VERSION ""

NS_ :

BS_:

BU_: TCU_FB5 RFA_BLEM GWM _delete GENERIC TSTR
VAL_TABLE_ PaaKMyKeyChng_D_Stat 3 "NotUsed" 2 "ClearAll" 1 "MyKey" 0 "Null" ;
VAL_TABLE_ VehOnSrc_D_Stat 15 "NotUsed_11" 14 "NotUsed_10" 13 "NotUsed_9" 12 "NotUsed_8" 11 "NotUsed_7" 10 "NotUsed_6" 9 "EsclRssd" 8 "AutonomousVehicle" 7 "SecureIdle" 6 "FleetVehicleInhibit" 5 "StolenVehicleInhibit" 4 "OverTheAir" 3 "RemoteParkAssist" 2 "RemoteStart" 1 "Manual" 0 "Off" ;
VAL_TABLE_ PaakAddErase_D_Rq 3 "EraseAll" 2 "Erase" 1 "Add" 0 "Null" ;
VAL_TABLE_ KeyPadCodeProg_D_Rq 7 "NotUsed_3" 6 "NotUsed_2" 5 "NotUsed_1" 4 "DeleteAll" 3 "Delete" 2 "Add" 1 "ProgrammingMode" 0 "Null" ;
VAL_TABLE_ KeyPadCodeProg_D_Stat 7 "NotUsed_2" 6 "Duplicate" 5 "ProgrammingFailure" 4 "DeleteAll" 3 "Delete" 2 "Add" 1 "LearningMode" 0 "NormalMode" ;
VAL_TABLE_ FobTrgtZone_D_Rq 15 "NotUsed_9" 14 "NotUsed_8" 13 "NotUsed_7" 12 "NotUsed_6" 11 "NotUsed_5" 10 "NotUsed_4" 9 "NotUsed_3" 8 "NotUsed_2" 7 "NotUsed_1" 6 "Approach" 5 "RearInterior" 4 "RearExterior" 3 "Passenger" 2 "Driver" 1 "Interior" 0 "Null" ;
VAL_TABLE_ FobTrgtType_D_Rq 7 "NotUsed_4" 6 "NotUsed_3" 5 "NotUsed_2" 4 "NotUsed_1" 3 "Polling" 2 "Registry" 1 "Crypto" 0 "Null" ;
VAL_TABLE_ ModemReset_D_Rq 15 "NotUsed_11" 14 "NotUsed_10" 13 "NotUsed_9" 12 "NotUsed_8" 11 "NotUsed_7" 10 "NotUsed_6" 9 "NotUsed_5" 8 "NotUsed_4" 7 "NotUsed_3" 6 "BrandConnectReset2" 5 "BrandConnectReset1" 4 "CcsReset" 3 "OnlineTrafficReset" 2 "PaakReset" 1 "WifiHotspotReset" 0 "Null" ;
VAL_TABLE_ RstrnOnPsngr_D_RqMnu 15 "Faulty" 14 "NotUsed_11" 13 "NotUsed_10" 12 "ConfiguredOff" 11 "NotUsed_9" 10 "On" 9 "NotUsed_8" 8 "NotUsed_7" 7 "NotUsed_6" 6 "NotUsed_5" 5 "Off" 4 "NotUsed_4" 3 "NotUsed_3" 2 "NotUsed_2" 1 "NotUsed_1" 0 "NoAction" ;
VAL_TABLE_ Null_NotAvail_Avail 3 "NotUsed" 2 "Available" 1 "NotAvailable" 0 "Null" ;
VAL_TABLE_ DcacFaltMsgTxt_D2_Rq 63 "NotUsed_47" 17 "NotUsed_1" 16 "HevDerate" 15 "HvacOn" 14 "OvercurrentLP" 13 "EngineRun" 12 "Service" 11 "NotAvailable" 10 "PlugWarn" 9 "PlugWarnDrive" 8 "BreakerC" 7 "BreakerB" 6 "BreakerA" 5 "FuelLow" 4 "AcOnOutput" 3 "Temperature" 2 "Gfci" 1 "Overcurrent" 0 "Ok" ;
VAL_TABLE_ NotAvail_OffOn_Faulty 3 "Faulty" 2 "On" 1 "Off" 0 "NotAvailable" ;
VAL_TABLE_ RmtCtlPathPlan_D_Stat 7 "NotUsed_3" 6 "NotUsed_2" 5 "NotUsed_1" 4 "FinishedMovesExceeded" 3 "FinishedDistanceExceeded" 2 "Finished" 1 "Ongoing" 0 "None" ;
VAL_TABLE_ RmtCtlConfgSrc_D_Stat 7 "NotUsed_2" 6 "NotUsed_1" 5 "BPO" 4 "ApaHmi" 3 "FAP_Handover" 2 "User" 1 "None" 0 "NotDetermined" ;
VAL_TABLE_ RmtCtlAdas_D_Stat 7 "Paused" 6 "Abort" 5 "ManeuverFinished" 4 "EndPositionReached" 3 "Backward" 2 "Forward" 1 "ManeuverBegin" 0 "Inactive" ;
VAL_TABLE_ RmtCtlOrientAvail_D_ET 7 "NotUsed_3" 6 "NotUsed_2" 5 "NotUsed_1" 4 "Both" 3 "Backward" 2 "Forward" 1 "None" 0 "NotDetermined" ;
VAL_TABLE_ PrkMde_D_ET 3 "NotUsed" 2 "FreeDrive" 1 "ParkIn" 0 "None" ;
VAL_TABLE_ RmtCtlPrkInSlot_D_ET 7 "NotUsed_3" 6 "NotUsed_2" 5 "NotUsed_1" 4 "Right" 3 "Left" 2 "Rear" 1 "Front" 0 "None" ;
VAL_TABLE_ Orientation_D_ET 3 "NotUsed" 2 "Backward" 1 "Forward" 0 "Null" ;
VAL_TABLE_ MoveDir_D_ET 3 "NotUsed" 2 "Backward" 1 "Forward" 0 "None" ;
VAL_TABLE_ RmtCtlSns_D_Stat 3 "Zone3" 2 "Zone2" 1 "Zone1" 0 "Off" ;
VAL_TABLE_ ApaMsgTxt_D2_Stat 15 "ReducedFunction" 14 "TrailerFeatureNotAvailable" 13 "AcceleratorPedalInactive" 12 "SensorsBlocked" 11 "TrailerAttached" 10 "TcsDeactivated" 9 "WheelSlip" 8 "HighInclination" 7 "DoorOpen" 6 "SteeringInteraction" 5 "WrongDirection" 4 "SpeedLimitExceeded" 3 "BrakeEvent" 2 "ObstacleInPath" 1 "WaitForSteering" 0 "None" ;
VAL_TABLE_ ApaDrvRq1MsgTxt_D_Rq 7 "NotUsed" 6 "ExitVehicle" 5 "PressApaButton" 4 "ShiftToP" 3 "ShiftToN" 2 "ShiftToD" 1 "ShiftToR" 0 "NoRequest" ;
VAL_TABLE_ DisplayMode 3 "NotUsed" 2 "FullScreen" 1 "Menu" 0 "Off" ;
VAL_TABLE_ ApaSys_D2_Stat 15 "NotUsed_5" 14 "NotUsed_4" 13 "NotUsed_3" 12 "NotUsed_2" 11 "NotUsed_1" 10 "NoSideSelectable" 9 "RightSideSelectable" 8 "LeftSideSelectable" 7 "BothSidesSelectable" 6 "Faulty" 5 "Finished" 4 "Cancelled" 3 "NotAvailable" 2 "Overspeed" 1 "Pause" 0 "NormalOperation" ;
VAL_TABLE_ ApaDrvRq2MsgTxt_D_Rq 15 "NotUsed_7" 14 "NotUsed_6" 13 "NotUsed_5" 12 "NotUsed_4" 11 "NotUsed_3" 10 "NotUsed_2" 9 "NotUsed_1" 8 "CloseDoor" 7 "TakeControl" 6 "ReleaseEpb" 5 "ReleaseSteering" 4 "ReleaseBrake" 3 "DriveBackward" 2 "DriveForward" 1 "Stop" 0 "NoRequest" ;
VAL_TABLE_ ApaSlotTrgt_D_Stat 15 "NotUsed_7" 14 "NotUsed_6" 13 "NotUsed_5" 12 "NotUsed_4" 11 "NotUsed_3" 10 "NotUsed_2" 9 "NotUsed_1" 8 "Front" 7 "Rear" 6 "Right3" 5 "Right2" 4 "Right1" 3 "Left3" 2 "Left2" 1 "Left1" 0 "None" ;
VAL_TABLE_ ChrgStat_D2_Dsply 15 "ChargeStopCommanded" 14 "ChargeStartCommanded" 13 "ChargeTargetReached" 12 "DriveConditioning" 11 "CabinPreconditioning" 10 "ChargingSystemMaintain" 9 "ChargingInductive" 8 "ChargingDCFastCharge" 7 "ChargingAC" 6 "ChargeScheduled" 5 "EvsePaused" 4 "EvseNotDetected" 3 "EvseNotCompatible" 2 "FaultOutsideCar" 1 "FaultInsideCar" 0 "NotReady" ;
VAL_TABLE_ NoRequest_Mode1_2_3 3 "Mode_3" 2 "Mode_2" 1 "Mode_1" 0 "NoRequest" ;
VAL_TABLE_ Off_On_NotUsed 3 "NotUsed_2" 2 "NotUsed_1" 1 "On" 0 "Off" ;
VAL_TABLE_ Mtr2State_D_ActlMntr 7 "Faulty" 6 "NoDataExists" 5 "NotUsed_1" 4 "ReadinessState" 3 "DeactivationState" 2 "PowerGeneration" 1 "PowerConsumption" 0 "Null" ;
VAL_TABLE_ HybVehMde_D_ActlMntr 7 "Faulty" 6 "NoDataExists" 5 "NotUsed_2" 4 "NotUsed_1" 3 "Fuel" 2 "HybridElectric" 1 "AllElectric" 0 "Null" ;
VAL_TABLE_ ChrgStat_D_ActlMntr 7 "Faulty" 6 "NoDataExists" 5 "NotUsed" 4 "ChargingCompleted" 3 "NotCharging" 2 "ChargingInDrivingState" 1 "ChargingInParkingState" 0 "Null" ;
VAL_TABLE_ Inactive_Enable_Disable_NotUsed 0 "Inactive" 2 "Disable" 1 "Enable" ;
VAL_TABLE_ TrailCtl_D_Stat 7 "Faulty" 6 "DescentOnly" 5 "EnabledDeny" 4 "StandbyOverThreshold" 3 "StandbyOverride" 2 "Active" 1 "EnabledDescent" 0 "Off" ;
VAL_TABLE_ ChrgOvrdExitScrn_D_Rq 3 "NotUsed_1" 2 "Request_override" 1 "Do_not_request_override" 0 "Inactive" ;
VAL_TABLE_ PaakTrgtType_D_Rq 7 "NotUsed_4" 6 "NotUsed_3" 5 "NotUsed_2" 4 "NotUsed_1" 3 "Polling" 2 "Registry" 1 "Crypto" 0 "Null" ;
VAL_TABLE_ PaakTrgtZone_D_Rq 15 "NotUsed_9" 14 "NotUsed_8" 13 "NotUsed_7" 12 "NotUsed_6" 11 "NotUsed_5" 10 "NotUsed_4" 9 "NotUsed_3" 8 "NotUsed_2" 7 "NotUsed_1" 6 "Approach" 5 "RearInterior" 4 "RearExterior" 3 "Passenger" 2 "Driver" 1 "Interior" 0 "Null" ;
VAL_TABLE_ PaakTrgtData_D_Rq 5 "NotUsed_2" 4 "Not_Used1" 3 "Target1_IdBlock2" 2 "Target1_IdBlock1" 1 "Challenge" 0 "Idle" 7 "NotUsed_4" 6 "NotUsed_3" ;
VAL_TABLE_ PaakCtlActv_D_Rq 31 "NotUsed_13" 30 "NotUsed_12" 29 "NotUsed_11" 28 "NotUsed_10" 27 "NotUsed_9" 26 "NotUsed_8" 25 "NotUsed_7" 24 "NotUsed_6" 23 "NotUsed_5" 22 "NotUsed_4" 21 "NotUsed_3" 20 "TrunkFrontRelease" 19 "RemoteStop" 18 "RemoteStart" 17 "PowerDecklid" 16 "RightPowerSlidingDoor" 15 "LeftPowerSlidingDoor" 14 "PowerLiftgate" 13 "GlobalClose" 12 "GlobalOpen" 11 "PanicOff" 10 "PanicOn" 9 "LiftgateGlassRelease" 8 "LiftgateRelease" 7 "DecklidRelease" 6 "DoubleLock" 5 "LockAll" 4 "UnlockAllDoorsPlusCargo" 3 "UnlockCargoDoor" 2 "UnlockAllDoors" 1 "UnlockDriverDoor" 0 "Null" ;
VAL_TABLE_ Null_Invalid_Valid 3 "NotUsed" 2 "Valid" 1 "Invalid" 0 "Null" ;
VAL_TABLE_ PaakCtlData_D_Stat 7 "NotUsed_3" 6 "NotUsed_2" 5 "NotUsed_1" 4 "Response" 3 "EchoTargetIdBlock1" 2 "RequestTargetIdBlock2" 1 "RequestTargetIdBlock1" 0 "Idle" ;
VAL_TABLE_ NoInhibit_Inhibit 1 "Inhibit" 0 "NoInhibit" ;
VAL_TABLE_ Disp_LangSel2_Rq 32 "Indian_English" 31 "Thai" 30 "Slovak" 29 "Arabic" 28 "Taiwanese" 27 "Mandarin_Chinese" 26 "Korean" 25 "AU_English" 24 "Japanese" 23 "Braz_Portuguese" 22 "EU_Portuguese" 21 "Finish" 20 "Norwegian" 19 "Danish" 18 "Swedish" 17 "Hungarian" 16 "Greek" 15 "Czech" 14 "Polish" 13 "Flemish" 12 "Dutch" 11 "Russian" 10 "Turkish" 9 "Mex_Spanish" 8 "EU_Spanish" 7 "Cana_French" 6 "EU_French" 5 "Italian" 4 "German" 3 "NA_English" 2 "UK_English" 1 "Unknown" 0 "Invalid" ;
VAL_TABLE_ LongTermParking_Rq 2 "On" 1 "Off" 0 "Inactive" ;
VAL_TABLE_ Null_Extend_Retract 3 "NotUsed" 2 "Retract" 1 "Extend" 0 "Null" ;
VAL_TABLE_ VehInhbtMde_D_Stat 7 "NotUsed_3" 6 "NotUsed_2" 5 "NotUsed_1" 4 "FullVehicleOta" 3 "Iviota" 2 "SyncOta" 1 "NoOtaSupport" 0 "Unconfigured" ;
VAL_TABLE_ PaakLoclzd_D_Stat 15 "NotUsed_12" 14 "NotUsed_11" 13 "NotUsed_10" 12 "NotUsed_9" 11 "NotUsed_8" 10 "NotUsed_7" 9 "NotUsed_6" 8 "NotUsed_5" 7 "NotUsed_4" 6 "NotUsed_3" 5 "NotUsed_2" 4 "NotUsed_1" 3 "FullLoc" 2 "PausedLoc" 1 "MaintainLink" 0 "BackgroundScan" ;
VAL_TABLE_ KeyPadCodeDgt1_D_Stat 15 "NotUsed_4" 14 "NotUsed_3" 13 "NotUsed_2" 12 "NotUsed_1" 11 "Button7_8and9_0" 10 "Button0" 9 "Button9_0or9" 8 "Button8" 7 "Button7_8or7" 6 "Button6" 5 "Button5_6or5" 4 "Button4" 3 "Button3_4or3" 2 "Button2" 1 "Button1_2or1" 0 "EndofString" ;
VAL_TABLE_ SelDrvMdeChassis2_D_Rq 31 "Faulty" 30 "NotUsed17" 29 "NotUsed16" 28 "NotUsed15" 27 "NotUsed14" 26 "NotUsed13" 25 "NotUsed12" 24 "NotUsed11" 23 "NotUsed10" 22 "NotUsed9" 21 "NotUsed8" 20 "NotUsed7" 19 "NotUsed6" 18 "NotUsed5" 17 "NotUsed4" 16 "OnePedalDrive" 15 "DragMode" 14 "RoughRoadMode" 13 "TrackMode" 12 "HighSpeedDesertMode" 11 "TowHaulMode" 10 "RockCrawlMode" 9 "SandMode" 8 "MudAndRutsMode" 7 "LowMuMode" 6 "ComfortAdaptiveMode" 5 "ComfortMode" 4 "SportAdaptiveMode" 3 "SportMode" 2 "EconomyMode" 1 "NormalAdaptiveMode" 0 "NormalMode" ;
VAL_TABLE_ TelematicsSrvc_D_St 7 "NotUsed" 6 "NotifyNotActivatedYet" 5 "NotActivatedYet" 4 "NotifyExpired" 3 "Expired" 2 "ExpiringSoon" 1 "Active" 0 "Null" ;
VAL_TABLE_ TCU_ESN_D_Rq 3 "NotUsed" 2 "TCU_ESN_Request" 1 "NoRequest" 0 "Inactive" ;
VAL_TABLE_ FactoryReset_Rq 1 "ResetFactoryDefaults" 0 "Inactive" ;
VAL_TABLE_ Telematics_D_Falt 7 "NotUsed_5" 6 "NotUsed_4" 5 "NotUsed_3" 4 "NotUsed_2" 3 "NotUsed_1" 2 "RunTimeError" 1 "ChipsetInitializationFailu" 0 "Null" ;
VAL_TABLE_ Null_NotConnected_Conn 3 "NotUsed" 2 "Connected" 1 "NotConnected" 0 "Null" ;
VAL_TABLE_ Null_Disable_Enable 3 "NotUsed" 2 "Enable" 1 "Disable" 0 "Null" ;
VAL_TABLE_ UltraFreshCabn_D_Stat 7 "NotUsed_2" 6 "NotUsed_1" 5 "NotSupported" 4 "Interrupted" 3 "Complete" 2 "Active" 1 "Inactive" 0 "Null" ;
VAL_TABLE_ WifiHtsptTrial_D_RqDrv 3 "NotUsed_1" 2 "StopReminders" 1 "RemindMeLater" 0 "Null" ;
VAL_TABLE_ ModemTechnology_D2_Stat 7 "Lte" 6 "HspaPlus" 5 "Umts" 4 "Edge" 3 "Gprs" 2 "Gsm" 1 "NoNetwork" 0 "Null" ;
VAL_TABLE_ NoData_Faulty_3FFE_3FFF 16383 "Faulty" 16382 "NoDataExists" ;
VAL_TABLE_ EmgcyCall_D_Stat 7 "NotUsed_3" 6 "NotUsed_2" 5 "NotUsed_1" 4 "ManualEmergencyCall" 3 "AutoEmergencyCall" 2 "NoEvent" 1 "EmergencyCallNotSupported" 0 "Null" ;
VAL_TABLE_ GearLvr_D_ActlDrv 15 "Fault" 14 "Unknown_Position" 13 "NotUsed_2" 12 "NotUsed_1" 11 "Range6" 10 "Range5" 9 "Range4" 8 "Range3_M3_L3" 7 "Range2_M2_L2" 6 "Range1_M1_L1" 5 "Low" 4 "Sport_DriveSport_Mposition" 3 "Drive" 2 "Neutral" 1 "Reverse" 0 "Park" ;
VAL_TABLE_ TrnPrkSys_D_Actl 15 "Faulty" 14 "NotUsed_5" 13 "NotUsed_4" 12 "NotUsed_3" 11 "NotUsed_2" 10 "NotUsed_1" 9 "FrequencyError" 8 "OutOfRangeHigh" 7 "OutOfRangeLow" 6 "Override" 5 "OutOfPark" 4 "TransitionCloseToOutOfPark" 3 "AtNoSpring" 2 "TransitionCloseToPark" 1 "Park" 0 "NotKnown" ;
VAL_TABLE_ OKLowUnknownInvalid 3 "Invalid" 2 "Unknown" 1 "Low" 0 "OK" ;
VAL_TABLE_ PrkAidDrvDir_D_Stat 7 "NotUsed_2" 6 "NotUsed_1" 5 "BackwardNegative" 4 "ForwardNegative" 3 "BackwardPositive" 2 "ForwardPositive" 1 "NoMotion" 0 "DirectionNotKnown" ;
VAL_TABLE_ EmgcyCallHmi_D_Stat 15 "NotUsed_1" 14 "Standby" 13 "Disabled" 12 "Malfunction" 11 "CallCompleted" 10 "CallDisconnected" 9 "CallNotPossible" 8 "CallCancelled" 7 "CallRetry" 6 "CallConnected" 5 "CallInProgress" 4 "CallMsdTransfer" 3 "CallDial" 2 "CallCancelTimer" 1 "NoEvent" 0 "Null" ;
VAL_TABLE_ EmgcyCallMute_D_Stat 7 "NotUsed4" 6 "NotUsed3" 5 "NotUsed2" 4 "NotUsed1" 3 "ManualEmergencyCallMute" 2 "AutomaticEmergencyCallMute" 1 "EmergencyCallUnmute" 0 "Null" ;
VAL_TABLE_ WifiHtsptEnbl_D_Rq 3 "Not used" 2 "On" 1 "Off" 0 "Null" ;
VAL_TABLE_ WifiHtsptVisbl_D_Rq 3 "Not used" 2 "On" 1 "Off" 0 "Null" ;
VAL_TABLE_ WifiRemoveDevc_D_Rq 3 "NotUsed_1" 2 "FromBlockedList" 1 "FromConnectedList" 0 "Null" ;
VAL_TABLE_ WifiHtsptEnbl_D_Stat 3 "OnDisabled" 2 "On" 1 "Off" 0 "Null" ;
VAL_TABLE_ WifiDevcListNew_B_Stat 1 "Available" 0 "NotAvailable" ;
VAL_TABLE_ WifiHtsptScrty_D_Rq 3 "NotUsed_1" 2 "Wapi" 1 "Wpa2_Wpa" 0 "Null" ;
VAL_TABLE_ WifiDevcList_D_Rq 3 "NoEntry" 2 "BlockedList" 1 "ConnectedList" 0 "Null" ;
VAL_TABLE_ WifiCarrierInfo_B_Rq 1 "Request" 0 "No  request" ;
VAL_TABLE_ WifiHtsptScrty_D_Stat 3 "NotUsed_1" 2 "Wapi" 1 "Wpa2_Wpa" 0 "Null" ;
VAL_TABLE_ WifiDataUsage_D_Rq 3 "RetriveDataFromBackend" 2 "RefreshData" 1 "CurrentData" 0 "Null" ;
VAL_TABLE_ WifiHtsptVisbl_D_Stat 3 "Not  used" 2 "On" 1 "Off" 0 "Null" ;
VAL_TABLE_ ModemSigStren_D_Stat 7 "NotUsed_1" 6 "NotDetermined" 5 "FiveBars" 4 "FourBars" 3 "ThreeBars" 2 "TwoBars" 1 "OneBar" 0 "ZeroBars" ;
VAL_TABLE_ WifiHtsptMacAddr_B_Rq 1 "Request" 0 "No request" ;
VAL_TABLE_ WifiDataUsage_D_Stat 3 "PercentDataUsed" 2 "DataPlanExpired" 1 "FreeTrialPeriodWaiting" 0 "Null" ;
VAL_TABLE_ Closed_Open_Active_Denied 3 "Denied" 2 "Active" 1 "Open" 0 "Closed" ;
VAL_TABLE_ Fault_Occupied_Empty_Un 3 "Unknown" 2 "Empty" 1 "Occupied" 0 "Fault" ;
VAL_TABLE_ KeyOffMde_D_Actl 15 "NotUsed_11" 14 "NotUsed_10" 13 "NotUsed_9" 12 "NotUsed_8" 11 "NotUsed_7" 10 "NotUsed_6" 9 "NotUsed_5" 8 "NotUsed_4" 7 "NotUsed_3" 6 "NotUsed_2" 5 "NotUsed_1" 4 "CriticalBattery" 3 "Hibernate" 2 "Transport" 1 "Factory" 0 "Normal" ;
VAL_TABLE_ SelDrvMdeAwd_D_Rq 31 "Faulty" 30 "NotUsed_17" 29 "NotUsed_16" 28 "NotUsed_15" 27 "NotUsed_14" 26 "NotUsed_13" 25 "NotUsed_12" 24 "NotUsed_11" 23 "NotUsed_10" 22 "NotUsed_9" 21 "NotUsed_8" 20 "CustomMode" 19 "OnePedalDrive" 18 "DragMode" 17 "EvLaterChargeMode" 16 "EvNowMode" 15 "TrackMode" 14 "RoughRoadMode" 13 "NotAvailable" 12 "HighSpeedDesertMode_Baja" 11 "SportAdaptiveMode" 10 "RockCrawlMode" 9 "MudRutsMode" 8 "SandMode" 7 "EconomyMode" 6 "GrassGravelSnow" 5 "TowHaulMode" 4 "SportMode" 3 "Normal_4L" 2 "Normal_4A" 1 "Normal_2H" 0 "NormalMode" ;
VAL_TABLE_ SelDrvMdePt_D_Rq 31 "Faulty" 30 "NotUsed15" 29 "NotUsed14" 28 "NotUsed13" 27 "NotUsed12" 26 "NotUsed11" 25 "NotUsed10" 24 "NotUsed9" 23 "NotUsed8" 22 "NotUsed7" 21 "CustomMode" 20 "TrackMode" 19 "OnePedalDrive" 18 "EvLaterChargerMode" 17 "EvNowMode" 16 "DragMode" 15 "HighSpeedDesertMode_Baja" 14 "SportAdaptiveMode" 13 "NotAvailable_13" 12 "NotAvailable_12" 11 "NotAvailable_11" 10 "NotAvailable_10" 9 "RockCrawlMode" 8 "MudRutsMode" 7 "SandMode" 6 "EconomyMode" 5 "GrassGravelSnow" 4 "NotAvailable_04" 3 "TowHaulMode" 2 "NotAvailable_02" 1 "SportMode" 0 "NormalMode" ;
VAL_TABLE_ OffOnOutOfRange 3 "NotUsed" 2 "OutOfRange" 1 "On" 0 "Off" ;
VAL_TABLE_ NoMessage_Msg1_15 15 "Message15" 14 "Message14" 13 "Message13" 12 "Message12" 11 "Message11" 10 "Message10" 9 "Message9" 8 "Message8" 7 "Message7" 6 "Message6" 5 "Message5" 4 "Message4" 3 "Message3" 2 "Message2" 1 "Message1" 0 "NoMessage" ;
VAL_TABLE_ SelDrvMdeChassis_D_Rq 31 "Faulty" 30 "NotUsed17" 29 "NotUsed16" 28 "NotUsed15" 27 "NotUsed14" 26 "NotUsed13" 25 "NotUsed12" 24 "NotUsed11" 23 "NotUsed10" 22 "NotUsed9" 21 "NotUsed8" 20 "NotUsed7" 19 "NotUsed6" 18 "NotUsed5" 17 "NotUsed4" 16 "OnePedalDrive" 15 "DragMode" 14 "RoughRoadMode" 13 "TrackMode" 12 "HighSpeedDesertMode" 11 "TowHaulMode" 10 "RockCrawlMode" 9 "SandMode" 8 "MudAndRutsMode" 7 "LowMuMode" 6 "ComfortAdaptiveMode" 5 "ComfortMode" 4 "SportAdaptiveMode" 3 "SportMode" 2 "EconomyMode" 1 "NormalAdaptiveMode" 0 "NormalMode" ;
VAL_TABLE_ NotAvailable_Available 1 "Available" 0 "NotAvailable" ;
VAL_TABLE_ ApaBrk_D_Stat 3 "Denied" 2 "Active" 1 "Open" 0 "Closed" ;
VAL_TABLE_ Off_On_Unknown_Invalid 3 "Invalid" 2 "Unknown" 1 "On" 0 "Off" ;
VAL_TABLE_ BrkBstrVac_D_Stat 3 "NotUsed" 2 "BoosterVacEstimator" 1 "BoosterVacSensor" 0 "NoBoosterVacuumMonitor" ;
VAL_TABLE_ PrkBrkMsgTxt_D_Rq 15 "Message15" 14 "Message14" 13 "Message13" 12 "Message12" 11 "Message11" 10 "Message10" 9 "Message9" 8 "Message8" 7 "Message7" 6 "Message6" 5 "Message5" 4 "Message4" 3 "Message3" 2 "Message2" 1 "Message1" 0 "No_Message" ;
VAL_TABLE_ AutoHoldMsgTxt_D_Rq 15 "Message15" 14 "Message14" 13 "Message13" 12 "Message12" 11 "Message11" 10 "Message10" 9 "Message9" 8 "Message8" 7 "Message7" 6 "Message6" 5 "Message5" 4 "Message4" 3 "Message3" 2 "Message2" 1 "Message1" 0 "NoMessage" ;
VAL_TABLE_ AutoHoldMde_D_Ind 3 "Indication_3" 2 "Indication_2" 1 "Indication_1" 0 "Off" ;
VAL_TABLE_ BrkPadMsgTxt_D_Rq 3 "Faulty" 2 "PadsOk" 1 "ReplacePads" 0 "Null" ;
VAL_TABLE_ LsmcBrkDecel_D_Stat 7 "NotUsed_3" 6 "NotUsed_2" 5 "NotUsed_1" 4 "Denied" 3 "FaultDegraded" 2 "FaultExt" 1 "On" 0 "Off" ;
VAL_TABLE_ BrkLineLck_D_Stat 7 "NotUsed_3" 6 "NotUsed_2" 5 "NotUsed_1" 4 "NotAvailable" 3 "Off" 2 "Engaged" 1 "Initiated" 0 "Available" ;
VAL_TABLE_ BrkDrvMde_D_Rq 7 "Faulty" 6 "RockCrawl" 5 "Baja" 4 "DragOrMudAndSand" 3 "Track" 2 "Snow_Wet" 1 "Sport" 0 "Normal" ;
VAL_TABLE_ NoYesNoDataFaulty 3 "Faulty" 2 "NoDataExists" 1 "Yes" 0 "No" ;
VAL_TABLE_ Null_Off_On 3 "NotUsed" 2 "On" 1 "Off" 0 "Null" ;
VAL_TABLE_ TrlrAidMsgTxt_D_Rq 31 "Message31" 30 "Message30" 29 "Message29" 28 "Message28" 27 "Message27" 26 "Message26" 25 "Message25" 24 "Message24" 23 "Message23" 22 "Message22" 21 "Message21" 20 "Message20" 19 "Message19" 18 "Message18" 17 "Message17" 16 "Message16" 15 "Message15" 14 "Message14" 13 "Message13" 12 "Message12" 11 "Message11" 10 "Message10" 9 "Message9" 8 "Message8" 7 "Message7" 6 "Message6" 5 "Message5" 4 "Message4" 3 "Message3" 2 "Message2" 1 "Message1" 0 "NoMessage" ;
VAL_TABLE_ Invalid_7F 127 "Invalid" ;
VAL_TABLE_ VehStab_D_Stat 15 "Faulty" 14 "No_Data_Exists" 13 "NotUsed6" 12 "NotUsed5" 11 "NotUsed4" 10 "NotUsed3" 9 "NotUsed2" 8 "Combined_OS_and_US" 7 "High_SSRA_no_OS" 6 "Straight" 5 "Post_Oversteer" 4 "Post_Transition" 3 "Countersteer" 2 "Understeer" 1 "Oversteer" 0 "Linear" ;
VAL_TABLE_ DieslPrtc2_D_RqDsply 15 "NotUsed4" 14 "NotUsed3" 13 "NotUsed2" 12 "NotUsed1" 11 "OCR_ExhFilterClean_Stopped" 10 "OCR_ExhFilterCleaned" 9 "RgnOff_AtLimit" 8 "RgnOff_Overloaded" 7 "RgnOff_Loaded" 6 "Exhaust_Filter_Full" 5 "DPF_Overlimit" 4 "DPF_AtLimit" 3 "ExhFilter_Drive_Completed" 2 "Cleaning_Exhaust_Filter" 1 "DPF_Overloaded" 0 "DPF_Normal_Operation" ;
VAL_TABLE_ NoData_Faulty_3E_3F 63 "Faulty" 62 "NoDataExists" ;
VAL_TABLE_ NoData_Faulty_1FFF_1FFE 8191 "Faulty" 8190 "NoDataExists" ;
VAL_TABLE_ TrnSrvcRqd_B_Rq 1 "On" 0 "Off" ;
VAL_TABLE_ NoData_Faulty_FE_FF 255 "Faulty" 254 "NoDataExists" ;
VAL_TABLE_ HvacPrecondRecirc_D_Rq 3 "Last_User_Setting" 2 "Auto" 1 "Recirc" 0 "Outside" ;
VAL_TABLE_ HvacPrecondAC_D_Rq 3 "Last_User_Setting" 2 "Auto" 1 "On" 0 "Off" ;
VAL_TABLE_ HybMdeStat_D_Dsply 7 "NotUsed2" 6 "EV_Charge" 5 "EV_Override" 4 "Forced_EV_Mode" 3 "Forced_Charge_Sustain_Mode" 2 "Auto_Charge_Sustain_Mode" 1 "Auto_Charge_Deplete_Mode" 0 "Null_State" ;
VAL_TABLE_ ConsTipUnitPt_D_Dsply 3 "NotUsed" 2 "FuelEconomy" 1 "Distance" 0 "Percentage" ;
VAL_TABLE_ NoData_Faulty_FFFE_FFFF 65535 "Faulty" 65534 "NoDataExists" ;
VAL_TABLE_ NoData_Faulty_FFE_FFF 4095 "Faulty" 4094 "NoDataExists" ;
VAL_TABLE_ NoData_Faulty_7FFE_7FFF 32767 "Faulty" 32766 "NoDataExists" ;
VAL_TABLE_ NoData_Faulty_3FE_3FF 1023 "Faulty" 1022 "NoDataExists" ;
VAL_TABLE_ RmtCtlBody_D_Stat 15 "NotUsed_6" 14 "NotUsed_5" 13 "NotUsed_4" 12 "NotUsed_3" 11 "NotUsed_2" 10 "NotUsed_1" 9 "Shutdown" 8 "ManeuverFinished" 7 "ReadyForResume" 6 "Pause" 5 "Maneuvering" 4 "ReadyForManeuvering" 3 "Activation" 2 "Initialize" 1 "Preparation" 0 "Disabled" ;
VAL_TABLE_ RmtCtlTrgt_D_Rq 3 "NotUsed" 2 "Null" 1 "RemoteParkAssist" 0 "ManeuverId" ;
VAL_TABLE_ RmtCtl_D_RqBody 7 "NotUsed_2" 6 "NotUsed_1" 5 "Error" 4 "Abort" 3 "PauseKeypad" 2 "PauseHazard" 1 "PauseDoorHandle" 0 "Null" ;
VAL_TABLE_ Null_NoPolling_Polling 3 "NotUsed" 2 "Polling" 1 "NoPolling" 0 "Null" ;
VAL_TABLE_ RmtCtl_D_Stat 15 "Faulty" 14 "NotUsed_5" 13 "NotUsed_4" 12 "NotUsed_3" 11 "NotUsed_2" 10 "NotUsed_1" 9 "Shutdown" 8 "ManeuverFinished" 7 "ReadyForResume" 6 "Pause" 5 "Maneuvering" 4 "ReadyForManeuvering" 3 "Activation" 2 "Initialize" 1 "Preparation" 0 "Disabled" ;
VAL_TABLE_ RmtCtlRngSet_D_Rq 3 "NotUsed" 2 "RangeSetB" 1 "RangeSetA" 0 "None" ;
VAL_TABLE_ OffPendingActiveNotUsed 3 "NotUsed" 2 "Active" 1 "Pending" 0 "Off" ;
VAL_TABLE_ BrkHold_D_Stat 7 "NotUsed_3" 6 "NotUsed_2" 5 "NotUsed_1" 4 "HeldSecondary" 3 "HeldSecure" 2 "Held" 1 "Inactive" 0 "Off" ;
VAL_TABLE_ Null_Left_Right 3 "NotUsed" 2 "Right" 1 "Left" 0 "Null" ;
VAL_TABLE_ NoRequest_Up 1 "Up" 0 "NoRequest" ;
VAL_TABLE_ UpDownNotUsedFaulty 3 "Faulty" 2 "NotUsed" 1 "Down" 0 "Up" ;
VAL_TABLE_ PtWakeReas_D_Stat 15 "NotUsed_9" 14 "NotUsed_8" 13 "NotUsed_7" 12 "NotUsed_6" 11 "NotUsed_5" 10 "NotUsed_4" 9 "NotUsed_3" 8 "NotUsed_2" 7 "NotUsed_1" 6 "ElapsedTime" 5 "ThirdPartyWakeup" 4 "DoorAjar" 3 "EarlyWake" 2 "NonMotiveStart" 1 "MotiveStart" 0 "Null" ;
VAL_TABLE_ ModemAuthrz_D_Stat2 3 "Null" 2 "RemoveKeys" 1 "Authorized" 0 "NotAuthorized" ;
VAL_TABLE_ PaakSerial_D2_Rq2 7 "NotUsed_3" 6 "NotUsed_1" 5 "NotUsed_1" 4 "PresentKeyDelivered" 3 "PresentReadyForKeyDelivery" 2 "PresentBlemProvAlertAck" 1 "PresentUnprovisioned" 0 "NotPresent" ;
VAL_TABLE_ Null_Band1_2 3 "NotUsed_1" 2 "Band_2" 1 "Band_1" 0 "Null" ;
VAL_TABLE_ Null_Error1_15 15 "Error15" 14 "Error14" 13 "Error13" 12 "Error12" 11 "Error11" 10 "Error10" 9 "Error9" 8 "Error8" 7 "Error7" 6 "Error6" 5 "Error5" 4 "Error4" 3 "Error3" 2 "Error2" 1 "Error1" 0 "Null" ;
VAL_TABLE_ WifiHtsptFq_D_Avail 7 "NotUsed_3" 6 "NotUsed_2" 5 "NotUsed_1" 4 "AllAvailable" 3 "Band_2_Only" 2 "Band_1_Only" 1 "AllRestricted" 0 "Null" ;
VAL_TABLE_ OpenClosedRetainDisable 3 "Disable" 2 "Retain" 1 "Closed" 0 "Open" ;
VAL_TABLE_ NoData_Fault_1FF_1FE 511 "Fault" 510 "NoDataExists" ;
VAL_TABLE_ EngIdlShutDown_D_Stat 3 "Not_used" 2 "Engine_Shutdown" 1 "Initiated_Countdown" 0 "Normal_Operation" ;
VAL_TABLE_ StopStrtDrvMde_D_Indic 3 "NotUsed" 2 "StartStop_IndirectDeselect" 1 "StopStart_Deselected" 0 "StopStart_Selected" ;
VAL_TABLE_ NoRequest_Request 1 "Request" 0 "NoRequest" ;
VAL_TABLE_ Fault_FFF_NoData 4094 "NoDataExists" 4095 "Fault" ;
VAL_TABLE_ WindowPosition 7 "Unused2" 6 "Unused1" 5 "Fully_Open" 4 "Bet60Percent_FullyOpen" 3 "Bet10Percent_60Percent" 2 "BetFully_10PercentOpen" 1 "Fully_Closed" 0 "Undefined" ;
VAL_TABLE_ OffOnNoDataUnused 3 "Unused" 2 "NoDataExists" 1 "On" 0 "Off" ;
VAL_TABLE_ Null_False_True 3 "NotUsed" 2 "True" 1 "False" 0 "Null" ;
VAL_TABLE_ NoMessage_DisplayMessage 1 "DisplayMessage" 0 "NoMessage" ;
VAL_TABLE_ EngSrvcRqd_B_Rq 1 "Engine_Service_Required" 0 "No_engine_service_required" ;
VAL_TABLE_ GearRvrse_D_Actl 7 "Fault" 6 "NotUsed_3" 5 "NotUsed_2" 4 "NotUsed_1" 3 "Active_confirmed" 2 "Active_not_confirmed" 1 "Inactive_confirmed" 0 "Inactive_not_confirmed" ;
VAL_TABLE_ SideDetect_BLIS_Off_On 2 "BLIS_On_Second_Warning_ON" 1 "BLIS_On_Second_Warning_OFF" 0 "Off" ;
VAL_TABLE_ False_True 1 "True" 0 "False" ;
VAL_TABLE_ HtrnWarnLamp_B_Dsply 1 "On" 0 "Off" ;
VAL_TABLE_ HtrnSrvcRqd_B_Dsply 1 "On" 0 "Off" ;
VAL_TABLE_ Disp_LangSel_St 31 "Thai" 30 "Slovak" 29 "Arabic" 28 "Taiwanese" 27 "Mandarin_Chinese" 26 "Korean" 25 "AU_English" 24 "Japanese" 23 "Braz_Portuguese" 22 "EU_Portuguese" 21 "Finish" 20 "Norwegian" 19 "Danish" 18 "Swedish" 17 "Hungarian" 16 "Greek" 15 "Czech" 14 "Polish" 13 "Flemish" 12 "Dutch" 11 "Russian" 10 "Turkish" 9 "Mex_Spanish" 8 "EU_Spanish" 7 "Cana_French" 6 "EU_French" 5 "Italian" 4 "German" 3 "NA_English" 2 "UK_English" 1 "Unknown" 0 "Invalid" ;
VAL_TABLE_ HMI_HMIMode_St 7 "NotUsed2" 6 "NotUsed1" 5 "Load_Shed_Active" 0 "Invalid" 1 "OffMode" 2 "On" 3 "Phone" 4 "Climate" ;
VAL_TABLE_ BattChrgInhbt_D_Rq 3 "MaintainTargetSoc" 2 "NotUsed" 1 "InhibitChargingThermal" 0 "Enable_Charging" ;
VAL_TABLE_ NoData_Fault_FFFE_FFFF 65535 "Fault" 65534 "NoDataExists" ;
VAL_TABLE_ Fault_1FFF 8191 "Fault" ;
VAL_TABLE_ StopStrtIODTxt_D_Rq 31 "Message31" 30 "Message30" 29 "Message29" 28 "Message28" 27 "Message27" 26 "Message26" 25 "Message25" 24 "Message24" 23 "Message23" 22 "Message22" 21 "Message21" 20 "Message20" 19 "Message19" 18 "Message18" 17 "Message17" 16 "Message16" 15 "Message15" 14 "Message14" 13 "Message13" 12 "Message12" 11 "Message11" 10 "Message10" 9 "Message9" 8 "Message8" 7 "Message7" 6 "Message6" 5 "Message5" 4 "Message4" 3 "Message3" 2 "Message2" 1 "Message1" 0 "NoMessage" ;
VAL_TABLE_ DrvSte_D_Stat 15 "NotUsed10" 14 "NotUsed9" 13 "NotUsed8" 12 "NotUsed7" 11 "NotUsed6" 10 "NotUsed5" 9 "NotUsed4" 8 "NotUsed3" 7 "NotUsed2" 6 "NotUsed1" 5 "Request_Active" 4 "Ignition_Off" 3 "DSR_in_Normal_Idle_Mode" 2 "EPAS_Comm_Disturbed" 1 "DSR_Request_Not_Applicable" 0 "DSR_Deactivated" ;
VAL_TABLE_ LanguageSelect_St 32 "Indian_English" 31 "Thai" 30 "Slovak" 29 "Arabic" 28 "Taiwanese" 27 "Mandarin_Chinese" 26 "Korean" 25 "AU_English" 24 "Japanese" 23 "Braz_Portuguese" 22 "EU_Portuguese" 21 "Finish" 20 "Norwegian" 19 "Danish" 18 "Swedish" 17 "Hungarian" 16 "Greek" 15 "Czech" 14 "Polish" 13 "Flemish" 12 "Dutch" 11 "Russian" 10 "Turkish" 9 "Mex_Spanish" 8 "EU_Spanish" 7 "Cana_French" 6 "EU_French" 5 "Italian" 4 "German" 3 "NA_English" 2 "UK_English" 1 "Unknown" 0 "Invalid" ;
VAL_TABLE_ Backlit_LED_Status 15 "Unused3" 14 "Unused2" 13 "Unused1" 12 "Night_12" 11 "Night_11" 10 "Night_10" 9 "Night_9" 8 "Night_8" 7 "Night_7" 6 "Night_6" 5 "Night_5" 4 "Night_4" 3 "Night_3" 2 "Night_2" 1 "Night_1" 0 "Off" ;
VAL_TABLE_ Veh_Lock_Status 3 "UNLOCK_DRV" 2 "UNLOCK_ALL" 1 "LOCK_ALL" 0 "LOCK_DBL" ;
VAL_TABLE_ CrashEvnt_D_Stat 3 "Invalid" 2 "Fuel_Cutoff_Event" 1 "Deploy_Event" 0 "No_Event" ;
VAL_TABLE_ HvacPrecondBlwr_D_Rq 15 "NotUsed6" 14 "NotUsed5" 13 "NotUsed4" 12 "NotUsed3" 11 "NotUsed2" 10 "NotUsed1" 9 "Last_User_Setting" 8 "Auto" 7 "Speed7" 6 "Speed6" 5 "Speed5" 4 "Speed4" 3 "Speed3" 2 "Speed2" 1 "Speed1" 0 "Off" ;
VAL_TABLE_ HvacPrecondMode_D_Rq 15 "NotUsed4" 14 "NotUsed3" 13 "NotUsed2" 12 "NotUsed1" 11 "Last_User_Settings" 10 "Auto" 9 "Max_Defrost" 8 "Windshield_Panel_Floor" 7 "Windshield_Panel" 6 "Windshield" 5 "Windshield_Floor" 4 "Floor" 3 "Panel_Floor" 2 "Panel" 1 "MAX_AC" 0 "Off" ;
VAL_TABLE_ EmgcyBrkLamp_D_Rq 3 "NotUsed" 2 "Active_at_standstill" 1 "Active_at_speed" 0 "Inactive" ;
VAL_TABLE_ LaHandsOff_D_Dsply 3 "Suppressed" 2 "Level2" 1 "Level1" 0 "HandsOn" ;
VAL_TABLE_ LifeCycMde_D_Actl 3 "Transport" 2 "NotUsed" 1 "Factory" 0 "Normal" ;
VAL_TABLE_ VehStrtStop_D_Rq 3 "NotUsed" 2 "Vehicle_Start_Request" 1 "Vehicle_Stop_Request" 0 "NoRequest" ;
VAL_TABLE_ PrkBrkStatus 7 "GeneralFault_MaintenceMode" 6 "ECD_by_Brake_ECU_Active" 5 "EPB_Limphome_Active" 4 "Rear_Caliper_Open" 3 "RWU_By_EPB_Active" 2 "Rear_Caliper_Transition" 1 "Rear_Caliper_Closed" 0 "Not_Supported" ;
VAL_TABLE_ PwSrcULoFalt_D_Stat 3 "Fault_No_Output" 2 "Fault_Reduced_Output" 1 "Fault_NonSpecific" 0 "No_Fault" ;
VAL_TABLE_ PwSysULoFalt_D_Stat 15 "Not_Used_6" 14 "LowBatterySOC" 13 "PSS_Shed2_Contin" 12 "Not_Used_4" 11 "Not_Used_3" 10 "Not_Used_2" 9 "BattMonitoringSensorFault" 8 "LowBattVoltDuringPwSrcOn" 7 "LowBatt2_PowerSaveMode" 6 "LowBatt1_Warning" 5 "Overvoltage" 4 "Fault_NoOutput" 3 "Fault_ReducedOutput" 2 "Fault_Nonspecific" 1 "Cluster_Proveout" 0 "No_Fault" ;
VAL_TABLE_ AccStopMde_D_Rq 3 "Stop_Mode_Active" 2 "EPBApplyOrBrakeReleaseWarn" 1 "Limit_Rolling_Speed" 0 "Stop_Mode_Not_Active" ;
VAL_TABLE_ PwPckTq_D_Stat 3 "PwPckOn_TqAvailable" 2 "StartInPrgrss_TqNotAvail" 1 "PwPckOn_TqNotAvailable" 0 "PwPckOff_TqNotAvailable" ;
VAL_TABLE_ Fault_FF 255 "Fault" ;
VAL_TABLE_ PsngrFrntDetct_D_Actl 3 "Unknown" 2 "Empty" 0 "Faulty" 1 "Occupied" ;
VAL_TABLE_ VedsEvnt_6 5 "Unused_3" 4 "Unused_2" 3 "Unused_1" 2 "NotBelted" 1 "Belted" 0 "NoEvent" 7 "Fault" 6 "NotSupported" ;
VAL_TABLE_ VedsEvnt_5 7 "Fault" 6 "NotSupported" 5 "Unused_3" 4 "Unused_2" 3 "Unused_1" 2 "ChildNotDetected" 1 "ChildDetected" 0 "NoEvent" ;
VAL_TABLE_ VedsEvnt_4 7 "Fault" 6 "NotSupported" 5 "Unused_3" 4 "Unused_2" 3 "Unused_1" 2 "NotDeployed" 1 "Deployed" 0 "NoEvent" ;
VAL_TABLE_ VedsEvnt_3 0 "NoEvent" 255 "Fault" 254 "NotSupported" ;
VAL_TABLE_ VedsEvnt_2 7 "Fault" 6 "NotSupported" 5 "Unused_3" 4 "Unused_2" 3 "Unused_1" 2 "Yes" 1 "No" 0 "NoEvent" ;
VAL_TABLE_ VedsEvnt_1 7 "Fault" 6 "NotSupported" 5 "Unused" 4 "Rolllover" 3 "Rear" 2 "Side" 1 "Frontal" 0 "NoEvent" ;
VAL_TABLE_ Veh_Lock_Requestor 31 "Walk_Away_Locking" 30 "Remote_Park_Assist" 29 "DoorsOffToOn_Smart_Unlock" 28 "Rgtm_Shutlock_Switch" 27 "Boundary_Alert" 26 "Transit_Vehicle_Relock" 25 "Transit_Cargo_Relock" 24 "Transit_Ajar_Lock" 23 "Diagnostics" 22 "Console_Lock" 21 "Child_Lock" 20 "Double_Lock" 19 "Passive_Pasenger" 18 "Passive_Driver" 17 "Slam_Lock_Protect" 16 "SYNC" 15 "Passport" 14 "Passive_Smart_Unlock" 13 "Autorelock" 12 "RemoteStart" 0 "Null" 1 "Autolock" 11 "Smart_Unlock" 10 "Sliding_Door" 9 "Passive" 8 "Remote" 7 "Programming" 6 "Powerslide" 5 "Keypad" 4 "Key_Cylinder" 3 "Interior" 2 "Auto_Unlock" ;
VAL_TABLE_ Invalid_FFFF 65535 "Invalid" ;
VAL_TABLE_ GearEngag_D_Actl 7 "Undefined" 6 "Fwd_Clutch_Fully_Engaged" 5 "Neutral_Idle" 4 "Disengaged_to_Neutral_Idle" 3 "Disengaged_to_Neutral_Park" 2 "Engagement_in_Progress" 1 "InitializeFwdClutchEngagmt" 0 "Park_Neutral" ;
VAL_TABLE_ eCallNotification 3 "Not_Used" 2 "Active" 1 "Normal" 0 "Not_Supported" ;
VAL_TABLE_ Closed_Open_Active_Fault 3 "Fault" 2 "Active" 1 "Open" 0 "Closed" ;
VAL_TABLE_ SAPPAngleControlStat2 1 "Rel_ExtSteeringAngleReqx" 0 "NoRel_ExtSteeringAngleReqx" ;
VAL_TABLE_ RstrnImpactEvntStatus 7 "Invalid" 6 "Not_Used_4" 5 "Threshold_2_Exceeded" 4 "Not_Used_3" 3 "Threshold_1_Exceeded" 2 "Not_Used_2" 1 "Not_Used_1" 0 "Normal" ;
VAL_TABLE_ EDRTriggerEvntSync 1 "Threshold_Exceeded" 0 "Normal" ;
VAL_TABLE_ Closed_Ajar 1 "Ajar" 0 "Closed" ;
VAL_TABLE_ Quality_Factor 3 "OK" 2 "Not_Within_Specifications" 1 "No_Data_Exists" 0 "Faulty" ;
VAL_TABLE_ Null_Day_Night 3 "NotUsed" 2 "Night" 1 "Day" 0 "Null" ;
VAL_TABLE_ GearPos_D_Actl 15 "Unknown" 14 "Reverse" 13 "Undefined_5" 12 "Undefined_4" 11 "Undefined_3" 10 "Tenth" 9 "Ninth" 8 "Eighth" 7 "Seventh" 6 "Sixth" 5 "Fifth" 4 "Fourth" 3 "Third" 2 "Second" 1 "First" 0 "Neutral" ;
VAL_TABLE_ OffOn_SlowFast_Flash 3 "Fast_Flash" 2 "Slow_Flash" 1 "On" 0 "Off" ;
VAL_TABLE_ WhlDir 3 "Faulty" 2 "NoDataExists" 1 "Backward" 0 "Forward" ;
VAL_TABLE_ TerrMde_D_Actl 7 "Fail_Safe_Default" 6 "Dynamic_Mode" 5 "Rock_Crawl_Mode" 4 "Mud_Ruts_Mode" 3 "Sand_Mode" 2 "Undefined" 1 "Low_Mu_Mode" 0 "Special_Operating_Mode_Off" ;
VAL_TABLE_ TerrMdeChng_D_Rdy 7 "Fault" 6 "Undefined_2" 5 "Undefined_1" 4 "ModeUnavailDrInputRqd" 3 "SpOpModes_NotSupported" 2 "ModeUnavailDynamicCond" 1 "Module_In_Initialization" 0 "Mode_Change_Available" ;
VAL_TABLE_ Unknown_Fault_FFFE_FFFF 65535 "Fault" 65534 "Unknown" ;
VAL_TABLE_ Invalid_FFFFFF 16777215 "Invalid" ;
VAL_TABLE_ GearLvrPos_D_Actl 15 "Fault" 14 "Unknown_Position" 13 "Undefined_Treat_as__Fault" 12 "Undefined_Treat_as_Fault" 11 "sixth" 10 "fifth" 9 "fourth" 8 "third" 7 "second" 6 "first" 5 "Low" 4 "Sport_DriveSport" 3 "Drive" 2 "Neutral" 1 "Reverse" 0 "Park" ;
VAL_TABLE_ CcStat_D_Actl 7 "Undefined_2" 6 "Undefined_1" 5 "Active" 4 "Active_Que_Assist" 3 "Standby" 2 "Standby_Denied" 1 "Denied" 0 "Off" ;
VAL_TABLE_ BpedDrvAppl_D_Actl 3 "_Not_Allowed" 2 "Driver_Braking" 1 "Driver_Not_Braking" 0 "Not_Allowed" ;
VAL_TABLE_ AccEngStat_D_Actl 7 "Undefined_2" 6 "Undefined_1" 5 "ACCSoonCancel_due_Low_Spd" 4 "Shift_Down_Recommendation" 3 "Shift_Up_Recommendation" 2 "ACCNotAllowedToBeActivated" 1 "ACCStandby_due_Auto_Cancel" 0 "Normal_Operation" ;
VAL_TABLE_ NotPressed_Pressed 1 "Pressed" 0 "Not_Pressed" ;
VAL_TABLE_ Unknown_Fault_FFE_FFF 4095 "Fault" 4094 "Unknown" ;
VAL_TABLE_ InhibitNoinhibit 1 "Inhibit" 0 "No_Inibit" ;
VAL_TABLE_ DisableEnable 1 "Enable" 0 "Disable" ;
VAL_TABLE_ Litval_values 255 "Invalid" 254 "Unknown" 5 "Day" 4 "Twilight_4" 3 "Twilight_3" 2 "Twilight_2" 1 "Twilight_1" 0 "Night" ;
VAL_TABLE_ Dimming_Lvl 255 "Invalid" 254 "Unknown" 18 "Day_6" 17 "Day_5" 16 "Day_4" 15 "Day_3" 14 "Day_2" 13 "Day_1" 12 "Night_12" 11 "Night_11" 10 "Night_10" 9 "Night_9" 8 "Night_8" 7 "Night_7" 6 "Night_6" 5 "Night_5" 4 "Night_4" 3 "Night_3" 2 "Night_2" 1 "Night_1" 0 "Off" ;
VAL_TABLE_ NotOperating 1 "Operating" 0 "Not_Operating" ;
VAL_TABLE_ EngPtoMde_D_Actl 7 "Undefined" 6 "Split_Shaft_Stationary" 5 "Not_Used_2" 4 "PTO_Mobile" 3 "Not_Used_1" 2 "PTO_Stationary" 1 "BCP" 0 "Off" ;
VAL_TABLE_ Remote_Start_Status 3 "Invalid" 2 "Unknown" 1 "Remote" 0 "Null" ;
VAL_TABLE_ Unknown_Invalid_FE_FF 255 "Invalid" 254 "Unknown" ;
VAL_TABLE_ Key_In_Ignition_Status 1 "In" 0 "Out" ;
VAL_TABLE_ Ignition_Status 0 "Unknown" 1 "Off" 15 "Invalid" 8 "Start" 4 "Run" 2 "Accessory" ;
VAL_TABLE_ Unknown_Fault_FE_FF 255 "Fault" 254 "Unknown" ;
VAL_TABLE_ HsaStat_D_Dsply 7 "NotUsed3" 6 "NotUsed2" 5 "NotUsed1" 4 "NotAvailable" 3 "SlowReleaseWithChime" 2 "SlowReleaseWithoutChime" 1 "Active" 0 "Inactive" ;
VAL_TABLE_ PassRstrnInd_Req 3 "ABOnNotIllum_OffNotIllum" 2 "AirbagOnNot_Illum_OffIllum" 1 "AirbagOn_Illum_OffNotIllum" 0 "AirbagOn_Illum_Off_Illum" ;
VAL_TABLE_ RearDiffLckMsg_D_Rq 7 "Locker_Disabled" 6 "Locker_Enabled" 5 "Locker_Accel_Pedal" 4 "Speed4" 3 "Speed3" 2 "Spee2" 1 "Speed1" 0 "Normal__No_Message " ;
VAL_TABLE_ Off_On 1 "On" 0 "Off" ;
VAL_TABLE_ CcMde_D_Actl 7 "TapDownWaiting" 6 "TapUpWaiting" 5 "Resuming_Low" 4 "Resuming_High" 3 "Decelerating" 2 "Accelerating" 1 "Keeping_Speed" 0 "Not_Active" ;
VAL_TABLE_ InactiveActive 1 "Active" 0 "Inactive" ;
VAL_TABLE_ NoYes 1 "Yes" 0 "No" ;
VAL_TABLE_ Unknown_Fault_3FE_3FF 1023 "Fault" 1022 "Unknown" ;
VAL_TABLE_ Off_On_Flash 3 "Not_Used" 2 "Flash" 1 "On" 0 "Off" ;
VAL_TABLE_ BeltBuckle 3 "Unknown" 2 "Unbelted" 1 "Belted" 0 "Faulty" ;
VAL_TABLE_ RILReqCoding 3 "Not_Used" 2 "Plant_Mode" 1 "On" 0 "Off" ;
VAL_TABLE_ Update_Bit 1 "Fresh_data" 0 "Unchanged_data" ;
VAL_TABLE_ Turn_Seq 3 "Seq" 2 "On" 1 "Off" 0 "Null" ;
VAL_TABLE_ Pers1_4 7 "Unused_3" 6 "Unused_2" 5 "Unused_1" 4 "Vehicle" 3 "PERS_4" 2 "PERS_3" 1 "PERS_2" 0 "PERS_1" ;
VAL_TABLE_ UreaLvlTxt_D_RqDsply 15 "NotUsed_4" 14 "NotUsed_3" 13 "NotUsed_2" 12 "NotUsed_1" 11 "System_Error" 10 "Engine_Idled_See_Manual" 9 "Engine_Idled_Upon_Refuel" 8 "Speed_Limited_To_XX_mph" 7 "XXmph_Max_Upon_Restart" 6 "Speed_Limited_To_YY_mph" 5 "YYmph_Max_Upon_Restart" 4 "SpdLimtd_YYmph_In_XXmiles" 3 "ExFlRange_XXMiles_ScndWarn" 2 "Exh_Fluid_Range_XX_Miles" 1 "Exh_Fluid_Under_Half_Full" 0 "Exh_Fluid_Over_Half_Full" ;
VAL_TABLE_ CCOverridden 1 "Cruise_Overridden" 0 "Cruise_Req_Not_Overridden" ;
VAL_TABLE_ Ign_Key_Device_Type 15 "Invalid" 14 "Unknown" 3 "Key_Not_Prgrm_Read_Failure" 2 "Key_In_Ign_My_Key" 1 "Key_In_Ign_Standard_Key" 0 "Key_Read_In_Progress" ;

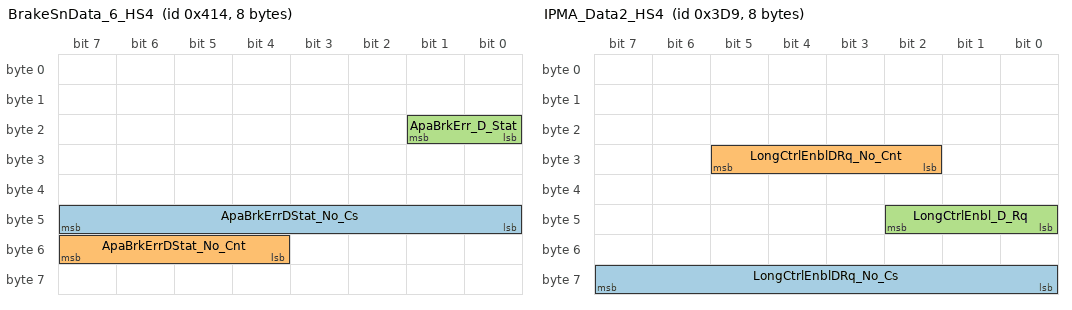
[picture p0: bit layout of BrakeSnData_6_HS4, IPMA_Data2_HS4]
BO_ 1044 BrakeSnData_6_HS4: 8 GWM
 SG_ ApaBrkErrDStat_No_Cs : 47|8@0+ (1,0) [0|255] "Unitless"  RFA_BLEM
 SG_ ApaBrkErrDStat_No_Cnt : 55|4@0+ (1,0) [0|15] "Unitless"  RFA_BLEM
 SG_ ApaBrkErr_D_Stat : 17|2@0+ (1,0) [0|3] "SED"  RFA_BLEM

BO_ 517 PowertrainData_6_HS4: 8 GWM
 SG_ FapLc_B_Err : 10|1@0+ (1,0) [0|1] "SED"  RFA_BLEM

BO_ 985 IPMA_Data2_HS4: 8 GWM
 SG_ LongCtrlEnblDRq_No_Cs : 63|8@0+ (1,0) [0|255] "Unitless"  RFA_BLEM
 SG_ LongCtrlEnblDRq_No_Cnt : 29|4@0+ (1,0) [0|15] "Unitless"  RFA_BLEM
 SG_ LongCtrlEnbl_D_Rq : 42|3@0+ (1,0) [0|7] "SED"  RFA_BLEM

BO_ 942 ParkAid_Data_3_HS4: 8 GWM
 SG_ ApaOffOptnSel_B_Avail : 51|1@0+ (1,0) [0|1] "SED"  GENERIC
 SG_ PrkBrkElRleas_B_RqApa : 50|1@0+ (1,0) [0|1] "SED"  GENERIC
 SG_ ApaDrvRq2MsgTxt_D_Rq : 55|4@0+ (1,0) [0|15] "SED"  GENERIC
 SG_ ApaDrvRq1MsgTxt_D_Rq : 42|3@0+ (1,0) [0|7] "SED"  RFA_BLEM
 SG_ ApaSys_D2_Stat : 35|4@0+ (1,0) [0|15] "SED"  GENERIC
 SG_ ApaSlotTrgt_D_Stat : 39|4@0+ (1,0) [0|15] "SED"  GENERIC
 SG_ ApaSlotOption_B_Avail : 43|1@0+ (1,0) [0|1] "SED"  GENERIC
 SG_ ApaSlotAlrtSet_B_Stat : 44|1@0+ (1,0) [0|1] "SED"  GENERIC
 SG_ ApaSlotAlrt_B_Rq : 45|1@0+ (1,0) [0|1] "SED"  GENERIC
 SG_ ApaRmtFeatSel_B_Avail : 46|1@0+ (1,0) [0|1] "SED"  GENERIC
 SG_ ApaParkOutSel_B_Avail : 47|1@0+ (1,0) [0|1] "SED"  GENERIC
 SG_ ApaParkInSel_B_Avail : 24|1@0+ (1,0) [0|1] "SED"  GENERIC
 SG_ ApaMsgTxt_D2_Stat : 28|4@0+ (1,0) [0|15] "SED"  GENERIC
 SG_ ApaDynmcSlot_B_Stat : 29|1@0+ (1,0) [0|1] "SED"  GENERIC
 SG_ ApaDisplayMode_D_Stat : 31|2@0+ (1,0) [0|3] "SED"  GENERIC
 SG_ ApaControlMode_D_Stat : 16|1@0+ (1,0) [0|1] "SED"  GENERIC
 SG_ PrkAidAcsyRear_D_Stat : 18|2@0+ (1,0) [0|3] "SED"  GENERIC
 SG_ PrkAidAcsyFront_D_Stat : 20|2@0+ (1,0) [0|3] "SED"  GENERIC
 SG_ PrkAidRdiusRight_L_Dsply : 15|8@0+ (1,0) [0|255] "unitless"  GENERIC
 SG_ PrkAidRdiusLeft_L_Dsply : 7|8@0+ (1,0) [0|255] "unitless"  GENERIC
 SG_ PrkAidDrvDir_D_Stat : 23|3@0+ (1,0) [0|7] "SED"  GENERIC

BO_ 624 PaakCtlData6: 8 RFA_BLEM
 SG_ PaakAddEraseIndx_No_Rq : 5|6@0+ (1,0) [0|63] "unitless"  GWM
 SG_ PaakAddErase_D_Rq : 7|2@0+ (1,0) [0|3] "SED"  GWM

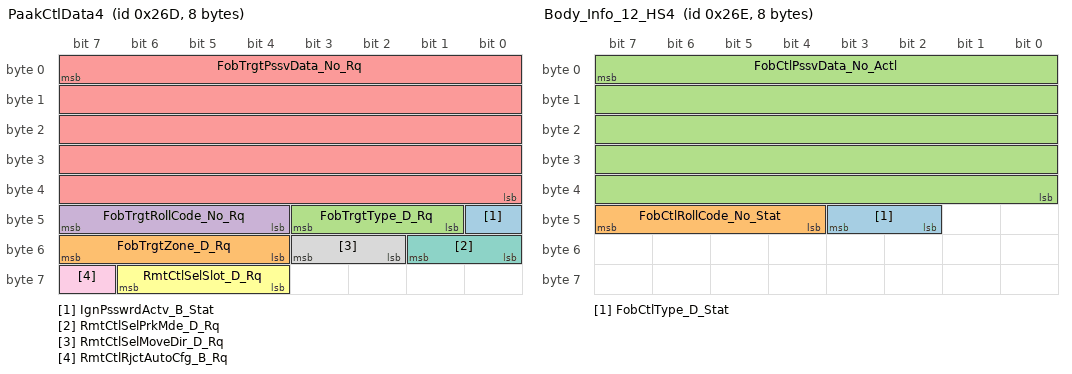
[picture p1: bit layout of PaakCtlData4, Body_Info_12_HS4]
BO_ 621 PaakCtlData4: 8 RFA_BLEM
 SG_ IgnPsswrdActv_B_Stat : 40|1@0+ (1,0) [0|1] "SED"  GWM
 SG_ FobTrgtZone_D_Rq : 55|4@0+ (1,0) [0|15] "SED"  GWM
 SG_ FobTrgtType_D_Rq : 43|3@0+ (1,0) [0|7] "SED"  GWM
 SG_ FobTrgtRollCode_No_Rq : 47|4@0+ (1,0) [0|15] "unitless"  GWM
 SG_ FobTrgtPssvData_No_Rq : 7|40@0+ (1,0) [0|1099511627775] "Encrypted"  GWM
 SG_ RmtCtlSelSlot_D_Rq : 62|3@0+ (1,0) [0|7] "SED"  GWM
 SG_ RmtCtlSelPrkMde_D_Rq : 49|2@0+ (1,0) [0|3] "SED"  GWM
 SG_ RmtCtlSelMoveDir_D_Rq : 51|2@0+ (1,0) [0|3] "SED"  GWM
 SG_ RmtCtlRjctAutoCfg_B_Rq : 63|1@0+ (1,0) [0|1] "SED"  GWM

BO_ 622 Body_Info_12_HS4: 8 GWM
 SG_ FobCtlType_D_Stat : 43|2@0+ (1,0) [0|3] "SED"  RFA_BLEM
 SG_ FobCtlRollCode_No_Stat : 47|4@0+ (1,0) [0|15] "unitless"  RFA_BLEM
 SG_ FobCtlPssvData_No_Actl : 7|40@0+ (1,0) [0|1099511627775] "Encrypted"  RFA_BLEM

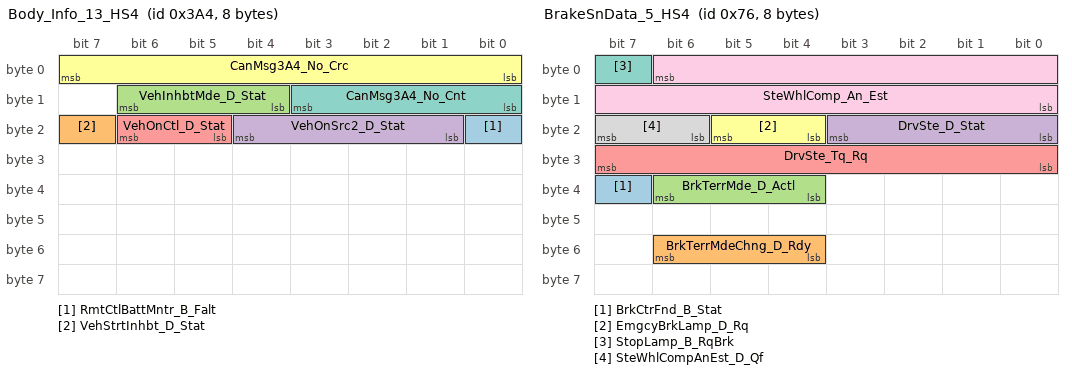
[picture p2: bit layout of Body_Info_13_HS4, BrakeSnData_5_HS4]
BO_ 932 Body_Info_13_HS4: 8 GWM
 SG_ RmtCtlBattMntr_B_Falt : 16|1@0+ (1,0) [0|1] "SED"  RFA_BLEM
 SG_ VehStrtInhbt_D_Stat : 23|1@0+ (1,0) [0|1] "SED"  GENERIC
 SG_ VehInhbtMde_D_Stat : 14|3@0+ (1,0) [0|7] "SED"  GENERIC
 SG_ VehOnSrc2_D_Stat : 20|4@0+ (1,0) [0|15] "SED"  GENERIC
 SG_ VehOnCtl_D_Stat : 22|2@0+ (1,0) [0|3] "SED"  GENERIC
 SG_ CanMsg3A4_No_Crc : 7|8@0+ (1,0) [0|255] "Unitless"  GENERIC
 SG_ CanMsg3A4_No_Cnt : 11|4@0+ (1,0) [0|15] "Unitless"  GENERIC

BO_ 118 BrakeSnData_5_HS4: 8 GWM
 SG_ BrkCtrFnd_B_Stat : 39|1@0+ (1,0) [0|1] "SED"  GENERIC
 SG_ BrkTerrMdeChng_D_Rdy : 54|3@0+ (1,0) [0|7] "SED"  GENERIC
 SG_ BrkTerrMde_D_Actl : 38|3@0+ (1,0) [0|7] "SED"  GENERIC
 SG_ DrvSte_D_Stat : 19|4@0+ (1,0) [0|15] "SED"  GENERIC
 SG_ DrvSte_Tq_Rq : 31|8@0+ (0.0625,-8) [-8|7.8125] "Nm"  GENERIC
 SG_ EmgcyBrkLamp_D_Rq : 21|2@0+ (1,0) [0|3] "SED"  GENERIC
 SG_ StopLamp_B_RqBrk : 7|1@0+ (1,0) [0|1] "SED"  GENERIC
 SG_ SteWhlCompAnEst_D_Qf : 23|2@0+ (1,0) [0|3] "SED"  GENERIC
 SG_ SteWhlComp_An_Est : 6|15@0+ (0.1,-1600) [-1600|1676.7] "deg"  GENERIC

BO_ 2612080856 PARSEDPushFcGWM_ECGtoRFA: 8 GWM
 SG_ PARSEDPushFcGWM_ECGtoRFA : 7|29@0+ (1,0) [0|536870911] "unitless"  RFA_BLEM

BO_ 2610126924 OTAPhysRFAtoGWM_ECG: 8 RFA_BLEM
 SG_ OTAPhysRFAtoGWM_ECG : 7|29@0+ (1,0) [0|536870911] "unitless"  GWM

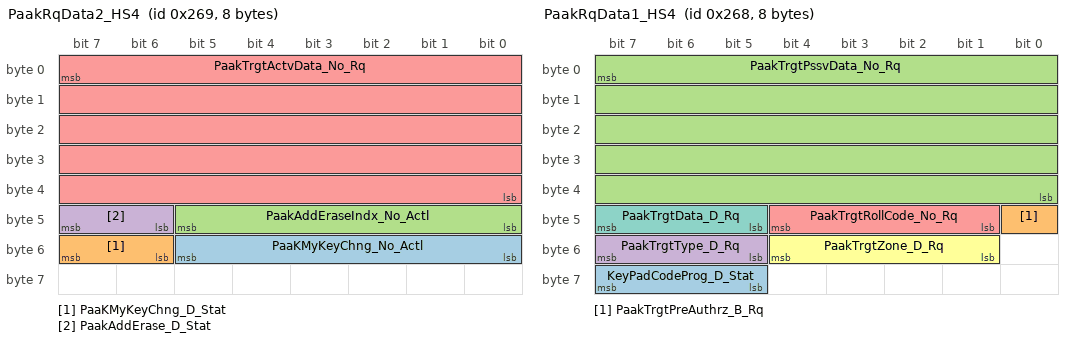
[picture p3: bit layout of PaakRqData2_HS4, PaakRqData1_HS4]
BO_ 617 PaakRqData2_HS4: 8 GWM
 SG_ PaaKMyKeyChng_No_Actl : 53|6@0+ (1,0) [0|63] "unitless"  RFA_BLEM
 SG_ PaaKMyKeyChng_D_Stat : 55|2@0+ (1,0) [0|3] "SED"  RFA_BLEM
 SG_ PaakAddEraseIndx_No_Actl : 45|6@0+ (1,0) [0|63] "unitless"  RFA_BLEM
 SG_ PaakAddErase_D_Stat : 47|2@0+ (1,0) [0|3] "SED"  RFA_BLEM
 SG_ PaakTrgtActvData_No_Rq : 7|40@0+ (1,0) [0|1099511627775] "unitless"  RFA_BLEM

BO_ 616 PaakRqData1_HS4: 8 GWM
 SG_ KeyPadCodeProg_D_Stat : 63|3@0+ (1,0) [0|7] "SED"  RFA_BLEM
 SG_ PaakTrgtPreAuthrz_B_Rq : 40|1@0+ (1,0) [0|1] "SED"  RFA_BLEM
 SG_ PaakTrgtPssvData_No_Rq : 7|40@0+ (1,0) [0|1099511627775] "unitless"  RFA_BLEM
 SG_ PaakTrgtType_D_Rq : 55|3@0+ (1,0) [0|7] "SED"  RFA_BLEM
 SG_ PaakTrgtRollCode_No_Rq : 44|4@0+ (1,0) [0|15] "unitless"  RFA_BLEM
 SG_ PaakTrgtZone_D_Rq : 52|4@0+ (1,0) [0|15] "SED"  RFA_BLEM
 SG_ PaakTrgtData_D_Rq : 47|3@0+ (1,0) [0|7] "SED"  RFA_BLEM

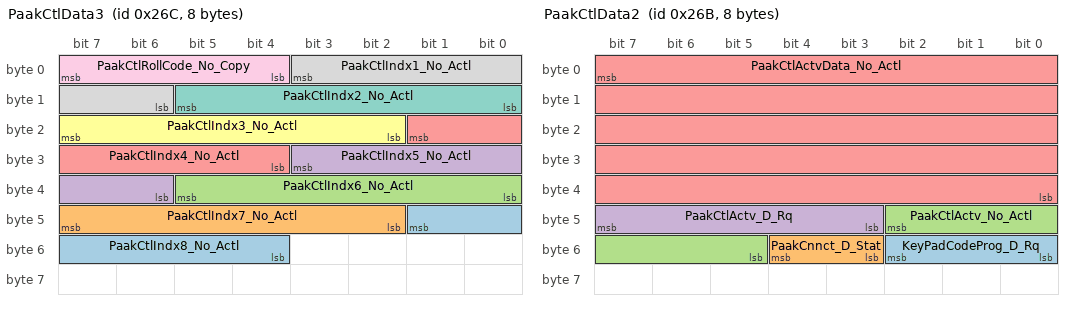
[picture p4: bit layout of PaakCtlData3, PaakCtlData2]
BO_ 620 PaakCtlData3: 8 RFA_BLEM
 SG_ PaakCtlIndx8_No_Actl : 41|6@0+ (1,0) [0|63] "unitless"  GWM
 SG_ PaakCtlIndx7_No_Actl : 47|6@0+ (1,0) [0|63] "unitless"  GWM
 SG_ PaakCtlIndx6_No_Actl : 37|6@0+ (1,0) [0|63] "unitless"  GWM
 SG_ PaakCtlIndx5_No_Actl : 27|6@0+ (1,0) [0|63] "unitless"  GWM
 SG_ PaakCtlIndx4_No_Actl : 17|6@0+ (1,0) [0|63] "unitless"  GWM
 SG_ PaakCtlIndx3_No_Actl : 23|6@0+ (1,0) [0|63] "unitless"  GWM
 SG_ PaakCtlIndx2_No_Actl : 13|6@0+ (1,0) [0|63] "unitless"  GWM
 SG_ PaakCtlIndx1_No_Actl : 3|6@0+ (1,0) [0|63] "unitless"  GWM
 SG_ PaakCtlRollCode_No_Copy : 7|4@0+ (1,0) [0|15] "unitless"  GWM

BO_ 619 PaakCtlData2: 8 RFA_BLEM
 SG_ KeyPadCodeProg_D_Rq : 50|3@0+ (1,0) [0|7] "SED"  GWM
 SG_ PaakCnnct_D_Stat : 52|2@0+ (1,0) [0|3] "SED"  GWM
 SG_ PaakCtlActv_No_Actl : 42|6@0+ (1,0) [0|63] "unitless"  GWM
 SG_ PaakCtlActv_D_Rq : 47|5@0+ (1,0) [0|31] "SED"  GWM
 SG_ PaakCtlActvData_No_Actl : 7|40@0+ (1,0) [0|1099511627775] "unitless"  GWM

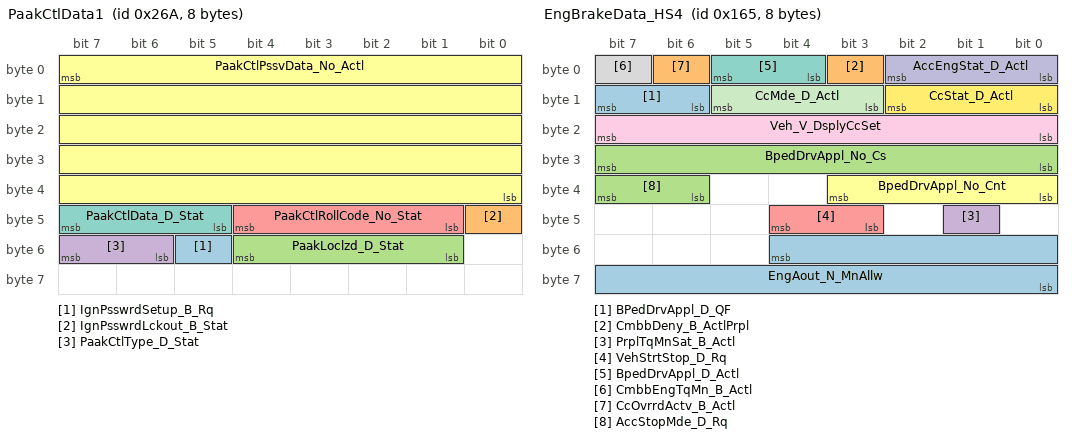
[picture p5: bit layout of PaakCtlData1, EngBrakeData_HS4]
BO_ 618 PaakCtlData1: 8 RFA_BLEM
 SG_ IgnPsswrdSetup_B_Rq : 53|1@0+ (1,0) [0|1] "SED"  GWM
 SG_ IgnPsswrdLckout_B_Stat : 40|1@0+ (1,0) [0|1] "SED"  GWM
 SG_ PaakLoclzd_D_Stat : 52|4@0+ (1,0) [0|15] "SED"  GWM
 SG_ PaakCtlType_D_Stat : 55|2@0+ (1,0) [0|3] "SED"  GWM
 SG_ PaakCtlRollCode_No_Stat : 44|4@0+ (1,0) [0|15] "unitless"  GWM
 SG_ PaakCtlPssvData_No_Actl : 7|40@0+ (1,0) [0|1099511627775] "unitless"  GWM
 SG_ PaakCtlData_D_Stat : 47|3@0+ (1,0) [0|7] "SED"  GWM

BO_ 600 APIM_RFA_BLEM_Tx_HS4: 8 GWM
 SG_ APIM_RFA_BLEM_Tx : 7|64@0+ (1,0) [0|1.84467440737096E+019] "unitless"  RFA_BLEM

BO_ 592 RFA_BLEM_APIM_Tx: 8 RFA_BLEM
 SG_ RFA_BLEM_APIM_Tx : 7|64@0+ (1,0) [0|1.84467440737096E+019] "unitless"  GWM

BO_ 357 EngBrakeData_HS4: 8 GWM
 SG_ BPedDrvAppl_D_QF : 15|2@0+ (1,0) [0|3] "SED"  GENERIC
 SG_ CmbbDeny_B_ActlPrpl : 3|1@0+ (1,0) [0|1] "SED"  GENERIC
 SG_ BpedDrvAppl_No_Cs : 31|8@0+ (1,0) [0|255] "Unitless"  GENERIC
 SG_ PrplTqMnSat_B_Actl : 41|1@0+ (1,0) [0|1] "SED"  GENERIC
 SG_ VehStrtStop_D_Rq : 44|2@0+ (1,0) [0|3] "SED"  GENERIC
 SG_ BpedDrvAppl_No_Cnt : 35|4@0+ (1,0) [0|15] "Unitless"  GENERIC
 SG_ BpedDrvAppl_D_Actl : 5|2@0+ (1,0) [0|3] "SED"  RFA_BLEM
 SG_ CmbbEngTqMn_B_Actl : 7|1@0+ (1,0) [0|1] "SED"  GENERIC
 SG_ Veh_V_DsplyCcSet : 23|8@0+ (1,0) [0|253] "Unitless"  GENERIC
 SG_ AccEngStat_D_Actl : 2|3@0+ (1,0) [0|7] "SED"  GENERIC
 SG_ CcMde_D_Actl : 13|3@0+ (1,0) [0|7] "SED"  GENERIC
 SG_ CcStat_D_Actl : 10|3@0+ (1,0) [0|7] "SED"  GENERIC
 SG_ EngAout_N_MnAllw : 52|13@0+ (2,0) [0|16382] "rpm"  GENERIC
 SG_ CcOvrrdActv_B_Actl : 6|1@0+ (1,0) [0|1] "SED"  GENERIC
 SG_ AccStopMde_D_Rq : 39|2@0+ (1,0) [0|3] "SED"  GENERIC

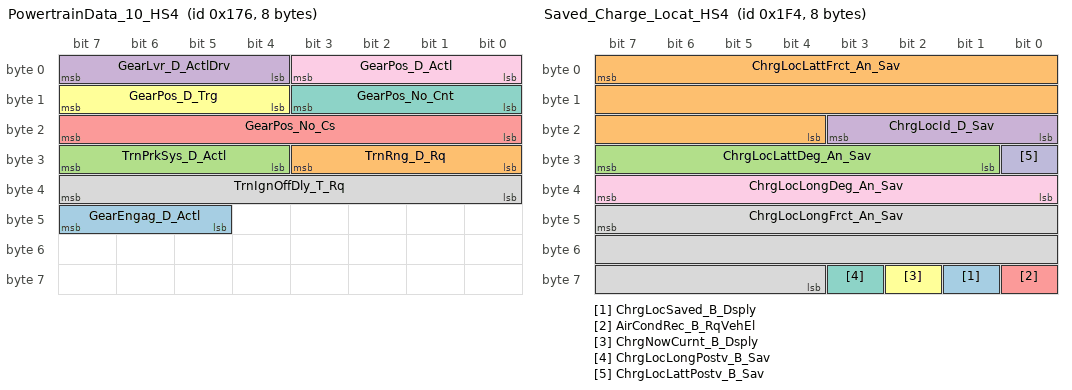
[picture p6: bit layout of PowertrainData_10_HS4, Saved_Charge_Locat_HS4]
BO_ 374 PowertrainData_10_HS4: 8 GWM
 SG_ GearEngag_D_Actl : 47|3@0+ (1,0) [0|7] "SED"  GENERIC
 SG_ TrnRng_D_Rq : 27|4@0+ (1,0) [0|15] "SED"  GENERIC
 SG_ TrnPrkSys_D_Actl : 31|4@0+ (1,0) [0|15] "SED"  RFA_BLEM
 SG_ GearLvr_D_ActlDrv : 7|4@0+ (1,0) [0|15] "SED"  RFA_BLEM
 SG_ GearPos_No_Cs : 23|8@0+ (1,0) [0|255] "unitless"  RFA_BLEM
 SG_ GearPos_D_Trg : 15|4@0+ (1,0) [0|15] "SED"  GENERIC
 SG_ GearPos_No_Cnt : 11|4@0+ (1,0) [0|15] "unitless"  RFA_BLEM
 SG_ TrnIgnOffDly_T_Rq : 39|8@0+ (4,0) [0|1020] "ms"  GENERIC
 SG_ GearPos_D_Actl : 3|4@0+ (1,0) [0|15] "SED"  RFA_BLEM

BO_ 500 Saved_Charge_Locat_HS4: 8 GWM
 SG_ ChrgLocSaved_B_Dsply : 57|1@0+ (1,0) [0|1] "SED"  GENERIC
 SG_ ChrgLocLattFrct_An_Sav : 7|20@0+ (1E-006,0) [0|1.048575] "degrees"  GENERIC
 SG_ ChrgLocLattDeg_An_Sav : 31|7@0+ (1,0) [0|127] "unitless"  GENERIC
 SG_ ChrgLocId_D_Sav : 19|4@0+ (1,0) [0|15] "unitless"  GENERIC
 SG_ AirCondRec_B_RqVehEl : 56|1@0+ (1,0) [0|1] "SED"  GENERIC
 SG_ ChrgNowCurnt_B_Dsply : 58|1@0+ (1,0) [0|1] "SED" Vector__XXX
 SG_ ChrgLocLongPostv_B_Sav : 59|1@0+ (1,0) [0|1] "SED"  GENERIC
 SG_ ChrgLocLongFrct_An_Sav : 47|20@0+ (1E-006,0) [0|1.048575] "degrees"  GENERIC
 SG_ ChrgLocLongDeg_An_Sav : 39|8@0+ (1,0) [0|255] "degrees"  GENERIC
 SG_ ChrgLocLattPostv_B_Sav : 24|1@0+ (1,0) [0|1] "SED"  GENERIC

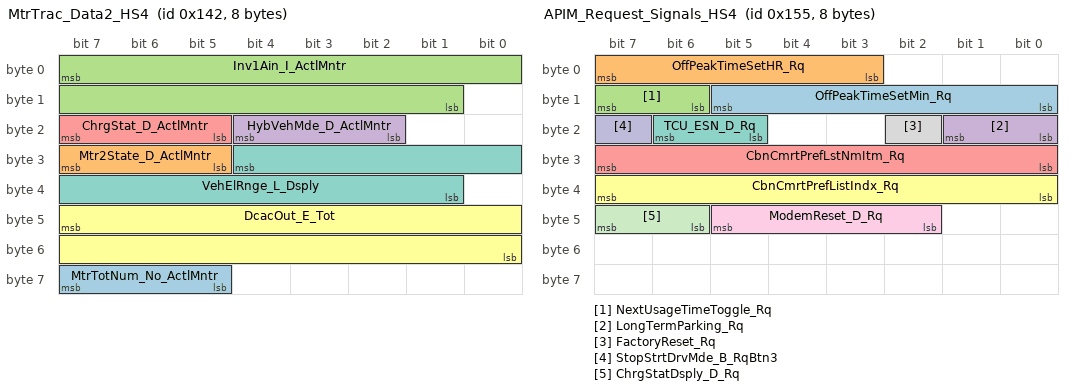
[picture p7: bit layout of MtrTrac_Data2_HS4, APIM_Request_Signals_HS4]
BO_ 322 MtrTrac_Data2_HS4: 8 GWM
 SG_ MtrTotNum_No_ActlMntr : 63|3@0+ (1,0) [0|7] "unitless"  GENERIC
 SG_ Mtr2State_D_ActlMntr : 31|3@0+ (1,0) [0|7] "SED"  GENERIC
 SG_ Inv1Ain_I_ActlMntr : 7|15@0+ (0.1,-1000) [-1000|2276.5] "ampere"  GENERIC
 SG_ HybVehMde_D_ActlMntr : 20|3@0+ (1,0) [0|7] "SED"  GENERIC
 SG_ ChrgStat_D_ActlMntr : 23|3@0+ (1,0) [0|7] "SED"  GENERIC
 SG_ DcacOut_E_Tot : 47|16@0+ (20,0) [0|1310700] "watt*hour"  GENERIC
 SG_ VehElRnge_L_Dsply : 28|12@0+ (0.1,0) [0|409.3] "kilometer"  GENERIC

BO_ 1087 Powertrain_Data_5_HS4: 8 GWM
 SG_ DcacFaltMsgTxt_D2_Rq : 39|6@0+ (1,0) [0|63] "SED"  GENERIC
 SG_ SelDrvMdeCstmPt_D_Stat : 31|5@0+ (1,0) [0|31] "SED"  GENERIC
 SG_ RepaLcGrdInhbt_B_Stat : 17|1@0+ (1,0) [0|1] "SED"  RFA_BLEM
 SG_ ClimtCool_D_RqPt : 19|2@0+ (1,0) [0|3] "SED"  GENERIC
 SG_ BtsiShifInhbt_B_RqPt : 8|1@0+ (1,0) [0|1] "SED"  GENERIC
 SG_ StrtInGearMsgTxt_D_Rq : 23|4@0+ (1,0) [0|15] "SED"  GENERIC
 SG_ IgnOffInhbt_B_Stat : 9|1@0+ (1,0) [0|1] "SED"  GENERIC
 SG_ FapLcInhbt_B_Rq : 1|1@0+ (1,0) [0|1] "SED"  GENERIC
 SG_ FapLcStopHold_B_Rq : 2|1@0+ (1,0) [0|1] "SED"  GENERIC
 SG_ FapLcPrchgBrk_B_Rq : 3|1@0+ (1,0) [0|1] "SED"  GENERIC
 SG_ FapLcObstcl_B_Stat : 4|1@0+ (1,0) [0|1] "SED"  GENERIC
 SG_ FapLcMaxGrdInhbt_B_Stat : 5|1@0+ (1,0) [0|1] "SED"  GENERIC
 SG_ FapLcMaxGrdAbrt_B_Stat : 6|1@0+ (1,0) [0|1] "SED"  RFA_BLEM
 SG_ FapLcActv_B_Stat : 7|1@0+ (1,0) [0|1] "SED"  RFA_BLEM
 SG_ BattRgenLoDChrg_D_RqEng : 13|2@0+ (1,0) [0|3] "SED"  GENERIC
 SG_ BattRgenLoChrg_D_RqEng : 15|2@0+ (1,0) [0|3] "SED"  GENERIC
 SG_ AdasLcObtclAbrt_B_Stat : 0|1@0+ (1,0) [0|1] "SED"  RFA_BLEM
 SG_ AirDamPos_D_Stat : 11|2@0+ (1,0) [0|3] "SED"  GENERIC
 SG_ StopStrtCstm_D_Stat : 26|2@0+ (1,0) [0|3] "SED"  GENERIC

BO_ 341 APIM_Request_Signals_HS4: 8 GWM
 SG_ OffPeakTimeSetMin_Rq : 13|6@0+ (1,0) [0|63] "unitless"  GENERIC
 SG_ OffPeakTimeSetHR_Rq : 7|5@0+ (1,0) [0|31] "unitless"  GENERIC
 SG_ NextUsageTimeToggle_Rq : 15|2@0+ (1,0) [0|3] "SED"  GENERIC
 SG_ LongTermParking_Rq : 17|2@0+ (1,0) [0|3] "SED"  GENERIC
 SG_ CbnCmrtPrefLstNmItm_Rq : 31|8@0+ (1,0) [0|255] "unitless"  GENERIC
 SG_ CbnCmrtPrefListIndx_Rq : 39|8@0+ (1,0) [0|255] "unitless"  GENERIC
 SG_ TCU_ESN_D_Rq : 22|2@0+ (1,0) [0|3] "SED"  TCU_FB5
 SG_ FactoryReset_Rq : 18|1@0+ (1,0) [0|1] "SED"  RFA_BLEM
 SG_ ModemReset_D_Rq : 45|4@0+ (1,0) [0|15] "SED"  RFA_BLEM
 SG_ StopStrtDrvMde_B_RqBtn3 : 23|1@0+ (1,0) [0|1] "SED"  GENERIC
 SG_ ChrgStatDsply_D_Rq : 47|2@0+ (1,0) [0|3] "SED"  GENERIC

BO_ 651 TCU_Send_Signals: 8 TCU_FB5
 SG_ TelematicsSrvc_D_St : 47|3@0+ (1,0) [0|7] "SED"  GWM
 SG_ EmgcyCallMute_D_Stat : 39|3@0+ (1,0) [0|7] "SED"  GWM

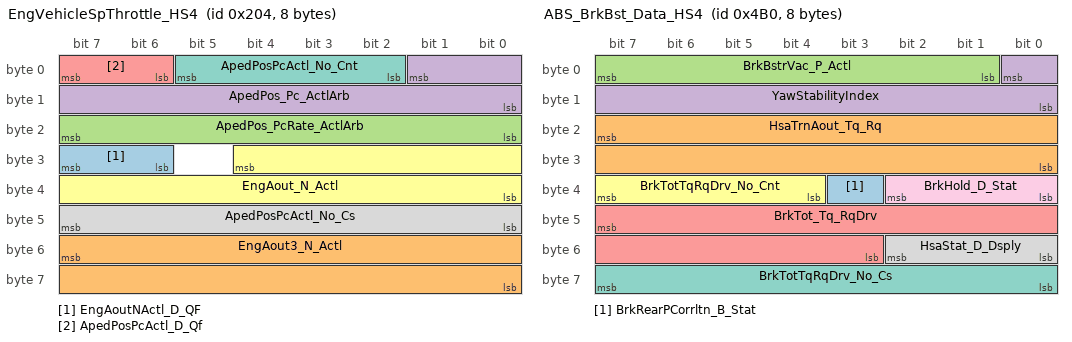
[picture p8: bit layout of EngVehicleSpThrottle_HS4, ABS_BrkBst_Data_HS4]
BO_ 516 EngVehicleSpThrottle_HS4: 8 GWM
 SG_ EngAoutNActl_D_QF : 31|2@0+ (1,0) [0|3] "SED"  GENERIC
 SG_ EngAout3_N_Actl : 55|16@0+ (0.25,0) [0|16383.5] "RPM"  GENERIC
 SG_ ApedPos_PcRate_ActlArb : 23|8@0+ (0.04,-5) [-5|5.12] "%/ms"  GENERIC
 SG_ ApedPos_Pc_ActlArb : 1|10@0+ (0.1,0) [0|102.3] "%"  RFA_BLEM
 SG_ ApedPosPcActl_D_Qf : 7|2@0+ (1,0) [0|3] "SED"  GENERIC
 SG_ EngAout_N_Actl : 28|13@0+ (2,0) [0|16382] "rpm"  GENERIC
 SG_ ApedPosPcActl_No_Cnt : 5|4@0+ (1,0) [0|15] "Unitless"  GENERIC
 SG_ ApedPosPcActl_No_Cs : 47|8@0+ (1,0) [0|255] "Unitless"  GENERIC

BO_ 531 DesiredTorqBrk_HS4: 8 GWM
 SG_ VehStop_D_Stat : 28|2@0+ (1,0) [0|3] "SED" Vector__XXX
 SG_ TracCtlPtActv_B_Actl : 31|1@0+ (1,0) [0|1] "SED"  RFA_BLEM
 SG_ LscmbbMntr_B_Err : 17|1@0+ (1,0) [0|1] "SED" Vector__XXX
 SG_ LscmbbBrkDis_B_Actl : 19|1@0+ (1,0) [0|1] "SED" Vector__XXX
 SG_ StabCtlBrkActv_B_Actl : 23|1@0+ (1,0) [0|1] "SED"  RFA_BLEM
 SG_ CmbbBrkPrchg_B_Actl : 59|1@0+ (1,0) [0|1] "SED" Vector__XXX
 SG_ CmbbBrkDecel_B_Actl : 58|1@0+ (1,0) [0|1] "SED" Vector__XXX
 SG_ CmbbBaSensInc_B_Actl : 57|1@0+ (1,0) [0|1] "SED" Vector__XXX
 SG_ AccBrkWarm_B_Actl : 63|1@0+ (1,0) [0|1] "SED" Vector__XXX
 SG_ AccBrkTotTqMn_B_Actl : 62|1@0+ (1,0) [0|1] "SED" Vector__XXX
 SG_ AccBrkPrchgActv_B_Actl : 61|1@0+ (1,0) [0|1] "SED" Vector__XXX
 SG_ AccBrkDis_B_Actl : 44|1@0+ (1,0) [0|1] "SED" Vector__XXX
 SG_ AccBrkDeny_B_Actl : 42|1@0+ (1,0) [0|1] "SED" Vector__XXX
 SG_ AccBrkActv_B_Actl : 43|1@0+ (1,0) [0|1] "SED" Vector__XXX
 SG_ PrplDrgCtlActv_B_Actl : 46|1@0+ (1,0) [0|1] "SED" Vector__XXX
 SG_ PrplWhlTot_Tq_RqMx : 7|16@0+ (4,-131072) [-131072|131068] "Nm"  GENERIC
 SG_ AbsActv_B_Actl : 45|1@0+ (1,0) [0|1] "SED"  RFA_BLEM
 SG_ CmbbBrkDis_B_Actl : 56|1@0+ (1,0) [0|1] "SED" Vector__XXX
 SG_ CmbbDeny_B_ActlBrk : 60|1@0+ (1,0) [0|1] "SED" Vector__XXX
 SG_ CcDis_B_Cmd : 47|1@0+ (1,0) [0|1] "SED" Vector__XXX
 SG_ VehLongOvrGnd_A_Est : 41|10@0+ (0.035,-17.9) [-17.9|17.835] "m/s^2"  GENERIC
 SG_ AccStopActv_B_ActlBrk : 22|1@0+ (1,0) [0|1] "SED" Vector__XXX
 SG_ AccDis_B_ActlEpb : 32|1@0+ (1,0) [0|1] "SED" Vector__XXX
 SG_ PrkBrkYwLamp_D_Rq : 38|2@0+ (1,0) [0|3] "SED" Vector__XXX
 SG_ PrkBrkRedLamp_D_Rq : 30|2@0+ (1,0) [0|3] "SED" Vector__XXX
 SG_ PrkBrkMsgTxt_D_Rq : 36|4@0+ (1,0) [0|15] "SED" Vector__XXX
 SG_ PrkBrkStatus : 26|3@0+ (1,0) [0|7] "SED" Vector__XXX
 SG_ VehicleStationary : 39|1@0+ (1,0) [0|1] "SED" Vector__XXX
 SG_ LscmbbDeny_B_ActlBrk : 18|1@0+ (1,0) [0|1] "SED" Vector__XXX
 SG_ LscmbbBrkDecel_B_Actl : 20|1@0+ (1,0) [0|1] "SED" Vector__XXX
 SG_ LscmbbBaSensInc_B_Actl : 21|1@0+ (1,0) [0|1] "SED" Vector__XXX
 SG_ LscmbBrkPrchg_B_Actl : 16|1@0+ (1,0) [0|1] "SED" Vector__XXX

BO_ 1054 BrakeSysFeatures_3_HS4: 8 GWM
 SG_ RbaBrk_D_Stat : 63|2@0+ (1,0) [0|3] "SED" Vector__XXX
 SG_ SelDrvMdeChassis2_D_Rq : 45|5@0+ (1,0) [0|31] "SED" Vector__XXX
 SG_ BrkBstrLoLampOn_B_Rq : 24|1@0+ (1,0) [0|1] "SED" Vector__XXX
 SG_ TrailCtl_D_Stat : 55|3@0+ (1,0) [0|7] "SED" Vector__XXX
 SG_ TrailCtlMsgTxt_D_Rq : 52|4@0+ (1,0) [0|15] "SED" Vector__XXX
 SG_ BrkPadMsgTxt_D_Rq : 31|2@0+ (1,0) [0|3] "SED" Vector__XXX
 SG_ BrkBstrVac_D_Stat : 18|2@0+ (1,0) [0|3] "SED" Vector__XXX
 SG_ DrvSlipCtlOffLamp_D_Rq : 23|2@0+ (1,0) [0|3] "SED" Vector__XXX
 SG_ DrvSlipCtlMdeMsg_D_Rq : 13|5@0+ (1,0) [0|31] "SED" Vector__XXX
 SG_ HdcOn_B_Ind : 16|1@0+ (1,0) [0|1] "SED" Vector__XXX
 SG_ AutoHoldMsgTxt_D_Rq : 4|4@0+ (1,0) [0|15] "SED" Vector__XXX
 SG_ CtaBrk_D_Stat : 47|2@0+ (1,0) [0|3] "SED" Vector__XXX
 SG_ SelDrvMdeAwd_D_Rq : 29|5@0+ (1,0) [0|31] "SED" Vector__XXX
 SG_ AutoHoldSwMde_B_Ind : 0|1@0+ (1,0) [0|1] "SED" Vector__XXX
 SG_ AutoHoldMde_D_Ind : 15|2@0+ (1,0) [0|3] "SED" Vector__XXX
 SG_ BrkMdeInhbt_B_RqDsply : 8|1@0+ (1,0) [0|1] "SED" Vector__XXX
 SG_ BrkLineLck_D_Stat : 21|3@0+ (1,0) [0|7] "SED" Vector__XXX
 SG_ SelDrvMdeChassis_D_Rq : 39|5@0+ (1,0) [0|31] "SED" Vector__XXX
 SG_ ApaBrk_D_Stat : 34|2@0+ (1,0) [0|3] "SED"  RFA_BLEM
 SG_ SelDrvMdeChassis3_D_Rq : 61|5@0+ (1,0) [0|31] "SED" Vector__XXX
 SG_ TrailOnePdlTqLm_B_Actl : 56|1@0+ (1,0) [0|1] "SED" Vector__XXX
 SG_ OnePdlDrvDeny_B_Stat : 40|1@0+ (1,0) [0|1] "SED" Vector__XXX
 SG_ BrkDrvMde_D_Stat : 7|3@0+ (1,0) [0|7] "SED" Vector__XXX
 SG_ AirDamUp_B_RqBrk : 32|1@0+ (1,0) [0|1] "SED" Vector__XXX
 SG_ FrontDiffElckrOpen_B_Rq : 48|1@0+ (1,0) [0|1] "SED" Vector__XXX

BO_ 1200 ABS_BrkBst_Data_HS4: 8 GWM
 SG_ BrkRearPCorrltn_B_Stat : 35|1@0+ (1,0) [0|1] "SED"  GENERIC
 SG_ HsaTrnAout_Tq_Rq : 23|16@0+ (4,-131072) [-131072|131060] "Nm"  GENERIC
 SG_ BrkBstrVac_P_Actl : 7|7@0+ (8,0) [0|1008] "Millibar"  GENERIC
 SG_ YawStabilityIndex : 0|9@0+ (1,-256) [-256|255] "%"  GENERIC
 SG_ BrkTot_Tq_RqDrv : 47|13@0+ (4,0) [0|32760] "Nm"  RFA_BLEM
 SG_ BrkTotTqRqDrv_No_Cnt : 39|4@0+ (1,0) [0|15] "unitless"  RFA_BLEM
 SG_ BrkTotTqRqDrv_No_Cs : 63|8@0+ (1,0) [0|255] "unitless"  RFA_BLEM
 SG_ HsaStat_D_Dsply : 50|3@0+ (1,0) [0|7] "SED"  RFA_BLEM
 SG_ BrkHold_D_Stat : 34|3@0+ (1,0) [0|7] "SED"  RFA_BLEM

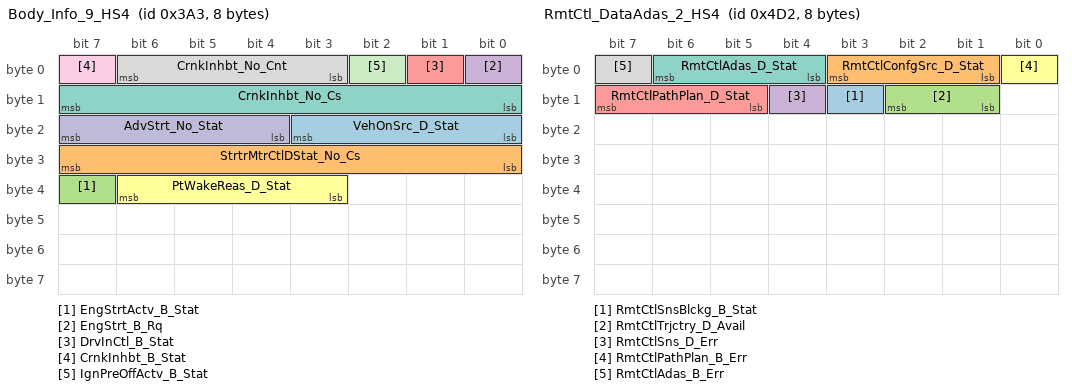
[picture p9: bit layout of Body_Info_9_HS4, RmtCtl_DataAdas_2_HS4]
BO_ 931 Body_Info_9_HS4: 8 GWM
 SG_ VehOnSrc_D_Stat : 19|4@0+ (1,0) [0|15] "SED"  RFA_BLEM
 SG_ StrtrMtrCtlDStat_No_Cs : 31|8@0+ (1,0) [0|255] "unitless" Vector__XXX
 SG_ EngStrtActv_B_Stat : 39|1@0+ (1,0) [0|1] "SED" Vector__XXX
 SG_ EngStrt_B_Rq : 0|1@0+ (1,0) [0|1] "SED" Vector__XXX
 SG_ DrvInCtl_B_Stat : 1|1@0+ (1,0) [0|1] "SED" Vector__XXX
 SG_ PtWakeReas_D_Stat : 38|4@0+ (1,0) [0|15] "SED" Vector__XXX
 SG_ CrnkInhbt_No_Cs : 15|8@0+ (1,0) [0|255] "Unitless" Vector__XXX
 SG_ CrnkInhbt_No_Cnt : 6|4@0+ (1,0) [0|15] "Unitless" Vector__XXX
 SG_ CrnkInhbt_B_Stat : 7|1@0+ (1,0) [0|1] "SED" Vector__XXX
 SG_ AdvStrt_No_Stat : 23|4@0+ (1,0) [0|15] "unitless" Vector__XXX
 SG_ IgnPreOffActv_B_Stat : 2|1@0+ (1,0) [0|1] "SED" Vector__XXX

BO_ 1234 RmtCtl_DataAdas_2_HS4: 8 GWM
 SG_ RmtCtlSnsBlckg_B_Stat : 11|1@0+ (1,0) [0|1] "SED"  RFA_BLEM
 SG_ RmtCtlConfgSrc_D_Stat : 3|3@0+ (1,0) [0|7] "SED"  RFA_BLEM
 SG_ RmtCtlTrjctry_D_Avail : 10|2@0+ (1,0) [0|3] "SED"  RFA_BLEM
 SG_ RmtCtlSns_D_Err : 12|1@0+ (1,0) [0|1] "SED"  RFA_BLEM
 SG_ RmtCtlPathPlan_D_Stat : 15|3@0+ (1,0) [0|7] "SED"  RFA_BLEM
 SG_ RmtCtlPathPlan_B_Err : 0|1@0+ (1,0) [0|1] "SED"  RFA_BLEM
 SG_ RmtCtlAdas_D_Stat : 6|3@0+ (1,0) [0|7] "SED"  RFA_BLEM
 SG_ RmtCtlAdas_B_Err : 7|1@0+ (1,0) [0|1] "SED"  RFA_BLEM

BO_ 1233 RmtCtl_DataAdas_1_HS4: 8 GWM
 SG_ FreeDrvRear_D_Avail : 27|2@0+ (1,0) [0|3] "SED"  RFA_BLEM
 SG_ FreeDrvFwd_D_Avail : 7|2@0+ (1,0) [0|3] "SED"  RFA_BLEM
 SG_ RmtCtlTrgDist_D_Stat : 63|8@0+ (0.1,0) [0|25.5] "meter"  RFA_BLEM
 SG_ RmtCtlSnsRrCrnr_D_Stat : 55|2@0+ (1,0) [0|3] "SED"  RFA_BLEM
 SG_ RmtCtlSnsRlCrnr_D_Stat : 49|2@0+ (1,0) [0|3] "SED"  RFA_BLEM
 SG_ RmtCtlSnsRear_D_Stat : 51|2@0+ (1,0) [0|3] "SED"  RFA_BLEM
 SG_ RmtCtlSnsFront_D_Stat : 53|2@0+ (1,0) [0|3] "SED"  RFA_BLEM
 SG_ RmtCtlSnsFrCrnr_D_Stat : 41|2@0+ (1,0) [0|3] "SED"  RFA_BLEM
 SG_ RmtCtlSnsFlCrnr_D_Stat : 43|2@0+ (1,0) [0|3] "SED"  RFA_BLEM
 SG_ RmtCtlSideSnsR4_D_Stat : 45|2@0+ (1,0) [0|3] "SED"  RFA_BLEM
 SG_ RmtCtlSideSnsR3_D_Stat : 47|2@0+ (1,0) [0|3] "SED"  RFA_BLEM
 SG_ RmtCtlSideSnsR2_D_Stat : 33|2@0+ (1,0) [0|3] "SED"  RFA_BLEM
 SG_ RmtCtlSideSnsR1_D_Stat : 35|2@0+ (1,0) [0|3] "SED"  RFA_BLEM
 SG_ RmtCtlSideSnsL4_D_Stat : 37|2@0+ (1,0) [0|3] "SED"  RFA_BLEM
 SG_ RmtCtlSideSnsL3_D_Stat : 39|2@0+ (1,0) [0|3] "SED"  RFA_BLEM
 SG_ RmtCtlSideSnsL2_D_Stat : 25|2@0+ (1,0) [0|3] "SED"  RFA_BLEM
 SG_ RmtCtlSideSnsL1_D_Stat : 17|2@0+ (1,0) [0|3] "SED"  RFA_BLEM
 SG_ RmtCtlRightOrnt_D_Avail : 20|3@0+ (1,0) [0|7] "SED"  RFA_BLEM
 SG_ RmtCtlRight_D_Avail : 31|2@0+ (1,0) [0|3] "SED"  RFA_BLEM
 SG_ RmtCtlRear_D_Avail : 29|2@0+ (1,0) [0|3] "SED"  RFA_BLEM
 SG_ RmtCtlPrkMde_D_Stat : 9|2@0+ (1,0) [0|3] "SED"  RFA_BLEM
 SG_ RmtCtlPrkInSlot_D_Stat : 23|3@0+ (1,0) [0|7] "SED"  RFA_BLEM
 SG_ RmtCtlObstcl_B_Stat : 10|1@0+ (1,0) [0|1] "SED"  RFA_BLEM
 SG_ RmtCtlNxtMoveDir_D_Stat : 12|2@0+ (1,0) [0|3] "SED"  RFA_BLEM
 SG_ RmtCtlMoveDir_D_Stat : 1|2@0+ (1,0) [0|3] "SED"  RFA_BLEM
 SG_ RmtCtlLeftOrnt_D_Avail : 15|3@0+ (1,0) [0|7] "SED"  RFA_BLEM
 SG_ RmtCtlLeft_D_Avail : 3|2@0+ (1,0) [0|3] "SED"  RFA_BLEM
 SG_ RmtCtlFront_D_Avail : 5|2@0+ (1,0) [0|3] "SED"  RFA_BLEM

CM_ "FNV2 HS4 CAN";
CM_ BU_ TCU_FB5 "Feature Bundle 5 Slim TCU";
CM_ BU_ RFA_BLEM "Bluetooth Low Energy Module";
CM_ BU_ GWM "Gateway Module CGEA1.3(Star Architecture)";
CM_ BU_ GENERIC "holding pattern ECU for developmental messages";
CM_ BU_ TSTR "Diagnostic Tester";
CM_ SG_ 985 LongCtrlEnblDRq_No_Cs "Signal not transmitted on gas and diesel variants.";
CM_ SG_ 985 LongCtrlEnblDRq_No_Cnt "Signal not transmitted on gas and diesel variants.";
CM_ SG_ 942 PrkAidRdiusRight_L_Dsply "MSGDCR 679, set all signals to OnChange";
CM_ SG_ 942 PrkAidRdiusLeft_L_Dsply "MSGDCR 679, set all signals to OnChange";
CM_ SG_ 942 PrkAidDrvDir_D_Stat "MSGDCR 679, set all signals to OnChange";
CM_ SG_ 932 CanMsg3A4_No_Crc "Signal not transmitted on gas and HEV variants.";
CM_ SG_ 932 CanMsg3A4_No_Cnt "Signal not transmitted on gas and HEV variants.";
CM_ SG_ 118 SteWhlCompAnEst_D_Qf "Legacy signal not supported, reserving bit locations for commodity BCM, PAM, RCM, APIM dbc files.  GWM to Tx Init value, no valid data. ";
CM_ SG_ 118 SteWhlComp_An_Est "Legacy signal not supported, reserving bit locations for commodity BCM, PAM, RCM, APIM dbc files.  GWM to Tx Init value, no valid data. ";
CM_ SG_ 617 PaakTrgtActvData_No_Rq "Not transmitted on all vehicle variants";
CM_ SG_ 616 PaakTrgtPssvData_No_Rq "Not transmitted on all vehicle variants";
CM_ SG_ 619 PaakCtlActvData_No_Actl "Not transmitted on all vehicle variants";
CM_ SG_ 618 PaakCtlPssvData_No_Actl "Not transmitted on all vehicle variants";
CM_ BO_ 600 "Tx by HS3 APIM";
CM_ SG_ 600 APIM_RFA_BLEM_Tx "Tx by HS3 APIM";
CM_ BO_ 374 "Programs w/o HS1 0x172 will need HS1 0x176 for GearPos_D_Actl.  Future MY Programs that choose c/o still require HS1 0x172. ";
CM_ SG_ 374 TrnRng_D_Rq "Powersplit HEVs with HF45, HPCM will Tx  this message.  For all other programs it will be Tx by PCM or TCM. ";
CM_ SG_ 374 TrnPrkSys_D_Actl "Powersplit HEVs with HF45, HPCM will Tx  this message.  For all other programs it will be Tx by PCM or TCM. ";
CM_ SG_ 374 GearLvr_D_ActlDrv "Powersplit HEVs with HF45, HPCM will Tx  this message.  For all other programs it will be Tx by PCM or TCM. ";
CM_ SG_ 374 GearPos_No_Cs "Powersplit HEVs with HF45, HPCM will Tx  this message.  For all other programs it will be Tx by PCM or TCM. ";
CM_ SG_ 374 GearPos_D_Trg "Powersplit HEVs with HF45, HPCM will Tx  this message.  For all other programs it will be Tx by PCM or TCM. ";
CM_ SG_ 374 GearPos_No_Cnt "Powersplit HEVs with HF45, HPCM will Tx  this message.  For all other programs it will be Tx by PCM or TCM. ";
CM_ SG_ 374 GearPos_D_Actl "Powersplit HEVs with HF45, HPCM will Tx  this message.  For all other programs it will be Tx by PCM or TCM. ";
CM_ BO_ 651 "TCU CPPM Tx";
CM_ SG_ 516 EngAout3_N_Actl "Signal not transmitted on gas and diesel variants.";
CM_ SG_ 516 ApedPosPcActl_No_Cnt "Signal not transmitted on gas and diesel variants.";
CM_ SG_ 516 ApedPosPcActl_No_Cs "Signal not transmitted on gas and diesel variants.";
CM_ BO_ 531 "IC is NOT to use data in this message for displays, Used data from 415 instead.";
CM_ SG_ 1200 BrkTot_Tq_RqDrv "DCR 1836 to update Tx from GWM to EP100ms rejected due MPS6 TCM requires BrkTot_Tq_RqDrv at 20ms (bshu1).";
CM_ SG_ 931 CrnkInhbt_No_Cs "Signal not transmitted on gas and HEV variants.";
CM_ SG_ 931 CrnkInhbt_No_Cnt "Signal not transmitted on gas and HEV variants.";
BA_DEF_  "BusType" STRING ;
BA_DEF_ BO_  "FrameRouting" STRING ;
BA_DEF_ BO_  "FrameGatewayNetwork" STRING ;
BA_DEF_ BO_  "NetworkInitialization" ENUM  "No","Yes";
BA_DEF_ BO_  "FrameGatewayId" HEX 0 1407;
BA_DEF_ BO_  "EventRateOfChange" INT 10 10000;
BA_DEF_ BO_  "GenMsgNrOfRepetition" INT 0 100;
BA_DEF_ BO_  "GenMsgDelayTime" INT 0 1000;
BA_DEF_ BO_  "GenMsgCycleTime" INT 0 100000;
BA_DEF_ BO_  "GenMsgSendType" ENUM  "FixedPeriodic","Event","EnabledPeriodic","NotUsed","NotUsed","EventPeriodic","NotUsed","NotUsed","NoMsgSendType";
BA_DEF_ SG_  "U_CD764_MY2022_Tx" ENUM  "No","Yes";
BA_DEF_ SG_  "U_U55X_MY2022_Tx" ENUM  "No","Yes";
BA_DEF_ SG_  "U_CD542_MY2021_Tx" ENUM  "No","Yes";
BA_DEF_ SG_  "ECGUsedTxSignal" ENUM  "No","Yes";
BA_DEF_ SG_  "U_T6_MCA_MY2020_Tx" ENUM  "No","Yes";
BA_DEF_ SG_  "U_P702_MY2021_Tx" ENUM  "No","Yes";
BA_DEF_ SG_  "U_CX727_MY2021_Tx" ENUM  "No","Yes";
BA_DEF_ SG_  "U_CD764_MY2022_Rx" ENUM  "No","Yes";
BA_DEF_ SG_  "U_U55X_MY2022_Rx" ENUM  "No","Yes";
BA_DEF_ SG_  "U_CD542_MY2021_Rx" ENUM  "No","Yes";
BA_DEF_ SG_  "ECGUsedRxSignal" ENUM  "No","Yes";
BA_DEF_ SG_  "U_T6_MCA_MY2020_Rx" ENUM  "No","Yes";
BA_DEF_ SG_  "U_P702_MY2021_Rx" ENUM  "No","Yes";
BA_DEF_ SG_  "U_CX727_MY2021_Rx" ENUM  "No","Yes";
BA_DEF_ SG_  "GenSigStartValue" HEX 0 268435455;
BA_DEF_ SG_  "MetaData" ENUM  "No","Yes";
BA_DEF_ SG_  "ContentDependant" ENUM  "No","Yes";
BA_DEF_ SG_  "GenSigStartValueInteger" INT 0 1000000000;
BA_DEF_ SG_  "UsedOnPgmDBC" ENUM  "No","Yes";
BA_DEF_ SG_  "WakeupSignal" ENUM  "No","Yes";
BA_DEF_ SG_  "GenSigInactiveValue" INT 0 100000;
BA_DEF_ SG_  "GenSigSendType" ENUM  "Cyclic","OnWrite","vector_leerstring","OnChange","vector_leerstring","IfActive","vector_leerstring","NoSigSendType";
BA_DEF_ BO_  "OvtpPushApplication" ENUM  "FALSE","TRUE";
BA_DEF_ BO_  "SCP_FreshnessValueLength" INT 0 512;
BA_DEF_ BO_  "SCP_FreshnessValueTxLength" INT 0 512;
BA_DEF_ BO_  "SCP_AuthInfoTxLength" INT 0 512;
BA_DEF_ BO_  "GenMsgRoutingTimeoutTime" INT 0 5000;
BA_DEF_ BO_  "MessageGateway" ENUM  "No","Yes";
BA_DEF_ BO_  "NmAsrMessage" ENUM  "No","Yes";
BA_DEF_ BO_  "DiagState" ENUM  "No","Yes";
BA_DEF_ BO_  "TpTxIndex" INT 0 536870911;
BA_DEF_ BO_  "DiagRequest" ENUM  "No","Yes";
BA_DEF_ BO_  "DiagResponse" ENUM  "No","Yes";
BA_DEF_ BO_  "GenMsgILSupport" ENUM  "No","Yes";
BA_DEF_ BU_  "OvtpOperationMode" ENUM  "SERVER","CLIENT";
BA_DEF_ BU_  "OvtpEcuAddress" INT 0 1022;
BA_DEF_ BU_  "ILUsed" ENUM  "No","Yes";
BA_DEF_ BU_  "Terminator" ENUM  "No","Yes";
BA_DEF_ BU_  "NodeWakeUpTime" INT 0 10000;
BA_DEF_ BU_  "NodeStartUpTime" INT 0 10000;
BA_DEF_ BU_  "NmAsrNodeIdentifier" HEX 0 255;
BA_DEF_ BU_  "NmAsrNode" ENUM  "No","Yes";
BA_DEF_ BU_  "PowerType" ENUM  "Switched","Latched","Sleep","vector_leerstring","vector_leerstring";
BA_DEF_ BU_  "DiagNode" ENUM  "GGDS","GDS","NONE";
BA_DEF_ BU_  "EOL_SB_Flash" ENUM  "GGDS","GDS","NONE","vector_leerstring";
BA_DEF_ BU_  "NmNode" ENUM  "No","Yes";
BA_DEF_ BU_  "NmStationAddress" INT 0 255;
BA_DEF_ BU_  "NosPackage" ENUM  "None","I3_1","I3_2","1.0.1","RP","EuCD","Volcano","I3_3","FNOS_Autosar";
BA_DEF_ BU_  "PackageID" STRING ;
BA_DEF_ BU_  "GatewayECU" ENUM  "No","Yes";
BA_DEF_  "NetworkSpeed" ENUM  "500kBits/s","125kBit/s";
BA_DEF_  "VersionNumber" INT 0 10000;
BA_DEF_  "StarNetworkGwType" ENUM  "0=NotDefined","1=HS1","2=HS2","3=HS3","4=HS4","5=HS5","6=MS1","7=HS6","8=HS7","9=MS2","10=FD1","11=FD2","12=FD3","13=FD4","14=FD5","15=FD6","16=FD7","17=FD8";
BA_DEF_  "CMDB_Version" STRING ;
BA_DEF_  "NmType" STRING ;
BA_DEF_  "NmAsrMessageCount" INT 128 256;
BA_DEF_  "NmAsrBaseAddress" HEX 1280 1408;
BA_DEF_  "DBName" STRING ;
BA_DEF_  "VersionDay" INT 1 31;
BA_DEF_  "Manufacturer" STRING ;
BA_DEF_  "VersionMonth" INT 1 12;
BA_DEF_  "VersionYear" INT 2000 3000;
BA_DEF_  "NmBaseAddress" HEX 1280 1280;
BA_DEF_  "NmMessageCount" INT 0 128;
BA_DEF_DEF_  "BusType" "";
BA_DEF_DEF_  "FrameRouting" "";
BA_DEF_DEF_  "FrameGatewayNetwork" "NONE";
BA_DEF_DEF_  "NetworkInitialization" "Yes";
BA_DEF_DEF_  "FrameGatewayId" 0;
BA_DEF_DEF_  "EventRateOfChange" 10000;
BA_DEF_DEF_  "GenMsgNrOfRepetition" 1;
BA_DEF_DEF_  "GenMsgDelayTime" 20;
BA_DEF_DEF_  "GenMsgCycleTime" 0;
BA_DEF_DEF_  "GenMsgSendType" "NoMsgSendType";
BA_DEF_DEF_  "U_CD764_MY2022_Tx" "No";
BA_DEF_DEF_  "U_U55X_MY2022_Tx" "No";
BA_DEF_DEF_  "U_CD542_MY2021_Tx" "No";
BA_DEF_DEF_  "ECGUsedTxSignal" "No";
BA_DEF_DEF_  "U_T6_MCA_MY2020_Tx" "No";
BA_DEF_DEF_  "U_P702_MY2021_Tx" "No";
BA_DEF_DEF_  "U_CX727_MY2021_Tx" "No";
BA_DEF_DEF_  "U_CD764_MY2022_Rx" "No";
BA_DEF_DEF_  "U_U55X_MY2022_Rx" "No";
BA_DEF_DEF_  "U_CD542_MY2021_Rx" "No";
BA_DEF_DEF_  "ECGUsedRxSignal" "No";
BA_DEF_DEF_  "U_T6_MCA_MY2020_Rx" "No";
BA_DEF_DEF_  "U_P702_MY2021_Rx" "No";
BA_DEF_DEF_  "U_CX727_MY2021_Rx" "No";
BA_DEF_DEF_  "GenSigStartValue" 0;
BA_DEF_DEF_  "MetaData" "No";
BA_DEF_DEF_  "ContentDependant" "No";
BA_DEF_DEF_  "GenSigStartValueInteger" 0;
BA_DEF_DEF_  "UsedOnPgmDBC" "Yes";
BA_DEF_DEF_  "WakeupSignal" "No";
BA_DEF_DEF_  "GenSigInactiveValue" 0;
BA_DEF_DEF_  "GenSigSendType" "NoSigSendType";
BA_DEF_DEF_  "OvtpPushApplication" "FALSE";
BA_DEF_DEF_  "SCP_FreshnessValueLength" 64;
BA_DEF_DEF_  "SCP_FreshnessValueTxLength" 11;
BA_DEF_DEF_  "SCP_AuthInfoTxLength" 53;
BA_DEF_DEF_  "GenMsgRoutingTimeoutTime" 0;
BA_DEF_DEF_  "MessageGateway" "No";
BA_DEF_DEF_  "NmAsrMessage" "No";
BA_DEF_DEF_  "DiagState" "No";
BA_DEF_DEF_  "TpTxIndex" 0;
BA_DEF_DEF_  "DiagRequest" "No";
BA_DEF_DEF_  "DiagResponse" "No";
BA_DEF_DEF_  "GenMsgILSupport" "Yes";
BA_DEF_DEF_  "OvtpOperationMode" "SERVER";
BA_DEF_DEF_  "OvtpEcuAddress" 0;
BA_DEF_DEF_  "ILUsed" "Yes";
BA_DEF_DEF_  "Terminator" "No";
BA_DEF_DEF_  "NodeWakeUpTime" 100;
BA_DEF_DEF_  "NodeStartUpTime" 250;
BA_DEF_DEF_  "NmAsrNodeIdentifier" 128;
BA_DEF_DEF_  "NmAsrNode" "No";
BA_DEF_DEF_  "PowerType" "Switched";
BA_DEF_DEF_  "DiagNode" "GGDS";
BA_DEF_DEF_  "EOL_SB_Flash" "GGDS";
BA_DEF_DEF_  "NmNode" "No";
BA_DEF_DEF_  "NmStationAddress" 0;
BA_DEF_DEF_  "NosPackage" "I3_3";
BA_DEF_DEF_  "PackageID" "08.05.00.00.71.xx.xx.rr.00.00";
BA_DEF_DEF_  "GatewayECU" "No";
BA_DEF_DEF_  "NetworkSpeed" "500kBits/s";
BA_DEF_DEF_  "VersionNumber" 1;
BA_DEF_DEF_  "StarNetworkGwType" "0=NotDefined";
BA_DEF_DEF_  "CMDB_Version" "v11.01";
BA_DEF_DEF_  "NmType" "Ford-OSEK";
BA_DEF_DEF_  "NmAsrMessageCount" 128;
BA_DEF_DEF_  "NmAsrBaseAddress" 1408;
BA_DEF_DEF_  "DBName" "";
BA_DEF_DEF_  "VersionDay" 1;
BA_DEF_DEF_  "Manufacturer" "Ford";
BA_DEF_DEF_  "VersionMonth" 1;
BA_DEF_DEF_  "VersionYear" 2011;
BA_DEF_DEF_  "NmBaseAddress" 1280;
BA_DEF_DEF_  "NmMessageCount" 128;
BA_ "BusType" "CAN";
BA_ "VersionYear" 2020;
BA_ "VersionMonth" 10;
BA_ "VersionDay" 30;
BA_ "CMDB_Version" "FNV2_v20.12";
BA_ "StarNetworkGwType" 4;
BA_ "VersionNumber" 12;
BA_ "DBName" "HS4_CAN";
BA_ "NmStationAddress" BU_ TCU_FB5 16;
BA_ "PowerType" BU_ TCU_FB5 2;
BA_ "NmAsrNode" BU_ TCU_FB5 1;
BA_ "NmAsrNodeIdentifier" BU_ TCU_FB5 144;
BA_ "NodeWakeUpTime" BU_ TCU_FB5 60;
BA_ "Terminator" BU_ TCU_FB5 1;
BA_ "OvtpEcuAddress" BU_ TCU_FB5 145;
BA_ "PackageID" BU_ TCU_FB5 "08.05.11.3D.03.00.00.00.00.00";
BA_ "NmStationAddress" BU_ RFA_BLEM 8;
BA_ "PowerType" BU_ RFA_BLEM 2;
BA_ "NmAsrNode" BU_ RFA_BLEM 1;
BA_ "NmAsrNodeIdentifier" BU_ RFA_BLEM 136;
BA_ "NodeStartUpTime" BU_ RFA_BLEM 1000;
BA_ "NodeWakeUpTime" BU_ RFA_BLEM 200;
BA_ "OvtpEcuAddress" BU_ RFA_BLEM 76;
BA_ "NmStationAddress" BU_ GWM 30;
BA_ "PowerType" BU_ GWM 2;
BA_ "NmAsrNode" BU_ GWM 1;
BA_ "NmAsrNodeIdentifier" BU_ GWM 158;
BA_ "NodeStartUpTime" BU_ GWM 100;
BA_ "Terminator" BU_ GWM 1;
BA_ "OvtpEcuAddress" BU_ GWM 216;
BA_ "OvtpOperationMode" BU_ GWM 1;
BA_ "GatewayECU" BU_ GWM 1;
BA_ "NosPackage" BU_ GWM 4;
BA_ "FrameGatewayId" BO_ 1044 1044;
BA_ "FrameGatewayNetwork" BO_ 1044 "FD1_CAN";
BA_ "FrameRouting" BO_ 1044 "FD1_CAN,0x414;";
BA_ "FrameRouting" BO_ 517 "FD1_CAN,0x205;";
BA_ "FrameGatewayNetwork" BO_ 517 "FD1_CAN";
BA_ "FrameGatewayId" BO_ 517 517;
BA_ "FrameRouting" BO_ 985 "FD1_CAN,0x3D9;";
BA_ "FrameGatewayNetwork" BO_ 985 "FD1_CAN";
BA_ "FrameGatewayId" BO_ 985 985;
BA_ "FrameGatewayId" BO_ 942 942;
BA_ "FrameGatewayNetwork" BO_ 942 "FD1_CAN";
BA_ "FrameRouting" BO_ 942 "FD1_CAN,0x3AE;HS2_CAN,0x3EA;";
BA_ "GenMsgSendType" BO_ 624 5;
BA_ "GenMsgCycleTime" BO_ 624 1000;
BA_ "GenMsgSendType" BO_ 621 5;
BA_ "GenMsgCycleTime" BO_ 621 200;
BA_ "FrameGatewayId" BO_ 622 622;
BA_ "FrameGatewayNetwork" BO_ 622 "HS1_CAN";
BA_ "FrameRouting" BO_ 622 "HS1_CAN,0x26E;";
BA_ "FrameGatewayId" BO_ 932 932;
BA_ "FrameGatewayNetwork" BO_ 932 "HS1_CAN";
BA_ "FrameRouting" BO_ 932 "HS1_CAN,0x3A4;";
BA_ "FrameGatewayId" BO_ 118 118;
BA_ "FrameGatewayNetwork" BO_ 118 "FD1_CAN";
BA_ "FrameRouting" BO_ 118 "FD1_CAN,0x76;";
BA_ "TpTxIndex" BO_ 2612080856 464597208;
BA_ "OvtpPushApplication" BO_ 2612080856 1;
BA_ "GenMsgSendType" BO_ 2612080856 1;
BA_ "GenMsgDelayTime" BO_ 2612080856 0;
BA_ "TpTxIndex" BO_ 2610126924 462500056;
BA_ "GenMsgSendType" BO_ 2610126924 1;
BA_ "GenMsgDelayTime" BO_ 2610126924 0;
BA_ "FrameGatewayId" BO_ 617 1129;
BA_ "FrameGatewayNetwork" BO_ 617 "HS1_CAN";
BA_ "FrameRouting" BO_ 617 "HS1_CAN,0x469;";
BA_ "FrameGatewayId" BO_ 616 1128;
BA_ "FrameGatewayNetwork" BO_ 616 "HS1_CAN";
BA_ "FrameRouting" BO_ 616 "HS1_CAN,0x468;";
BA_ "GenMsgSendType" BO_ 620 5;
BA_ "GenMsgCycleTime" BO_ 620 200;
BA_ "GenMsgSendType" BO_ 619 5;
BA_ "GenMsgCycleTime" BO_ 619 200;
BA_ "GenMsgSendType" BO_ 618 5;
BA_ "GenMsgCycleTime" BO_ 618 200;
BA_ "TpTxIndex" BO_ 600 50;
BA_ "FrameGatewayId" BO_ 600 600;
BA_ "FrameGatewayNetwork" BO_ 600 "HS3_CAN";
BA_ "FrameRouting" BO_ 600 "HS3_CAN,0x258;";
BA_ "TpTxIndex" BO_ 592 50;
BA_ "MessageGateway" BO_ 357 1;
BA_ "GenMsgRoutingTimeoutTime" BO_ 357 60;
BA_ "GenMsgSendType" BO_ 357 5;
BA_ "GenMsgCycleTime" BO_ 357 1000;
BA_ "FrameGatewayId" BO_ 374 374;
BA_ "FrameGatewayNetwork" BO_ 374 "FD1_CAN";
BA_ "FrameRouting" BO_ 374 "FD1_CAN,0x176;";
BA_ "FrameGatewayId" BO_ 500 1012;
BA_ "FrameGatewayNetwork" BO_ 500 "FD1_CAN";
BA_ "FrameRouting" BO_ 500 "FD1_CAN,0x3F4;";
BA_ "FrameGatewayId" BO_ 322 1090;
BA_ "FrameGatewayNetwork" BO_ 322 "FD1_CAN";
BA_ "FrameRouting" BO_ 322 "FD1_CAN,0x442;";
BA_ "FrameGatewayId" BO_ 1087 1087;
BA_ "FrameGatewayNetwork" BO_ 1087 "FD1_CAN";
BA_ "FrameRouting" BO_ 1087 "FD1_CAN,0x43F;";
BA_ "FrameGatewayId" BO_ 341 261;
BA_ "FrameGatewayNetwork" BO_ 341 "HS3_CAN";
BA_ "FrameRouting" BO_ 341 "HS3_CAN,0x105;";
BA_ "GenMsgSendType" BO_ 651 5;
BA_ "GenMsgCycleTime" BO_ 651 1000;
BA_ "MessageGateway" BO_ 516 1;
BA_ "GenMsgRoutingTimeoutTime" BO_ 516 60;
BA_ "GenMsgSendType" BO_ 516 0;
BA_ "GenMsgCycleTime" BO_ 516 200;
BA_ "MessageGateway" BO_ 531 1;
BA_ "GenMsgRoutingTimeoutTime" BO_ 531 600;
BA_ "GenMsgSendType" BO_ 531 0;
BA_ "GenMsgCycleTime" BO_ 531 200;
BA_ "FrameGatewayId" BO_ 1054 1054;
BA_ "FrameGatewayNetwork" BO_ 1054 "FD1_CAN";
BA_ "FrameRouting" BO_ 1054 "FD1_CAN,0x41E;";
BA_ "MessageGateway" BO_ 1200 1;
BA_ "GenMsgRoutingTimeoutTime" BO_ 1200 600;
BA_ "GenMsgSendType" BO_ 1200 0;
BA_ "GenMsgCycleTime" BO_ 1200 200;
BA_ "FrameGatewayId" BO_ 931 931;
BA_ "FrameGatewayNetwork" BO_ 931 "HS1_CAN";
BA_ "FrameRouting" BO_ 931 "HS1_CAN,0x3A3;";
BA_ "FrameGatewayId" BO_ 1234 1234;
BA_ "FrameGatewayNetwork" BO_ 1234 "FD1_CAN";
BA_ "FrameRouting" BO_ 1234 "FD1_CAN,0x4D2;";
BA_ "FrameGatewayId" BO_ 1233 1233;
BA_ "FrameGatewayNetwork" BO_ 1233 "FD1_CAN";
BA_ "FrameRouting" BO_ 1233 "FD1_CAN,0x4D1;";
BA_ "MetaData" SG_ 1044 ApaBrkErrDStat_No_Cs 1;
BA_ "MetaData" SG_ 1044 ApaBrkErrDStat_No_Cnt 1;
BA_ "GenSigStartValue" SG_ 1044 ApaBrkErr_D_Stat 2;
BA_ "MetaData" SG_ 985 LongCtrlEnblDRq_No_Cs 1;
BA_ "ContentDependant" SG_ 985 LongCtrlEnblDRq_No_Cs 1;
BA_ "MetaData" SG_ 985 LongCtrlEnblDRq_No_Cnt 1;
BA_ "ContentDependant" SG_ 985 LongCtrlEnblDRq_No_Cnt 1;
BA_ "GenSigStartValue" SG_ 942 ApaOffOptnSel_B_Avail 1;
BA_ "U_CX727_MY2021_Tx" SG_ 624 PaakAddEraseIndx_No_Rq 1;
BA_ "U_CD542_MY2021_Tx" SG_ 624 PaakAddEraseIndx_No_Rq 1;
BA_ "U_U55X_MY2022_Tx" SG_ 624 PaakAddEraseIndx_No_Rq 1;
BA_ "U_CD764_MY2022_Tx" SG_ 624 PaakAddEraseIndx_No_Rq 1;
BA_ "GenSigSendType" SG_ 624 PaakAddErase_D_Rq 3;
BA_ "U_CX727_MY2021_Tx" SG_ 624 PaakAddErase_D_Rq 1;
BA_ "U_CD542_MY2021_Tx" SG_ 624 PaakAddErase_D_Rq 1;
BA_ "U_U55X_MY2022_Tx" SG_ 624 PaakAddErase_D_Rq 1;
BA_ "U_CD764_MY2022_Tx" SG_ 624 PaakAddErase_D_Rq 1;
BA_ "GenSigSendType" SG_ 621 IgnPsswrdActv_B_Stat 3;
BA_ "U_CX727_MY2021_Tx" SG_ 621 IgnPsswrdActv_B_Stat 1;
BA_ "U_CD542_MY2021_Tx" SG_ 621 IgnPsswrdActv_B_Stat 1;
BA_ "U_U55X_MY2022_Tx" SG_ 621 IgnPsswrdActv_B_Stat 1;
BA_ "U_CD764_MY2022_Tx" SG_ 621 IgnPsswrdActv_B_Stat 1;
BA_ "GenSigSendType" SG_ 621 FobTrgtZone_D_Rq 3;
BA_ "U_CX727_MY2021_Tx" SG_ 621 FobTrgtZone_D_Rq 1;
BA_ "U_CD542_MY2021_Tx" SG_ 621 FobTrgtZone_D_Rq 1;
BA_ "U_U55X_MY2022_Tx" SG_ 621 FobTrgtZone_D_Rq 1;
BA_ "U_CD764_MY2022_Tx" SG_ 621 FobTrgtZone_D_Rq 1;
BA_ "GenSigSendType" SG_ 621 FobTrgtType_D_Rq 3;
BA_ "U_CX727_MY2021_Tx" SG_ 621 FobTrgtType_D_Rq 1;
BA_ "U_CD542_MY2021_Tx" SG_ 621 FobTrgtType_D_Rq 1;
BA_ "U_U55X_MY2022_Tx" SG_ 621 FobTrgtType_D_Rq 1;
BA_ "U_CD764_MY2022_Tx" SG_ 621 FobTrgtType_D_Rq 1;
BA_ "GenSigSendType" SG_ 621 FobTrgtRollCode_No_Rq 3;
BA_ "U_CX727_MY2021_Tx" SG_ 621 FobTrgtRollCode_No_Rq 1;
BA_ "U_CD542_MY2021_Tx" SG_ 621 FobTrgtRollCode_No_Rq 1;
BA_ "U_U55X_MY2022_Tx" SG_ 621 FobTrgtRollCode_No_Rq 1;
BA_ "U_CD764_MY2022_Tx" SG_ 621 FobTrgtRollCode_No_Rq 1;
BA_ "U_CX727_MY2021_Tx" SG_ 621 FobTrgtPssvData_No_Rq 1;
BA_ "U_CD542_MY2021_Tx" SG_ 621 FobTrgtPssvData_No_Rq 1;
BA_ "U_U55X_MY2022_Tx" SG_ 621 FobTrgtPssvData_No_Rq 1;
BA_ "U_CD764_MY2022_Tx" SG_ 621 FobTrgtPssvData_No_Rq 1;
BA_ "GenSigSendType" SG_ 621 RmtCtlSelSlot_D_Rq 3;
BA_ "U_U55X_MY2022_Tx" SG_ 621 RmtCtlSelSlot_D_Rq 1;
BA_ "GenSigSendType" SG_ 621 RmtCtlSelPrkMde_D_Rq 3;
BA_ "U_U55X_MY2022_Tx" SG_ 621 RmtCtlSelPrkMde_D_Rq 1;
BA_ "GenSigSendType" SG_ 621 RmtCtlSelMoveDir_D_Rq 3;
BA_ "U_U55X_MY2022_Tx" SG_ 621 RmtCtlSelMoveDir_D_Rq 1;
BA_ "GenSigSendType" SG_ 621 RmtCtlRjctAutoCfg_B_Rq 3;
BA_ "U_U55X_MY2022_Tx" SG_ 621 RmtCtlRjctAutoCfg_B_Rq 1;
BA_ "U_CX727_MY2021_Rx" SG_ 622 FobCtlType_D_Stat 1;
BA_ "U_CD542_MY2021_Rx" SG_ 622 FobCtlType_D_Stat 1;
BA_ "U_U55X_MY2022_Rx" SG_ 622 FobCtlType_D_Stat 1;
BA_ "U_CD764_MY2022_Rx" SG_ 622 FobCtlType_D_Stat 1;
BA_ "U_CX727_MY2021_Rx" SG_ 622 FobCtlRollCode_No_Stat 1;
BA_ "U_CD542_MY2021_Rx" SG_ 622 FobCtlRollCode_No_Stat 1;
BA_ "U_U55X_MY2022_Rx" SG_ 622 FobCtlRollCode_No_Stat 1;
BA_ "U_CD764_MY2022_Rx" SG_ 622 FobCtlRollCode_No_Stat 1;
BA_ "U_CX727_MY2021_Rx" SG_ 622 FobCtlPssvData_No_Actl 1;
BA_ "U_CD542_MY2021_Rx" SG_ 622 FobCtlPssvData_No_Actl 1;
BA_ "U_U55X_MY2022_Rx" SG_ 622 FobCtlPssvData_No_Actl 1;
BA_ "U_CD764_MY2022_Rx" SG_ 622 FobCtlPssvData_No_Actl 1;
BA_ "ContentDependant" SG_ 932 CanMsg3A4_No_Crc 1;
BA_ "MetaData" SG_ 932 CanMsg3A4_No_Crc 1;
BA_ "ContentDependant" SG_ 932 CanMsg3A4_No_Cnt 1;
BA_ "MetaData" SG_ 932 CanMsg3A4_No_Cnt 1;
BA_ "GenSigStartValueInteger" SG_ 118 DrvSte_Tq_Rq 128;
BA_ "ContentDependant" SG_ 118 SteWhlCompAnEst_D_Qf 1;
BA_ "MetaData" SG_ 118 SteWhlCompAnEst_D_Qf 1;
BA_ "ContentDependant" SG_ 118 SteWhlComp_An_Est 1;
BA_ "GenSigSendType" SG_ 2612080856 PARSEDPushFcGWM_ECGtoRFA 3;
BA_ "U_CD764_MY2022_Rx" SG_ 2612080856 PARSEDPushFcGWM_ECGtoRFA 1;
BA_ "ECGUsedTxSignal" SG_ 2612080856 PARSEDPushFcGWM_ECGtoRFA 1;
BA_ "U_CD764_MY2022_Tx" SG_ 2612080856 PARSEDPushFcGWM_ECGtoRFA 1;
BA_ "GenSigSendType" SG_ 2610126924 OTAPhysRFAtoGWM_ECG 3;
BA_ "ECGUsedRxSignal" SG_ 2610126924 OTAPhysRFAtoGWM_ECG 1;
BA_ "U_CD764_MY2022_Rx" SG_ 2610126924 OTAPhysRFAtoGWM_ECG 1;
BA_ "U_CD764_MY2022_Tx" SG_ 2610126924 OTAPhysRFAtoGWM_ECG 1;
BA_ "U_CD764_MY2022_Rx" SG_ 617 PaaKMyKeyChng_No_Actl 1;
BA_ "U_CD764_MY2022_Rx" SG_ 617 PaaKMyKeyChng_D_Stat 1;
BA_ "U_CX727_MY2021_Rx" SG_ 617 PaakAddEraseIndx_No_Actl 1;
BA_ "U_CD542_MY2021_Rx" SG_ 617 PaakAddEraseIndx_No_Actl 1;
BA_ "U_U55X_MY2022_Rx" SG_ 617 PaakAddEraseIndx_No_Actl 1;
BA_ "U_CD764_MY2022_Rx" SG_ 617 PaakAddEraseIndx_No_Actl 1;
BA_ "U_CX727_MY2021_Rx" SG_ 617 PaakAddErase_D_Stat 1;
BA_ "U_CD542_MY2021_Rx" SG_ 617 PaakAddErase_D_Stat 1;
BA_ "U_U55X_MY2022_Rx" SG_ 617 PaakAddErase_D_Stat 1;
BA_ "U_CD764_MY2022_Rx" SG_ 617 PaakAddErase_D_Stat 1;
BA_ "ContentDependant" SG_ 617 PaakTrgtActvData_No_Rq 1;
BA_ "U_CX727_MY2021_Rx" SG_ 617 PaakTrgtActvData_No_Rq 1;
BA_ "U_CD542_MY2021_Rx" SG_ 617 PaakTrgtActvData_No_Rq 1;
BA_ "U_U55X_MY2022_Rx" SG_ 617 PaakTrgtActvData_No_Rq 1;
BA_ "U_CD764_MY2022_Rx" SG_ 617 PaakTrgtActvData_No_Rq 1;
BA_ "U_CX727_MY2021_Rx" SG_ 616 KeyPadCodeProg_D_Stat 1;
BA_ "U_CD542_MY2021_Rx" SG_ 616 KeyPadCodeProg_D_Stat 1;
BA_ "U_U55X_MY2022_Rx" SG_ 616 KeyPadCodeProg_D_Stat 1;
BA_ "U_CD764_MY2022_Rx" SG_ 616 KeyPadCodeProg_D_Stat 1;
BA_ "WakeupSignal" SG_ 616 PaakTrgtPreAuthrz_B_Rq 1;
BA_ "U_U55X_MY2022_Rx" SG_ 616 PaakTrgtPreAuthrz_B_Rq 1;
BA_ "ContentDependant" SG_ 616 PaakTrgtPssvData_No_Rq 1;
BA_ "U_CX727_MY2021_Rx" SG_ 616 PaakTrgtPssvData_No_Rq 1;
BA_ "U_CD542_MY2021_Rx" SG_ 616 PaakTrgtPssvData_No_Rq 1;
BA_ "U_U55X_MY2022_Rx" SG_ 616 PaakTrgtPssvData_No_Rq 1;
BA_ "U_CD764_MY2022_Rx" SG_ 616 PaakTrgtPssvData_No_Rq 1;
BA_ "WakeupSignal" SG_ 616 PaakTrgtType_D_Rq 1;
BA_ "U_CX727_MY2021_Rx" SG_ 616 PaakTrgtType_D_Rq 1;
BA_ "U_CD542_MY2021_Rx" SG_ 616 PaakTrgtType_D_Rq 1;
BA_ "U_U55X_MY2022_Rx" SG_ 616 PaakTrgtType_D_Rq 1;
BA_ "U_CD764_MY2022_Rx" SG_ 616 PaakTrgtType_D_Rq 1;
BA_ "U_CX727_MY2021_Rx" SG_ 616 PaakTrgtRollCode_No_Rq 1;
BA_ "U_CD542_MY2021_Rx" SG_ 616 PaakTrgtRollCode_No_Rq 1;
BA_ "U_U55X_MY2022_Rx" SG_ 616 PaakTrgtRollCode_No_Rq 1;
BA_ "U_CD764_MY2022_Rx" SG_ 616 PaakTrgtRollCode_No_Rq 1;
BA_ "U_CX727_MY2021_Rx" SG_ 616 PaakTrgtZone_D_Rq 1;
BA_ "U_CD542_MY2021_Rx" SG_ 616 PaakTrgtZone_D_Rq 1;
BA_ "U_U55X_MY2022_Rx" SG_ 616 PaakTrgtZone_D_Rq 1;
BA_ "U_CD764_MY2022_Rx" SG_ 616 PaakTrgtZone_D_Rq 1;
BA_ "U_CX727_MY2021_Rx" SG_ 616 PaakTrgtData_D_Rq 1;
BA_ "U_CD542_MY2021_Rx" SG_ 616 PaakTrgtData_D_Rq 1;
BA_ "U_U55X_MY2022_Rx" SG_ 616 PaakTrgtData_D_Rq 1;
BA_ "U_CD764_MY2022_Rx" SG_ 616 PaakTrgtData_D_Rq 1;
BA_ "GenSigSendType" SG_ 620 PaakCtlIndx8_No_Actl 3;
BA_ "U_CX727_MY2021_Tx" SG_ 620 PaakCtlIndx8_No_Actl 1;
BA_ "U_CD542_MY2021_Tx" SG_ 620 PaakCtlIndx8_No_Actl 1;
BA_ "U_U55X_MY2022_Tx" SG_ 620 PaakCtlIndx8_No_Actl 1;
BA_ "U_CD764_MY2022_Tx" SG_ 620 PaakCtlIndx8_No_Actl 1;
BA_ "GenSigSendType" SG_ 620 PaakCtlIndx7_No_Actl 3;
BA_ "U_CX727_MY2021_Tx" SG_ 620 PaakCtlIndx7_No_Actl 1;
BA_ "U_CD542_MY2021_Tx" SG_ 620 PaakCtlIndx7_No_Actl 1;
BA_ "U_U55X_MY2022_Tx" SG_ 620 PaakCtlIndx7_No_Actl 1;
BA_ "U_CD764_MY2022_Tx" SG_ 620 PaakCtlIndx7_No_Actl 1;
BA_ "GenSigSendType" SG_ 620 PaakCtlIndx6_No_Actl 3;
BA_ "U_CX727_MY2021_Tx" SG_ 620 PaakCtlIndx6_No_Actl 1;
BA_ "U_CD542_MY2021_Tx" SG_ 620 PaakCtlIndx6_No_Actl 1;
BA_ "U_U55X_MY2022_Tx" SG_ 620 PaakCtlIndx6_No_Actl 1;
BA_ "U_CD764_MY2022_Tx" SG_ 620 PaakCtlIndx6_No_Actl 1;
BA_ "GenSigSendType" SG_ 620 PaakCtlIndx5_No_Actl 3;
BA_ "U_CX727_MY2021_Tx" SG_ 620 PaakCtlIndx5_No_Actl 1;
BA_ "U_CD542_MY2021_Tx" SG_ 620 PaakCtlIndx5_No_Actl 1;
BA_ "U_U55X_MY2022_Tx" SG_ 620 PaakCtlIndx5_No_Actl 1;
BA_ "U_CD764_MY2022_Tx" SG_ 620 PaakCtlIndx5_No_Actl 1;
BA_ "GenSigSendType" SG_ 620 PaakCtlIndx4_No_Actl 3;
BA_ "U_CX727_MY2021_Tx" SG_ 620 PaakCtlIndx4_No_Actl 1;
BA_ "U_CD542_MY2021_Tx" SG_ 620 PaakCtlIndx4_No_Actl 1;
BA_ "U_U55X_MY2022_Tx" SG_ 620 PaakCtlIndx4_No_Actl 1;
BA_ "U_CD764_MY2022_Tx" SG_ 620 PaakCtlIndx4_No_Actl 1;
BA_ "GenSigSendType" SG_ 620 PaakCtlIndx3_No_Actl 3;
BA_ "U_CX727_MY2021_Tx" SG_ 620 PaakCtlIndx3_No_Actl 1;
BA_ "U_CD542_MY2021_Tx" SG_ 620 PaakCtlIndx3_No_Actl 1;
BA_ "U_U55X_MY2022_Tx" SG_ 620 PaakCtlIndx3_No_Actl 1;
BA_ "U_CD764_MY2022_Tx" SG_ 620 PaakCtlIndx3_No_Actl 1;
BA_ "GenSigSendType" SG_ 620 PaakCtlIndx2_No_Actl 3;
BA_ "U_CX727_MY2021_Tx" SG_ 620 PaakCtlIndx2_No_Actl 1;
BA_ "U_CD542_MY2021_Tx" SG_ 620 PaakCtlIndx2_No_Actl 1;
BA_ "U_U55X_MY2022_Tx" SG_ 620 PaakCtlIndx2_No_Actl 1;
BA_ "U_CD764_MY2022_Tx" SG_ 620 PaakCtlIndx2_No_Actl 1;
BA_ "GenSigSendType" SG_ 620 PaakCtlIndx1_No_Actl 3;
BA_ "U_CX727_MY2021_Tx" SG_ 620 PaakCtlIndx1_No_Actl 1;
BA_ "U_CD542_MY2021_Tx" SG_ 620 PaakCtlIndx1_No_Actl 1;
BA_ "U_U55X_MY2022_Tx" SG_ 620 PaakCtlIndx1_No_Actl 1;
BA_ "U_CD764_MY2022_Tx" SG_ 620 PaakCtlIndx1_No_Actl 1;
BA_ "GenSigSendType" SG_ 620 PaakCtlRollCode_No_Copy 3;
BA_ "U_CX727_MY2021_Tx" SG_ 620 PaakCtlRollCode_No_Copy 1;
BA_ "U_CD542_MY2021_Tx" SG_ 620 PaakCtlRollCode_No_Copy 1;
BA_ "U_U55X_MY2022_Tx" SG_ 620 PaakCtlRollCode_No_Copy 1;
BA_ "U_CD764_MY2022_Tx" SG_ 620 PaakCtlRollCode_No_Copy 1;
BA_ "GenSigSendType" SG_ 619 KeyPadCodeProg_D_Rq 3;
BA_ "U_CX727_MY2021_Tx" SG_ 619 KeyPadCodeProg_D_Rq 1;
BA_ "U_CD542_MY2021_Tx" SG_ 619 KeyPadCodeProg_D_Rq 1;
BA_ "U_U55X_MY2022_Tx" SG_ 619 KeyPadCodeProg_D_Rq 1;
BA_ "U_CD764_MY2022_Tx" SG_ 619 KeyPadCodeProg_D_Rq 1;
BA_ "GenSigSendType" SG_ 619 PaakCnnct_D_Stat 3;
BA_ "U_CX727_MY2021_Tx" SG_ 619 PaakCnnct_D_Stat 1;
BA_ "U_CD542_MY2021_Tx" SG_ 619 PaakCnnct_D_Stat 1;
BA_ "U_U55X_MY2022_Tx" SG_ 619 PaakCnnct_D_Stat 1;
BA_ "U_CD764_MY2022_Tx" SG_ 619 PaakCnnct_D_Stat 1;
BA_ "U_CX727_MY2021_Tx" SG_ 619 PaakCtlActv_No_Actl 1;
BA_ "U_CD542_MY2021_Tx" SG_ 619 PaakCtlActv_No_Actl 1;
BA_ "U_U55X_MY2022_Tx" SG_ 619 PaakCtlActv_No_Actl 1;
BA_ "U_CD764_MY2022_Tx" SG_ 619 PaakCtlActv_No_Actl 1;
BA_ "WakeupSignal" SG_ 619 PaakCtlActv_D_Rq 1;
BA_ "GenSigSendType" SG_ 619 PaakCtlActv_D_Rq 3;
BA_ "U_CX727_MY2021_Tx" SG_ 619 PaakCtlActv_D_Rq 1;
BA_ "U_CD542_MY2021_Tx" SG_ 619 PaakCtlActv_D_Rq 1;
BA_ "U_U55X_MY2022_Tx" SG_ 619 PaakCtlActv_D_Rq 1;
BA_ "U_CD764_MY2022_Tx" SG_ 619 PaakCtlActv_D_Rq 1;
BA_ "ContentDependant" SG_ 619 PaakCtlActvData_No_Actl 1;
BA_ "U_CX727_MY2021_Tx" SG_ 619 PaakCtlActvData_No_Actl 1;
BA_ "U_CD542_MY2021_Tx" SG_ 619 PaakCtlActvData_No_Actl 1;
BA_ "U_U55X_MY2022_Tx" SG_ 619 PaakCtlActvData_No_Actl 1;
BA_ "U_CD764_MY2022_Tx" SG_ 619 PaakCtlActvData_No_Actl 1;
BA_ "GenSigSendType" SG_ 618 IgnPsswrdSetup_B_Rq 3;
BA_ "U_CX727_MY2021_Tx" SG_ 618 IgnPsswrdSetup_B_Rq 1;
BA_ "U_CD542_MY2021_Tx" SG_ 618 IgnPsswrdSetup_B_Rq 1;
BA_ "U_U55X_MY2022_Tx" SG_ 618 IgnPsswrdSetup_B_Rq 1;
BA_ "U_CD764_MY2022_Tx" SG_ 618 IgnPsswrdSetup_B_Rq 1;
BA_ "GenSigSendType" SG_ 618 IgnPsswrdLckout_B_Stat 3;
BA_ "U_CX727_MY2021_Tx" SG_ 618 IgnPsswrdLckout_B_Stat 1;
BA_ "U_CD542_MY2021_Tx" SG_ 618 IgnPsswrdLckout_B_Stat 1;
BA_ "U_U55X_MY2022_Tx" SG_ 618 IgnPsswrdLckout_B_Stat 1;
BA_ "U_CD764_MY2022_Tx" SG_ 618 IgnPsswrdLckout_B_Stat 1;
BA_ "WakeupSignal" SG_ 618 PaakLoclzd_D_Stat 1;
BA_ "GenSigSendType" SG_ 618 PaakLoclzd_D_Stat 3;
BA_ "U_CD542_MY2021_Tx" SG_ 618 PaakLoclzd_D_Stat 1;
BA_ "U_U55X_MY2022_Tx" SG_ 618 PaakLoclzd_D_Stat 1;
BA_ "WakeupSignal" SG_ 618 PaakCtlType_D_Stat 1;
BA_ "GenSigSendType" SG_ 618 PaakCtlType_D_Stat 3;
BA_ "U_CX727_MY2021_Tx" SG_ 618 PaakCtlType_D_Stat 1;
BA_ "U_CD542_MY2021_Tx" SG_ 618 PaakCtlType_D_Stat 1;
BA_ "U_U55X_MY2022_Tx" SG_ 618 PaakCtlType_D_Stat 1;
BA_ "U_CD764_MY2022_Tx" SG_ 618 PaakCtlType_D_Stat 1;
BA_ "WakeupSignal" SG_ 618 PaakCtlRollCode_No_Stat 1;
BA_ "U_CX727_MY2021_Tx" SG_ 618 PaakCtlRollCode_No_Stat 1;
BA_ "U_CD542_MY2021_Tx" SG_ 618 PaakCtlRollCode_No_Stat 1;
BA_ "U_U55X_MY2022_Tx" SG_ 618 PaakCtlRollCode_No_Stat 1;
BA_ "U_CD764_MY2022_Tx" SG_ 618 PaakCtlRollCode_No_Stat 1;
BA_ "WakeupSignal" SG_ 618 PaakCtlPssvData_No_Actl 1;
BA_ "ContentDependant" SG_ 618 PaakCtlPssvData_No_Actl 1;
BA_ "U_CX727_MY2021_Tx" SG_ 618 PaakCtlPssvData_No_Actl 1;
BA_ "U_CD542_MY2021_Tx" SG_ 618 PaakCtlPssvData_No_Actl 1;
BA_ "U_U55X_MY2022_Tx" SG_ 618 PaakCtlPssvData_No_Actl 1;
BA_ "U_CD764_MY2022_Tx" SG_ 618 PaakCtlPssvData_No_Actl 1;
BA_ "WakeupSignal" SG_ 618 PaakCtlData_D_Stat 1;
BA_ "GenSigSendType" SG_ 618 PaakCtlData_D_Stat 3;
BA_ "U_CX727_MY2021_Tx" SG_ 618 PaakCtlData_D_Stat 1;
BA_ "U_CD542_MY2021_Tx" SG_ 618 PaakCtlData_D_Stat 1;
BA_ "U_U55X_MY2022_Tx" SG_ 618 PaakCtlData_D_Stat 1;
BA_ "U_CD764_MY2022_Tx" SG_ 618 PaakCtlData_D_Stat 1;
BA_ "U_CX727_MY2021_Rx" SG_ 600 APIM_RFA_BLEM_Tx 1;
BA_ "U_CD542_MY2021_Rx" SG_ 600 APIM_RFA_BLEM_Tx 1;
BA_ "U_U55X_MY2022_Rx" SG_ 600 APIM_RFA_BLEM_Tx 1;
BA_ "U_CD764_MY2022_Rx" SG_ 600 APIM_RFA_BLEM_Tx 1;
BA_ "U_CX727_MY2021_Tx" SG_ 592 RFA_BLEM_APIM_Tx 1;
BA_ "U_CD542_MY2021_Tx" SG_ 592 RFA_BLEM_APIM_Tx 1;
BA_ "U_U55X_MY2022_Tx" SG_ 592 RFA_BLEM_APIM_Tx 1;
BA_ "U_CD764_MY2022_Tx" SG_ 592 RFA_BLEM_APIM_Tx 1;
BA_ "GenSigStartValueInteger" SG_ 357 BPedDrvAppl_D_QF 1;
BA_ "MetaData" SG_ 357 BPedDrvAppl_D_QF 1;
BA_ "GenSigStartValue" SG_ 357 BPedDrvAppl_D_QF 1;
BA_ "MetaData" SG_ 357 BpedDrvAppl_No_Cs 1;
BA_ "MetaData" SG_ 357 BpedDrvAppl_No_Cnt 1;
BA_ "GenSigStartValueInteger" SG_ 357 BpedDrvAppl_D_Actl 1;
BA_ "GenSigStartValue" SG_ 357 BpedDrvAppl_D_Actl 1;
BA_ "GenSigSendType" SG_ 357 BpedDrvAppl_D_Actl 3;
BA_ "U_U55X_MY2022_Rx" SG_ 357 BpedDrvAppl_D_Actl 1;
BA_ "GenSigStartValueInteger" SG_ 374 TrnRng_D_Rq 14;
BA_ "ContentDependant" SG_ 374 TrnRng_D_Rq 1;
BA_ "GenSigStartValue" SG_ 374 TrnRng_D_Rq 14;
BA_ "ContentDependant" SG_ 374 TrnPrkSys_D_Actl 1;
BA_ "U_U55X_MY2022_Rx" SG_ 374 TrnPrkSys_D_Actl 1;
BA_ "ContentDependant" SG_ 374 GearLvr_D_ActlDrv 1;
BA_ "U_U55X_MY2022_Rx" SG_ 374 GearLvr_D_ActlDrv 1;
BA_ "ContentDependant" SG_ 374 GearPos_No_Cs 1;
BA_ "MetaData" SG_ 374 GearPos_No_Cs 1;
BA_ "U_U55X_MY2022_Rx" SG_ 374 GearPos_No_Cs 1;
BA_ "GenSigStartValueInteger" SG_ 374 GearPos_D_Trg 15;
BA_ "ContentDependant" SG_ 374 GearPos_D_Trg 1;
BA_ "GenSigStartValue" SG_ 374 GearPos_D_Trg 15;
BA_ "U_U55X_MY2022_Rx" SG_ 374 GearPos_D_Trg 1;
BA_ "ContentDependant" SG_ 374 GearPos_No_Cnt 1;
BA_ "MetaData" SG_ 374 GearPos_No_Cnt 1;
BA_ "U_U55X_MY2022_Rx" SG_ 374 GearPos_No_Cnt 1;
BA_ "GenSigStartValueInteger" SG_ 374 GearPos_D_Actl 15;
BA_ "ContentDependant" SG_ 374 GearPos_D_Actl 1;
BA_ "GenSigStartValue" SG_ 374 GearPos_D_Actl 15;
BA_ "U_U55X_MY2022_Rx" SG_ 374 GearPos_D_Actl 1;
BA_ "GenSigStartValueInteger" SG_ 500 ChrgLocLattFrct_An_Sav 1048575;
BA_ "GenSigStartValue" SG_ 500 ChrgLocLattFrct_An_Sav 1048575;
BA_ "GenSigStartValueInteger" SG_ 500 ChrgLocLongFrct_An_Sav 1048575;
BA_ "GenSigStartValue" SG_ 500 ChrgLocLongFrct_An_Sav 1048575;
BA_ "GenSigStartValueInteger" SG_ 322 Inv1Ain_I_ActlMntr 32766;
BA_ "GenSigStartValue" SG_ 322 Inv1Ain_I_ActlMntr 32765;
BA_ "GenSigStartValueInteger" SG_ 322 VehElRnge_L_Dsply 4095;
BA_ "GenSigStartValue" SG_ 322 VehElRnge_L_Dsply 4093;
BA_ "GenSigStartValueInteger" SG_ 1087 DcacFaltMsgTxt_D2_Rq 1;
BA_ "U_U55X_MY2022_Rx" SG_ 1087 FapLcMaxGrdAbrt_B_Stat 1;
BA_ "U_U55X_MY2022_Rx" SG_ 1087 FapLcActv_B_Stat 1;
BA_ "U_U55X_MY2022_Rx" SG_ 1087 AdasLcObtclAbrt_B_Stat 1;
BA_ "U_U55X_MY2022_Rx" SG_ 341 TCU_ESN_D_Rq 1;
BA_ "U_CD764_MY2022_Rx" SG_ 341 TCU_ESN_D_Rq 1;
BA_ "U_CX727_MY2021_Rx" SG_ 341 FactoryReset_Rq 1;
BA_ "U_CD542_MY2021_Rx" SG_ 341 FactoryReset_Rq 1;
BA_ "U_U55X_MY2022_Rx" SG_ 341 FactoryReset_Rq 1;
BA_ "U_CD764_MY2022_Rx" SG_ 341 FactoryReset_Rq 1;
BA_ "U_CX727_MY2021_Rx" SG_ 341 ModemReset_D_Rq 1;
BA_ "U_CD542_MY2021_Rx" SG_ 341 ModemReset_D_Rq 1;
BA_ "U_U55X_MY2022_Rx" SG_ 341 ModemReset_D_Rq 1;
BA_ "U_CD764_MY2022_Rx" SG_ 341 ModemReset_D_Rq 1;
BA_ "GenSigStartValueInteger" SG_ 341 ChrgStatDsply_D_Rq 1;
BA_ "GenSigStartValue" SG_ 341 ChrgStatDsply_D_Rq 1;
BA_ "GenSigSendType" SG_ 651 TelematicsSrvc_D_St 3;
BA_ "U_CX727_MY2021_Tx" SG_ 651 TelematicsSrvc_D_St 1;
BA_ "U_P702_MY2021_Tx" SG_ 651 TelematicsSrvc_D_St 1;
BA_ "U_T6_MCA_MY2020_Tx" SG_ 651 TelematicsSrvc_D_St 1;
BA_ "U_CD542_MY2021_Tx" SG_ 651 TelematicsSrvc_D_St 1;
BA_ "U_CD764_MY2022_Tx" SG_ 651 TelematicsSrvc_D_St 1;
BA_ "GenSigSendType" SG_ 651 EmgcyCallMute_D_Stat 3;
BA_ "U_CX727_MY2021_Tx" SG_ 651 EmgcyCallMute_D_Stat 1;
BA_ "U_P702_MY2021_Tx" SG_ 651 EmgcyCallMute_D_Stat 1;
BA_ "U_T6_MCA_MY2020_Tx" SG_ 651 EmgcyCallMute_D_Stat 1;
BA_ "U_CD542_MY2021_Tx" SG_ 651 EmgcyCallMute_D_Stat 1;
BA_ "U_CD764_MY2022_Tx" SG_ 651 EmgcyCallMute_D_Stat 1;
BA_ "GenSigStartValueInteger" SG_ 516 EngAoutNActl_D_QF 1;
BA_ "MetaData" SG_ 516 EngAoutNActl_D_QF 1;
BA_ "GenSigStartValue" SG_ 516 EngAoutNActl_D_QF 1;
BA_ "ContentDependant" SG_ 516 EngAout3_N_Actl 1;
BA_ "U_U55X_MY2022_Rx" SG_ 516 ApedPos_Pc_ActlArb 1;
BA_ "GenSigStartValueInteger" SG_ 516 ApedPosPcActl_D_Qf 1;
BA_ "MetaData" SG_ 516 ApedPosPcActl_D_Qf 1;
BA_ "GenSigStartValue" SG_ 516 ApedPosPcActl_D_Qf 1;
BA_ "ContentDependant" SG_ 516 ApedPosPcActl_No_Cnt 1;
BA_ "MetaData" SG_ 516 ApedPosPcActl_No_Cnt 1;
BA_ "ContentDependant" SG_ 516 ApedPosPcActl_No_Cs 1;
BA_ "MetaData" SG_ 516 ApedPosPcActl_No_Cs 1;
BA_ "GenSigStartValueInteger" SG_ 531 VehStop_D_Stat 2;
BA_ "GenSigStartValue" SG_ 531 VehStop_D_Stat 2;
BA_ "U_U55X_MY2022_Rx" SG_ 531 TracCtlPtActv_B_Actl 1;
BA_ "U_U55X_MY2022_Rx" SG_ 531 StabCtlBrkActv_B_Actl 1;
BA_ "U_U55X_MY2022_Rx" SG_ 531 AbsActv_B_Actl 1;
BA_ "GenSigStartValueInteger" SG_ 531 VehLongOvrGnd_A_Est 511;
BA_ "WakeupSignal" SG_ 531 PrkBrkYwLamp_D_Rq 1;
BA_ "WakeupSignal" SG_ 531 PrkBrkRedLamp_D_Rq 1;
BA_ "WakeupSignal" SG_ 531 PrkBrkMsgTxt_D_Rq 1;
BA_ "GenSigStartValueInteger" SG_ 531 PrkBrkStatus 7;
BA_ "GenSigStartValue" SG_ 531 PrkBrkStatus 7;
BA_ "U_U55X_MY2022_Rx" SG_ 531 PrkBrkStatus 1;
BA_ "GenSigStartValueInteger" SG_ 1054 SelDrvMdeAwd_D_Rq 31;
BA_ "GenSigStartValue" SG_ 1054 SelDrvMdeAwd_D_Rq 31;
BA_ "ContentDependant" SG_ 1054 AutoHoldSwMde_B_Ind 1;
BA_ "WakeupSignal" SG_ 1054 BrkMdeInhbt_B_RqDsply 1;
BA_ "GenSigStartValueInteger" SG_ 1054 BrkLineLck_D_Stat 4;
BA_ "GenSigStartValue" SG_ 1054 BrkLineLck_D_Stat 4;
BA_ "U_U55X_MY2022_Rx" SG_ 1054 ApaBrk_D_Stat 1;
BA_ "GenSigStartValueInteger" SG_ 1200 HsaTrnAout_Tq_Rq 32768;
BA_ "GenSigStartValueInteger" SG_ 1200 BrkBstrVac_P_Actl 127;
BA_ "GenSigStartValue" SG_ 1200 BrkBstrVac_P_Actl 127;
BA_ "GenSigStartValueInteger" SG_ 1200 YawStabilityIndex 256;
BA_ "U_U55X_MY2022_Rx" SG_ 1200 BrkTot_Tq_RqDrv 1;
BA_ "MetaData" SG_ 1200 BrkTotTqRqDrv_No_Cnt 1;
BA_ "U_U55X_MY2022_Rx" SG_ 1200 BrkTotTqRqDrv_No_Cnt 1;
BA_ "MetaData" SG_ 1200 BrkTotTqRqDrv_No_Cs 1;
BA_ "U_U55X_MY2022_Rx" SG_ 1200 BrkTotTqRqDrv_No_Cs 1;
BA_ "U_U55X_MY2022_Rx" SG_ 1200 HsaStat_D_Dsply 1;
BA_ "U_U55X_MY2022_Rx" SG_ 1200 BrkHold_D_Stat 1;
BA_ "U_U55X_MY2022_Rx" SG_ 931 VehOnSrc_D_Stat 1;
BA_ "MetaData" SG_ 931 StrtrMtrCtlDStat_No_Cs 1;
BA_ "ContentDependant" SG_ 931 CrnkInhbt_No_Cs 1;
BA_ "MetaData" SG_ 931 CrnkInhbt_No_Cs 1;
BA_ "ContentDependant" SG_ 931 CrnkInhbt_No_Cnt 1;
BA_ "MetaData" SG_ 931 CrnkInhbt_No_Cnt 1;
BA_ "GenSigStartValueInteger" SG_ 931 CrnkInhbt_B_Stat 1;
BA_ "GenSigStartValue" SG_ 931 CrnkInhbt_B_Stat 1;
BA_ "U_U55X_MY2022_Rx" SG_ 1234 RmtCtlSnsBlckg_B_Stat 1;
BA_ "GenSigStartValue" SG_ 1234 RmtCtlConfgSrc_D_Stat 1;
BA_ "U_U55X_MY2022_Rx" SG_ 1234 RmtCtlConfgSrc_D_Stat 1;
BA_ "U_U55X_MY2022_Rx" SG_ 1234 RmtCtlTrjctry_D_Avail 1;
BA_ "U_U55X_MY2022_Rx" SG_ 1234 RmtCtlSns_D_Err 1;
BA_ "U_U55X_MY2022_Rx" SG_ 1234 RmtCtlPathPlan_D_Stat 1;
BA_ "U_U55X_MY2022_Rx" SG_ 1234 RmtCtlPathPlan_B_Err 1;
BA_ "U_U55X_MY2022_Rx" SG_ 1234 RmtCtlAdas_D_Stat 1;
BA_ "U_U55X_MY2022_Rx" SG_ 1234 RmtCtlAdas_B_Err 1;
BA_ "U_U55X_MY2022_Rx" SG_ 1233 FreeDrvRear_D_Avail 1;
BA_ "U_U55X_MY2022_Rx" SG_ 1233 FreeDrvFwd_D_Avail 1;
BA_ "U_U55X_MY2022_Rx" SG_ 1233 RmtCtlTrgDist_D_Stat 1;
BA_ "U_U55X_MY2022_Rx" SG_ 1233 RmtCtlSnsRrCrnr_D_Stat 1;
BA_ "U_U55X_MY2022_Rx" SG_ 1233 RmtCtlSnsRlCrnr_D_Stat 1;
BA_ "U_U55X_MY2022_Rx" SG_ 1233 RmtCtlSnsRear_D_Stat 1;
BA_ "U_U55X_MY2022_Rx" SG_ 1233 RmtCtlSnsFront_D_Stat 1;
BA_ "U_U55X_MY2022_Rx" SG_ 1233 RmtCtlSnsFrCrnr_D_Stat 1;
BA_ "U_U55X_MY2022_Rx" SG_ 1233 RmtCtlSnsFlCrnr_D_Stat 1;
BA_ "U_U55X_MY2022_Rx" SG_ 1233 RmtCtlSideSnsR4_D_Stat 1;
BA_ "U_U55X_MY2022_Rx" SG_ 1233 RmtCtlSideSnsR3_D_Stat 1;
BA_ "U_U55X_MY2022_Rx" SG_ 1233 RmtCtlSideSnsR2_D_Stat 1;
BA_ "U_U55X_MY2022_Rx" SG_ 1233 RmtCtlSideSnsR1_D_Stat 1;
BA_ "U_U55X_MY2022_Rx" SG_ 1233 RmtCtlSideSnsL4_D_Stat 1;
BA_ "U_U55X_MY2022_Rx" SG_ 1233 RmtCtlSideSnsL3_D_Stat 1;
BA_ "U_U55X_MY2022_Rx" SG_ 1233 RmtCtlSideSnsL2_D_Stat 1;
BA_ "U_U55X_MY2022_Rx" SG_ 1233 RmtCtlSideSnsL1_D_Stat 1;
BA_ "U_U55X_MY2022_Rx" SG_ 1233 RmtCtlRightOrnt_D_Avail 1;
BA_ "U_U55X_MY2022_Rx" SG_ 1233 RmtCtlRight_D_Avail 1;
BA_ "U_U55X_MY2022_Rx" SG_ 1233 RmtCtlRear_D_Avail 1;
BA_ "U_U55X_MY2022_Rx" SG_ 1233 RmtCtlPrkMde_D_Stat 1;
BA_ "U_U55X_MY2022_Rx" SG_ 1233 RmtCtlPrkInSlot_D_Stat 1;
BA_ "U_U55X_MY2022_Rx" SG_ 1233 RmtCtlObstcl_B_Stat 1;
BA_ "U_U55X_MY2022_Rx" SG_ 1233 RmtCtlNxtMoveDir_D_Stat 1;
BA_ "U_U55X_MY2022_Rx" SG_ 1233 RmtCtlMoveDir_D_Stat 1;
BA_ "U_U55X_MY2022_Rx" SG_ 1233 RmtCtlLeftOrnt_D_Avail 1;
BA_ "U_U55X_MY2022_Rx" SG_ 1233 RmtCtlLeft_D_Avail 1;
BA_ "U_U55X_MY2022_Rx" SG_ 1233 RmtCtlFront_D_Avail 1;
VAL_ 1044 ApaBrkErr_D_Stat 3 "Faulty" 2 "NoDataExists" 1 "Yes" 0 "No" ;
VAL_ 517 FapLc_B_Err 1 "Yes" 0 "No" ;
VAL_ 985 LongCtrlEnbl_D_Rq 7 "Faulty" 6 "NotUsed_3" 5 "NotUsed_2" 4 "NotUsed_1" 3 "RemoteParking" 2 "Autohitch" 1 "AutomaticParking" 0 "None" ;
VAL_ 942 ApaOffOptnSel_B_Avail 1 "Available" 0 "NotAvailable" ;
VAL_ 942 PrkBrkElRleas_B_RqApa 1 "Yes" 0 "No" ;
VAL_ 942 ApaDrvRq2MsgTxt_D_Rq 15 "NotUsed_7" 14 "NotUsed_6" 13 "NotUsed_5" 12 "NotUsed_4" 11 "NotUsed_3" 10 "NotUsed_2" 9 "NotUsed_1" 8 "CloseDoor" 7 "TakeControl" 6 "ReleaseEpb" 5 "ReleaseSteering" 4 "ReleaseBrake" 3 "DriveBackward" 2 "DriveForward" 1 "Stop" 0 "NoRequest" ;
VAL_ 942 ApaDrvRq1MsgTxt_D_Rq 7 "NotUsed" 6 "ExitVehicle" 5 "PressApaButton" 4 "ShiftToP" 3 "ShiftToN" 2 "ShiftToD" 1 "ShiftToR" 0 "NoRequest" ;
VAL_ 942 ApaSys_D2_Stat 15 "NotUsed_5" 14 "NotUsed_4" 13 "NotUsed_3" 12 "NotUsed_2" 11 "NotUsed_1" 10 "NoSideSelectable" 9 "RightSideSelectable" 8 "LeftSideSelectable" 7 "BothSidesSelectable" 6 "Faulty" 5 "Finished" 4 "Cancelled" 3 "NotAvailable" 2 "Overspeed" 1 "Pause" 0 "NormalOperation" ;
VAL_ 942 ApaSlotTrgt_D_Stat 15 "NotUsed_7" 14 "NotUsed_6" 13 "NotUsed_5" 12 "NotUsed_4" 11 "NotUsed_3" 10 "NotUsed_2" 9 "NotUsed_1" 8 "Front" 7 "Rear" 6 "Right3" 5 "Right2" 4 "Right1" 3 "Left3" 2 "Left2" 1 "Left1" 0 "None" ;
VAL_ 942 ApaSlotOption_B_Avail 1 "Available" 0 "NotAvailable" ;
VAL_ 942 ApaSlotAlrtSet_B_Stat 1 "Enable" 0 "Disable" ;
VAL_ 942 ApaSlotAlrt_B_Rq 1 "True" 0 "False" ;
VAL_ 942 ApaRmtFeatSel_B_Avail 1 "Available" 0 "NotAvailable" ;
VAL_ 942 ApaParkOutSel_B_Avail 1 "Available" 0 "NotAvailable" ;
VAL_ 942 ApaParkInSel_B_Avail 1 "Available" 0 "NotAvailable" ;
VAL_ 942 ApaMsgTxt_D2_Stat 15 "ReducedFunction" 14 "TrailerFeatureNotAvailable" 13 "AcceleratorPedalInactive" 12 "SensorsBlocked" 11 "TrailerAttached" 10 "TcsDeactivated" 9 "WheelSlip" 8 "HighInclination" 7 "DoorOpen" 6 "SteeringInteraction" 5 "WrongDirection" 4 "SpeedLimitExceeded" 3 "BrakeEvent" 2 "ObstacleInPath" 1 "WaitForSteering" 0 "None" ;
VAL_ 942 ApaDynmcSlot_B_Stat 1 "On" 0 "Off" ;
VAL_ 942 ApaDisplayMode_D_Stat 3 "NotUsed" 2 "FullScreen" 1 "Menu" 0 "Off" ;
VAL_ 942 ApaControlMode_D_Stat 1 "Active" 0 "Inactive" ;
VAL_ 942 PrkAidAcsyRear_D_Stat 3 "NotUsed" 2 "On" 1 "Off" 0 "Null" ;
VAL_ 942 PrkAidAcsyFront_D_Stat 3 "NotUsed" 2 "On" 1 "Off" 0 "Null" ;
VAL_ 942 PrkAidDrvDir_D_Stat 7 "NotUsed_2" 6 "NotUsed_1" 5 "BackwardNegative" 4 "ForwardNegative" 3 "BackwardPositive" 2 "ForwardPositive" 1 "NoMotion" 0 "DirectionNotKnown" ;
VAL_ 624 PaakAddErase_D_Rq 3 "EraseAll" 2 "Erase" 1 "Add" 0 "Null" ;
VAL_ 621 IgnPsswrdActv_B_Stat 1 "Active" 0 "Inactive" ;
VAL_ 621 FobTrgtZone_D_Rq 15 "NotUsed_9" 14 "NotUsed_8" 13 "NotUsed_7" 12 "NotUsed_6" 11 "NotUsed_5" 10 "NotUsed_4" 9 "NotUsed_3" 8 "NotUsed_2" 7 "NotUsed_1" 6 "Approach" 5 "RearInterior" 4 "RearExterior" 3 "Passenger" 2 "Driver" 1 "Interior" 0 "Null" ;
VAL_ 621 FobTrgtType_D_Rq 7 "NotUsed_4" 6 "NotUsed_3" 5 "NotUsed_2" 4 "NotUsed_1" 3 "Polling" 2 "Registry" 1 "Crypto" 0 "Null" ;
VAL_ 621 RmtCtlSelSlot_D_Rq 7 "NotUsed_3" 6 "NotUsed_2" 5 "NotUsed_1" 4 "Right" 3 "Left" 2 "Rear" 1 "Front" 0 "None" ;
VAL_ 621 RmtCtlSelPrkMde_D_Rq 3 "NotUsed" 2 "FreeDrive" 1 "ParkIn" 0 "None" ;
VAL_ 621 RmtCtlSelMoveDir_D_Rq 3 "NotUsed" 2 "Backward" 1 "Forward" 0 "None" ;
VAL_ 621 RmtCtlRjctAutoCfg_B_Rq 1 "Yes" 0 "No" ;
VAL_ 622 FobCtlType_D_Stat 3 "NotUsed" 2 "Valid" 1 "Invalid" 0 "Null" ;
VAL_ 932 RmtCtlBattMntr_B_Falt 1 "Yes" 0 "No" ;
VAL_ 932 VehStrtInhbt_D_Stat 1 "Inhibit" 0 "NoInhibit" ;
VAL_ 932 VehInhbtMde_D_Stat 7 "NotUsed_3" 6 "NotUsed_2" 5 "NotUsed_1" 4 "FullVehicleOta" 3 "Iviota" 2 "SyncOta" 1 "NoOtaSupport" 0 "Unconfigured" ;
VAL_ 932 VehOnSrc2_D_Stat 15 "NotUsed_11" 14 "NotUsed_10" 13 "NotUsed_9" 12 "NotUsed_8" 11 "NotUsed_7" 10 "NotUsed_6" 9 "EsclRssd" 8 "AutonomousVehicle" 7 "SecureIdle" 6 "FleetVehicleInhibit" 5 "StolenVehicleInhibit" 4 "OverTheAir" 3 "RemoteParkAssist" 2 "RemoteStart" 1 "Manual" 0 "Off" ;
VAL_ 932 VehOnCtl_D_Stat 3 "NotUsed" 2 "On" 1 "Off" 0 "Null" ;
VAL_ 118 BrkCtrFnd_B_Stat 1 "Yes" 0 "No" ;
VAL_ 118 BrkTerrMdeChng_D_Rdy 7 "Fault" 6 "Undefined_2" 5 "Undefined_1" 4 "ModeUnavailDrInputRqd" 3 "SpOpModes_NotSupported" 2 "ModeUnavailDynamicCond" 1 "Module_In_Initialization" 0 "Mode_Change_Available" ;
VAL_ 118 BrkTerrMde_D_Actl 7 "Fail_Safe_Default" 6 "Dynamic_Mode" 5 "Rock_Crawl_Mode" 4 "Mud_Ruts_Mode" 3 "Sand_Mode" 2 "Undefined" 1 "Low_Mu_Mode" 0 "Special_Operating_Mode_Off" ;
VAL_ 118 DrvSte_D_Stat 15 "NotUsed10" 14 "NotUsed9" 13 "NotUsed8" 12 "NotUsed7" 11 "NotUsed6" 10 "NotUsed5" 9 "NotUsed4" 8 "NotUsed3" 7 "NotUsed2" 6 "NotUsed1" 5 "Request_Active" 4 "Ignition_Off" 3 "DSR_in_Normal_Idle_Mode" 2 "EPAS_Comm_Disturbed" 1 "DSR_Request_Not_Applicable" 0 "DSR_Deactivated" ;
VAL_ 118 DrvSte_Tq_Rq 255 "Invalid" 254 "Unknown" ;
VAL_ 118 EmgcyBrkLamp_D_Rq 3 "NotUsed" 2 "Active_at_standstill" 1 "Active_at_speed" 0 "Inactive" ;
VAL_ 118 StopLamp_B_RqBrk 1 "Active" 0 "Inactive" ;
VAL_ 118 SteWhlCompAnEst_D_Qf 3 "OK" 2 "Not_Within_Specifications" 1 "No_Data_Exists" 0 "Faulty" ;
VAL_ 617 PaaKMyKeyChng_D_Stat 3 "NotUsed" 2 "ClearAll" 1 "MyKey" 0 "Null" ;
VAL_ 617 PaakAddErase_D_Stat 3 "EraseAll" 2 "Erase" 1 "Add" 0 "Null" ;
VAL_ 616 KeyPadCodeProg_D_Stat 7 "NotUsed_2" 6 "Duplicate" 5 "ProgrammingFailure" 4 "DeleteAll" 3 "Delete" 2 "Add" 1 "LearningMode" 0 "NormalMode" ;
VAL_ 616 PaakTrgtPreAuthrz_B_Rq 1 "Enable" 0 "Disable" ;
VAL_ 616 PaakTrgtType_D_Rq 7 "NotUsed_4" 6 "NotUsed_3" 5 "NotUsed_2" 4 "NotUsed_1" 3 "Polling" 2 "Registry" 1 "Crypto" 0 "Null" ;
VAL_ 616 PaakTrgtZone_D_Rq 15 "NotUsed_9" 14 "NotUsed_8" 13 "NotUsed_7" 12 "NotUsed_6" 11 "NotUsed_5" 10 "NotUsed_4" 9 "NotUsed_3" 8 "NotUsed_2" 7 "NotUsed_1" 6 "Approach" 5 "RearInterior" 4 "RearExterior" 3 "Passenger" 2 "Driver" 1 "Interior" 0 "Null" ;
VAL_ 616 PaakTrgtData_D_Rq 5 "NotUsed_2" 4 "Not_Used1" 3 "Target1_IdBlock2" 2 "Target1_IdBlock1" 1 "Challenge" 0 "Idle" 7 "NotUsed_4" 6 "NotUsed_3" ;
VAL_ 619 KeyPadCodeProg_D_Rq 7 "NotUsed_3" 6 "NotUsed_2" 5 "NotUsed_1" 4 "DeleteAll" 3 "Delete" 2 "Add" 1 "ProgrammingMode" 0 "Null" ;
VAL_ 619 PaakCnnct_D_Stat 3 "NotUsed" 2 "Connected" 1 "NotConnected" 0 "Null" ;
VAL_ 619 PaakCtlActv_D_Rq 31 "NotUsed_13" 30 "NotUsed_12" 29 "NotUsed_11" 28 "NotUsed_10" 27 "NotUsed_9" 26 "NotUsed_8" 25 "NotUsed_7" 24 "NotUsed_6" 23 "NotUsed_5" 22 "NotUsed_4" 21 "NotUsed_3" 20 "TrunkFrontRelease" 19 "RemoteStop" 18 "RemoteStart" 17 "PowerDecklid" 16 "RightPowerSlidingDoor" 15 "LeftPowerSlidingDoor" 14 "PowerLiftgate" 13 "GlobalClose" 12 "GlobalOpen" 11 "PanicOff" 10 "PanicOn" 9 "LiftgateGlassRelease" 8 "LiftgateRelease" 7 "DecklidRelease" 6 "DoubleLock" 5 "LockAll" 4 "UnlockAllDoorsPlusCargo" 3 "UnlockCargoDoor" 2 "UnlockAllDoors" 1 "UnlockDriverDoor" 0 "Null" ;
VAL_ 618 IgnPsswrdSetup_B_Rq 1 "Active" 0 "Inactive" ;
VAL_ 618 IgnPsswrdLckout_B_Stat 1 "Active" 0 "Inactive" ;
VAL_ 618 PaakLoclzd_D_Stat 15 "NotUsed_12" 14 "NotUsed_11" 13 "NotUsed_10" 12 "NotUsed_9" 11 "NotUsed_8" 10 "NotUsed_7" 9 "NotUsed_6" 8 "NotUsed_5" 7 "NotUsed_4" 6 "NotUsed_3" 5 "NotUsed_2" 4 "NotUsed_1" 3 "FullLoc" 2 "PausedLoc" 1 "MaintainLink" 0 "BackgroundScan" ;
VAL_ 618 PaakCtlType_D_Stat 3 "NotUsed" 2 "Valid" 1 "Invalid" 0 "Null" ;
VAL_ 618 PaakCtlData_D_Stat 7 "NotUsed_3" 6 "NotUsed_2" 5 "NotUsed_1" 4 "Response" 3 "EchoTargetIdBlock1" 2 "RequestTargetIdBlock2" 1 "RequestTargetIdBlock1" 0 "Idle" ;
VAL_ 357 BPedDrvAppl_D_QF 3 "OK" 2 "Not_Within_Specifications" 1 "No_Data_Exists" 0 "Faulty" ;
VAL_ 357 CmbbDeny_B_ActlPrpl 1 "Yes" 0 "No" ;
VAL_ 357 PrplTqMnSat_B_Actl 1 "Yes" 0 "No" ;
VAL_ 357 VehStrtStop_D_Rq 3 "NotUsed" 2 "Vehicle_Start_Request" 1 "Vehicle_Stop_Request" 0 "NoRequest" ;
VAL_ 357 BpedDrvAppl_D_Actl 3 "_Not_Allowed" 2 "Driver_Braking" 1 "Driver_Not_Braking" 0 "Not_Allowed" ;
VAL_ 357 CmbbEngTqMn_B_Actl 1 "Yes" 0 "No" ;
VAL_ 357 Veh_V_DsplyCcSet 255 "Fault" 254 "Unknown" ;
VAL_ 357 AccEngStat_D_Actl 7 "Undefined_2" 6 "Undefined_1" 5 "ACCSoonCancel_due_Low_Spd" 4 "Shift_Down_Recommendation" 3 "Shift_Up_Recommendation" 2 "ACCNotAllowedToBeActivated" 1 "ACCStandby_due_Auto_Cancel" 0 "Normal_Operation" ;
VAL_ 357 CcMde_D_Actl 7 "TapDownWaiting" 6 "TapUpWaiting" 5 "Resuming_Low" 4 "Resuming_High" 3 "Decelerating" 2 "Accelerating" 1 "Keeping_Speed" 0 "Not_Active" ;
VAL_ 357 CcStat_D_Actl 7 "Undefined_2" 6 "Undefined_1" 5 "Active" 4 "Active_Que_Assist" 3 "Standby" 2 "Standby_Denied" 1 "Denied" 0 "Off" ;
VAL_ 357 CcOvrrdActv_B_Actl 1 "Cruise_Overridden" 0 "Cruise_Req_Not_Overridden" ;
VAL_ 357 AccStopMde_D_Rq 3 "Stop_Mode_Active" 2 "EPBApplyOrBrakeReleaseWarn" 1 "Limit_Rolling_Speed" 0 "Stop_Mode_Not_Active" ;
VAL_ 374 GearEngag_D_Actl 7 "Undefined" 6 "Fwd_Clutch_Fully_Engaged" 5 "Neutral_Idle" 4 "Disengaged_to_Neutral_Idle" 3 "Disengaged_to_Neutral_Park" 2 "Engagement_in_Progress" 1 "InitializeFwdClutchEngagmt" 0 "Park_Neutral" ;
VAL_ 374 TrnRng_D_Rq 15 "Fault" 14 "Unknown_Position" 13 "NotUsed_2" 12 "NotUsed_1" 11 "Range6" 10 "Range5" 9 "Range4" 8 "Range3_M3_L3" 7 "Range2_M2_L2" 6 "Range1_M1_L1" 5 "Low" 4 "Sport_DriveSport_Mposition" 3 "Drive" 2 "Neutral" 1 "Reverse" 0 "Park" ;
VAL_ 374 TrnPrkSys_D_Actl 15 "Faulty" 14 "NotUsed_5" 13 "NotUsed_4" 12 "NotUsed_3" 11 "NotUsed_2" 10 "NotUsed_1" 9 "FrequencyError" 8 "OutOfRangeHigh" 7 "OutOfRangeLow" 6 "Override" 5 "OutOfPark" 4 "TransitionCloseToOutOfPark" 3 "AtNoSpring" 2 "TransitionCloseToPark" 1 "Park" 0 "NotKnown" ;
VAL_ 374 GearLvr_D_ActlDrv 15 "Fault" 14 "Unknown_Position" 13 "NotUsed_2" 12 "NotUsed_1" 11 "Range6" 10 "Range5" 9 "Range4" 8 "Range3_M3_L3" 7 "Range2_M2_L2" 6 "Range1_M1_L1" 5 "Low" 4 "Sport_DriveSport_Mposition" 3 "Drive" 2 "Neutral" 1 "Reverse" 0 "Park" ;
VAL_ 374 GearPos_D_Trg 15 "Unknown" 14 "Reverse" 13 "Undefined_5" 12 "Undefined_4" 11 "Undefined_3" 10 "Tenth" 9 "Ninth" 8 "Eighth" 7 "Seventh" 6 "Sixth" 5 "Fifth" 4 "Fourth" 3 "Third" 2 "Second" 1 "First" 0 "Neutral" ;
VAL_ 374 GearPos_D_Actl 15 "Unknown" 14 "Reverse" 13 "Undefined_5" 12 "Undefined_4" 11 "Undefined_3" 10 "Tenth" 9 "Ninth" 8 "Eighth" 7 "Seventh" 6 "Sixth" 5 "Fifth" 4 "Fourth" 3 "Third" 2 "Second" 1 "First" 0 "Neutral" ;
VAL_ 500 ChrgLocSaved_B_Dsply 1 "Yes" 0 "No" ;
VAL_ 500 AirCondRec_B_RqVehEl 1 "Yes" 0 "No" ;
VAL_ 500 ChrgNowCurnt_B_Dsply 1 "On" 0 "Off" ;
VAL_ 500 ChrgLocLongPostv_B_Sav 1 "Yes" 0 "No" ;
VAL_ 500 ChrgLocLattPostv_B_Sav 1 "Yes" 0 "No" ;
VAL_ 322 Mtr2State_D_ActlMntr 7 "Faulty" 6 "NoDataExists" 5 "NotUsed_1" 4 "ReadinessState" 3 "DeactivationState" 2 "PowerGeneration" 1 "PowerConsumption" 0 "Null" ;
VAL_ 322 Inv1Ain_I_ActlMntr 32767 "Faulty" 32766 "NoDataExists" ;
VAL_ 322 HybVehMde_D_ActlMntr 7 "Faulty" 6 "NoDataExists" 5 "NotUsed_2" 4 "NotUsed_1" 3 "Fuel" 2 "HybridElectric" 1 "AllElectric" 0 "Null" ;
VAL_ 322 ChrgStat_D_ActlMntr 7 "Faulty" 6 "NoDataExists" 5 "NotUsed" 4 "ChargingCompleted" 3 "NotCharging" 2 "ChargingInDrivingState" 1 "ChargingInParkingState" 0 "Null" ;
VAL_ 322 VehElRnge_L_Dsply 4094 "NoDataExists" 4095 "Fault" ;
VAL_ 1087 DcacFaltMsgTxt_D2_Rq 63 "NotUsed_47" 17 "NotUsed_1" 16 "HevDerate" 15 "HvacOn" 14 "OvercurrentLP" 13 "EngineRun" 12 "Service" 11 "NotAvailable" 10 "PlugWarn" 9 "PlugWarnDrive" 8 "BreakerC" 7 "BreakerB" 6 "BreakerA" 5 "FuelLow" 4 "AcOnOutput" 3 "Temperature" 2 "Gfci" 1 "Overcurrent" 0 "Ok" ;
VAL_ 1087 SelDrvMdeCstmPt_D_Stat 31 "Faulty" 30 "NotUsed15" 29 "NotUsed14" 28 "NotUsed13" 27 "NotUsed12" 26 "NotUsed11" 25 "NotUsed10" 24 "NotUsed9" 23 "NotUsed8" 22 "NotUsed7" 21 "CustomMode" 20 "TrackMode" 19 "OnePedalDrive" 18 "EvLaterChargerMode" 17 "EvNowMode" 16 "DragMode" 15 "HighSpeedDesertMode_Baja" 14 "SportAdaptiveMode" 13 "NotAvailable_13" 12 "NotAvailable_12" 11 "NotAvailable_11" 10 "NotAvailable_10" 9 "RockCrawlMode" 8 "MudRutsMode" 7 "SandMode" 6 "EconomyMode" 5 "GrassGravelSnow" 4 "NotAvailable_04" 3 "TowHaulMode" 2 "NotAvailable_02" 1 "SportMode" 0 "NormalMode" ;
VAL_ 1087 RepaLcGrdInhbt_B_Stat 1 "Yes" 0 "No" ;
VAL_ 1087 ClimtCool_D_RqPt 3 "NotUsed_2" 2 "NotUsed_1" 1 "On" 0 "Off" ;
VAL_ 1087 BtsiShifInhbt_B_RqPt 1 "Yes" 0 "No" ;
VAL_ 1087 StrtInGearMsgTxt_D_Rq 15 "Message15" 14 "Message14" 13 "Message13" 12 "Message12" 11 "Message11" 10 "Message10" 9 "Message9" 8 "Message8" 7 "Message7" 6 "Message6" 5 "Message5" 4 "Message4" 3 "Message3" 2 "Message2" 1 "Message1" 0 "NoMessage" ;
VAL_ 1087 IgnOffInhbt_B_Stat 1 "Yes" 0 "No" ;
VAL_ 1087 FapLcInhbt_B_Rq 1 "Yes" 0 "No" ;
VAL_ 1087 FapLcStopHold_B_Rq 1 "Yes" 0 "No" ;
VAL_ 1087 FapLcPrchgBrk_B_Rq 1 "Yes" 0 "No" ;
VAL_ 1087 FapLcObstcl_B_Stat 1 "Yes" 0 "No" ;
VAL_ 1087 FapLcMaxGrdInhbt_B_Stat 1 "Yes" 0 "No" ;
VAL_ 1087 FapLcMaxGrdAbrt_B_Stat 1 "Yes" 0 "No" ;
VAL_ 1087 FapLcActv_B_Stat 1 "Yes" 0 "No" ;
VAL_ 1087 BattRgenLoDChrg_D_RqEng 3 "Disable" 2 "Retain" 1 "Closed" 0 "Open" ;
VAL_ 1087 BattRgenLoChrg_D_RqEng 3 "Disable" 2 "Retain" 1 "Closed" 0 "Open" ;
VAL_ 1087 AdasLcObtclAbrt_B_Stat 1 "Yes" 0 "No" ;
VAL_ 1087 AirDamPos_D_Stat 3 "Faulty" 2 "NotUsed" 1 "Down" 0 "Up" ;
VAL_ 1087 StopStrtCstm_D_Stat 3 "Faulty" 2 "On" 1 "Off" 0 "NotAvailable" ;
VAL_ 341 NextUsageTimeToggle_Rq 0 "Inactive" 2 "Disable" 1 "Enable" ;
VAL_ 341 LongTermParking_Rq 2 "On" 1 "Off" 0 "Inactive" ;
VAL_ 341 TCU_ESN_D_Rq 3 "NotUsed" 2 "TCU_ESN_Request" 1 "NoRequest" 0 "Inactive" ;
VAL_ 341 FactoryReset_Rq 1 "ResetFactoryDefaults" 0 "Inactive" ;
VAL_ 341 ModemReset_D_Rq 15 "NotUsed_11" 14 "NotUsed_10" 13 "NotUsed_9" 12 "NotUsed_8" 11 "NotUsed_7" 10 "NotUsed_6" 9 "NotUsed_5" 8 "NotUsed_4" 7 "NotUsed_3" 6 "BrandConnectReset2" 5 "BrandConnectReset1" 4 "CcsReset" 3 "OnlineTrafficReset" 2 "PaakReset" 1 "WifiHotspotReset" 0 "Null" ;
VAL_ 341 StopStrtDrvMde_B_RqBtn3 1 "Pressed" 0 "Not_Pressed" ;
VAL_ 341 ChrgStatDsply_D_Rq 3 "NotUsed_2" 2 "NotUsed_1" 1 "On" 0 "Off" ;
VAL_ 651 TelematicsSrvc_D_St 7 "NotUsed" 6 "NotifyNotActivatedYet" 5 "NotActivatedYet" 4 "NotifyExpired" 3 "Expired" 2 "ExpiringSoon" 1 "Active" 0 "Null" ;
VAL_ 651 EmgcyCallMute_D_Stat 7 "NotUsed4" 6 "NotUsed3" 5 "NotUsed2" 4 "NotUsed1" 3 "ManualEmergencyCallMute" 2 "AutomaticEmergencyCallMute" 1 "EmergencyCallUnmute" 0 "Null" ;
VAL_ 516 EngAoutNActl_D_QF 3 "OK" 2 "Not_Within_Specifications" 1 "No_Data_Exists" 0 "Faulty" ;
VAL_ 516 EngAout3_N_Actl 65535 "Invalid" ;
VAL_ 516 ApedPos_PcRate_ActlArb 255 "Fault" 254 "Unknown" ;
VAL_ 516 ApedPosPcActl_D_Qf 3 "OK" 2 "Not_Within_Specifications" 1 "No_Data_Exists" 0 "Faulty" ;
VAL_ 531 VehStop_D_Stat 3 "Faulty" 2 "NoDataExists" 1 "Yes" 0 "No" ;
VAL_ 531 TracCtlPtActv_B_Actl 1 "Active" 0 "Inactive" ;
VAL_ 531 LscmbbMntr_B_Err 1 "DisplayMessage" 0 "NoMessage" ;
VAL_ 531 LscmbbBrkDis_B_Actl 1 "Yes" 0 "No" ;
VAL_ 531 StabCtlBrkActv_B_Actl 1 "Yes" 0 "No" ;
VAL_ 531 CmbbBrkPrchg_B_Actl 1 "Yes" 0 "No" ;
VAL_ 531 CmbbBrkDecel_B_Actl 1 "Yes" 0 "No" ;
VAL_ 531 CmbbBaSensInc_B_Actl 1 "Yes" 0 "No" ;
VAL_ 531 AccBrkWarm_B_Actl 1 "Yes" 0 "No" ;
VAL_ 531 AccBrkTotTqMn_B_Actl 1 "Yes" 0 "No" ;
VAL_ 531 AccBrkPrchgActv_B_Actl 1 "Yes" 0 "No" ;
VAL_ 531 AccBrkDis_B_Actl 1 "Yes" 0 "No" ;
VAL_ 531 AccBrkDeny_B_Actl 1 "Yes" 0 "No" ;
VAL_ 531 AccBrkActv_B_Actl 1 "Yes" 0 "No" ;
VAL_ 531 PrplDrgCtlActv_B_Actl 1 "Active" 0 "Inactive" ;
VAL_ 531 AbsActv_B_Actl 1 "Yes" 0 "No" ;
VAL_ 531 CmbbBrkDis_B_Actl 1 "Yes" 0 "No" ;
VAL_ 531 CmbbDeny_B_ActlBrk 1 "Yes" 0 "No" ;
VAL_ 531 CcDis_B_Cmd 1 "Yes" 0 "No" ;
VAL_ 531 VehLongOvrGnd_A_Est 1023 "Fault" 1022 "Unknown" ;
VAL_ 531 AccStopActv_B_ActlBrk 1 "Yes" 0 "No" ;
VAL_ 531 AccDis_B_ActlEpb 1 "Yes" 0 "No" ;
VAL_ 531 PrkBrkYwLamp_D_Rq 3 "Fast_Flash" 2 "Slow_Flash" 1 "On" 0 "Off" ;
VAL_ 531 PrkBrkRedLamp_D_Rq 3 "Fast_Flash" 2 "Slow_Flash" 1 "On" 0 "Off" ;
VAL_ 531 PrkBrkMsgTxt_D_Rq 15 "Message15" 14 "Message14" 13 "Message13" 12 "Message12" 11 "Message11" 10 "Message10" 9 "Message9" 8 "Message8" 7 "Message7" 6 "Message6" 5 "Message5" 4 "Message4" 3 "Message3" 2 "Message2" 1 "Message1" 0 "No_Message" ;
VAL_ 531 PrkBrkStatus 7 "GeneralFault_MaintenceMode" 6 "ECD_by_Brake_ECU_Active" 5 "EPB_Limphome_Active" 4 "Rear_Caliper_Open" 3 "RWU_By_EPB_Active" 2 "Rear_Caliper_Transition" 1 "Rear_Caliper_Closed" 0 "Not_Supported" ;
VAL_ 531 VehicleStationary 1 "Yes" 0 "No" ;
VAL_ 531 LscmbbDeny_B_ActlBrk 1 "Yes" 0 "No" ;
VAL_ 531 LscmbbBrkDecel_B_Actl 1 "Yes" 0 "No" ;
VAL_ 531 LscmbbBaSensInc_B_Actl 1 "Yes" 0 "No" ;
VAL_ 531 LscmbBrkPrchg_B_Actl 1 "Active" 0 "Inactive" ;
VAL_ 1054 RbaBrk_D_Stat 3 "Denied" 2 "Active" 1 "Open" 0 "Closed" ;
VAL_ 1054 SelDrvMdeChassis2_D_Rq 31 "Faulty" 30 "NotUsed17" 29 "NotUsed16" 28 "NotUsed15" 27 "NotUsed14" 26 "NotUsed13" 25 "NotUsed12" 24 "NotUsed11" 23 "NotUsed10" 22 "NotUsed9" 21 "NotUsed8" 20 "NotUsed7" 19 "NotUsed6" 18 "NotUsed5" 17 "NotUsed4" 16 "OnePedalDrive" 15 "DragMode" 14 "RoughRoadMode" 13 "TrackMode" 12 "HighSpeedDesertMode" 11 "TowHaulMode" 10 "RockCrawlMode" 9 "SandMode" 8 "MudAndRutsMode" 7 "LowMuMode" 6 "ComfortAdaptiveMode" 5 "ComfortMode" 4 "SportAdaptiveMode" 3 "SportMode" 2 "EconomyMode" 1 "NormalAdaptiveMode" 0 "NormalMode" ;
VAL_ 1054 BrkBstrLoLampOn_B_Rq 1 "On" 0 "Off" ;
VAL_ 1054 TrailCtl_D_Stat 7 "Faulty" 6 "DescentOnly" 5 "EnabledDeny" 4 "StandbyOverThreshold" 3 "StandbyOverride" 2 "Active" 1 "EnabledDescent" 0 "Off" ;
VAL_ 1054 TrailCtlMsgTxt_D_Rq 15 "Message15" 14 "Message14" 13 "Message13" 12 "Message12" 11 "Message11" 10 "Message10" 9 "Message9" 8 "Message8" 7 "Message7" 6 "Message6" 5 "Message5" 4 "Message4" 3 "Message3" 2 "Message2" 1 "Message1" 0 "NoMessage" ;
VAL_ 1054 BrkPadMsgTxt_D_Rq 3 "Faulty" 2 "PadsOk" 1 "ReplacePads" 0 "Null" ;
VAL_ 1054 BrkBstrVac_D_Stat 3 "NotUsed" 2 "BoosterVacEstimator" 1 "BoosterVacSensor" 0 "NoBoosterVacuumMonitor" ;
VAL_ 1054 DrvSlipCtlOffLamp_D_Rq 3 "Fast_Flash" 2 "Slow_Flash" 1 "On" 0 "Off" ;
VAL_ 1054 DrvSlipCtlMdeMsg_D_Rq 31 "Message31" 30 "Message30" 29 "Message29" 28 "Message28" 27 "Message27" 26 "Message26" 25 "Message25" 24 "Message24" 23 "Message23" 22 "Message22" 21 "Message21" 20 "Message20" 19 "Message19" 18 "Message18" 17 "Message17" 16 "Message16" 15 "Message15" 14 "Message14" 13 "Message13" 12 "Message12" 11 "Message11" 10 "Message10" 9 "Message9" 8 "Message8" 7 "Message7" 6 "Message6" 5 "Message5" 4 "Message4" 3 "Message3" 2 "Message2" 1 "Message1" 0 "NoMessage" ;
VAL_ 1054 HdcOn_B_Ind 1 "On" 0 "Off" ;
VAL_ 1054 AutoHoldMsgTxt_D_Rq 15 "Message15" 14 "Message14" 13 "Message13" 12 "Message12" 11 "Message11" 10 "Message10" 9 "Message9" 8 "Message8" 7 "Message7" 6 "Message6" 5 "Message5" 4 "Message4" 3 "Message3" 2 "Message2" 1 "Message1" 0 "NoMessage" ;
VAL_ 1054 CtaBrk_D_Stat 3 "Denied" 2 "Active" 1 "Open" 0 "Closed" ;
VAL_ 1054 SelDrvMdeAwd_D_Rq 31 "Faulty" 30 "NotUsed_17" 29 "NotUsed_16" 28 "NotUsed_15" 27 "NotUsed_14" 26 "NotUsed_13" 25 "NotUsed_12" 24 "NotUsed_11" 23 "NotUsed_10" 22 "NotUsed_9" 21 "NotUsed_8" 20 "CustomMode" 19 "OnePedalDrive" 18 "DragMode" 17 "EvLaterChargeMode" 16 "EvNowMode" 15 "TrackMode" 14 "RoughRoadMode" 13 "NotAvailable" 12 "HighSpeedDesertMode_Baja" 11 "SportAdaptiveMode" 10 "RockCrawlMode" 9 "MudRutsMode" 8 "SandMode" 7 "EconomyMode" 6 "GrassGravelSnow" 5 "TowHaulMode" 4 "SportMode" 3 "Normal_4L" 2 "Normal_4A" 1 "Normal_2H" 0 "NormalMode" ;
VAL_ 1054 AutoHoldSwMde_B_Ind 1 "On" 0 "Off" ;
VAL_ 1054 AutoHoldMde_D_Ind 3 "Indication_3" 2 "Indication_2" 1 "Indication_1" 0 "Off" ;
VAL_ 1054 BrkMdeInhbt_B_RqDsply 1 "Yes" 0 "No" ;
VAL_ 1054 BrkLineLck_D_Stat 7 "NotUsed_3" 6 "NotUsed_2" 5 "NotUsed_1" 4 "NotAvailable" 3 "Off" 2 "Engaged" 1 "Initiated" 0 "Available" ;
VAL_ 1054 SelDrvMdeChassis_D_Rq 31 "Faulty" 30 "NotUsed17" 29 "NotUsed16" 28 "NotUsed15" 27 "NotUsed14" 26 "NotUsed13" 25 "NotUsed12" 24 "NotUsed11" 23 "NotUsed10" 22 "NotUsed9" 21 "NotUsed8" 20 "NotUsed7" 19 "NotUsed6" 18 "NotUsed5" 17 "NotUsed4" 16 "OnePedalDrive" 15 "DragMode" 14 "RoughRoadMode" 13 "TrackMode" 12 "HighSpeedDesertMode" 11 "TowHaulMode" 10 "RockCrawlMode" 9 "SandMode" 8 "MudAndRutsMode" 7 "LowMuMode" 6 "ComfortAdaptiveMode" 5 "ComfortMode" 4 "SportAdaptiveMode" 3 "SportMode" 2 "EconomyMode" 1 "NormalAdaptiveMode" 0 "NormalMode" ;
VAL_ 1054 ApaBrk_D_Stat 3 "Denied" 2 "Active" 1 "Open" 0 "Closed" ;
VAL_ 1054 SelDrvMdeChassis3_D_Rq 31 "Faulty" 30 "NotUsed17" 29 "NotUsed16" 28 "NotUsed15" 27 "NotUsed14" 26 "NotUsed13" 25 "NotUsed12" 24 "NotUsed11" 23 "NotUsed10" 22 "NotUsed9" 21 "NotUsed8" 20 "NotUsed7" 19 "NotUsed6" 18 "NotUsed5" 17 "NotUsed4" 16 "OnePedalDrive" 15 "DragMode" 14 "RoughRoadMode" 13 "TrackMode" 12 "HighSpeedDesertMode" 11 "TowHaulMode" 10 "RockCrawlMode" 9 "SandMode" 8 "MudAndRutsMode" 7 "LowMuMode" 6 "ComfortAdaptiveMode" 5 "ComfortMode" 4 "SportAdaptiveMode" 3 "SportMode" 2 "EconomyMode" 1 "NormalAdaptiveMode" 0 "NormalMode" ;
VAL_ 1054 TrailOnePdlTqLm_B_Actl 1 "Yes" 0 "No" ;
VAL_ 1054 OnePdlDrvDeny_B_Stat 1 "Yes" 0 "No" ;
VAL_ 1054 BrkDrvMde_D_Stat 7 "Faulty" 6 "RockCrawl" 5 "Baja" 4 "DragOrMudAndSand" 3 "Track" 2 "Snow_Wet" 1 "Sport" 0 "Normal" ;
VAL_ 1054 AirDamUp_B_RqBrk 1 "Up" 0 "NoRequest" ;
VAL_ 1054 FrontDiffElckrOpen_B_Rq 1 "Yes" 0 "No" ;
VAL_ 1200 BrkRearPCorrltn_B_Stat 1 "Yes" 0 "No" ;
VAL_ 1200 HsaTrnAout_Tq_Rq 65535 "Fault" 65534 "Unknown" ;
VAL_ 1200 BrkBstrVac_P_Actl 127 "Invalid" ;
VAL_ 1200 YawStabilityIndex 511 "Fault" 510 "NoDataExists" ;
VAL_ 1200 BrkTot_Tq_RqDrv 8191 "Fault" ;
VAL_ 1200 HsaStat_D_Dsply 7 "NotUsed3" 6 "NotUsed2" 5 "NotUsed1" 4 "NotAvailable" 3 "SlowReleaseWithChime" 2 "SlowReleaseWithoutChime" 1 "Active" 0 "Inactive" ;
VAL_ 1200 BrkHold_D_Stat 7 "NotUsed_3" 6 "NotUsed_2" 5 "NotUsed_1" 4 "HeldSecondary" 3 "HeldSecure" 2 "Held" 1 "Inactive" 0 "Off" ;
VAL_ 931 VehOnSrc_D_Stat 15 "NotUsed_11" 14 "NotUsed_10" 13 "NotUsed_9" 12 "NotUsed_8" 11 "NotUsed_7" 10 "NotUsed_6" 9 "EsclRssd" 8 "AutonomousVehicle" 7 "SecureIdle" 6 "FleetVehicleInhibit" 5 "StolenVehicleInhibit" 4 "OverTheAir" 3 "RemoteParkAssist" 2 "RemoteStart" 1 "Manual" 0 "Off" ;
VAL_ 931 EngStrtActv_B_Stat 1 "Active" 0 "Inactive" ;
VAL_ 931 EngStrt_B_Rq 1 "Request" 0 "NoRequest" ;
VAL_ 931 DrvInCtl_B_Stat 1 "Yes" 0 "No" ;
VAL_ 931 PtWakeReas_D_Stat 15 "NotUsed_9" 14 "NotUsed_8" 13 "NotUsed_7" 12 "NotUsed_6" 11 "NotUsed_5" 10 "NotUsed_4" 9 "NotUsed_3" 8 "NotUsed_2" 7 "NotUsed_1" 6 "ElapsedTime" 5 "ThirdPartyWakeup" 4 "DoorAjar" 3 "EarlyWake" 2 "NonMotiveStart" 1 "MotiveStart" 0 "Null" ;
VAL_ 931 CrnkInhbt_B_Stat 1 "Inhibit" 0 "NoInhibit" ;
VAL_ 931 IgnPreOffActv_B_Stat 1 "Active" 0 "Inactive" ;
VAL_ 1234 RmtCtlSnsBlckg_B_Stat 1 "Yes" 0 "No" ;
VAL_ 1234 RmtCtlConfgSrc_D_Stat 7 "NotUsed_2" 6 "NotUsed_1" 5 "BPO" 4 "ApaHmi" 3 "FAP_Handover" 2 "User" 1 "None" 0 "NotDetermined" ;
VAL_ 1234 RmtCtlTrjctry_D_Avail 3 "NotUsed" 2 "Available" 1 "NotAvailable" 0 "Null" ;
VAL_ 1234 RmtCtlSns_D_Err 1 "Yes" 0 "No" ;
VAL_ 1234 RmtCtlPathPlan_D_Stat 7 "NotUsed_3" 6 "NotUsed_2" 5 "NotUsed_1" 4 "FinishedMovesExceeded" 3 "FinishedDistanceExceeded" 2 "Finished" 1 "Ongoing" 0 "None" ;
VAL_ 1234 RmtCtlPathPlan_B_Err 1 "Yes" 0 "No" ;
VAL_ 1234 RmtCtlAdas_D_Stat 7 "Paused" 6 "Abort" 5 "ManeuverFinished" 4 "EndPositionReached" 3 "Backward" 2 "Forward" 1 "ManeuverBegin" 0 "Inactive" ;
VAL_ 1234 RmtCtlAdas_B_Err 1 "Yes" 0 "No" ;
VAL_ 1233 FreeDrvRear_D_Avail 3 "NotUsed" 2 "Available" 1 "NotAvailable" 0 "Null" ;
VAL_ 1233 FreeDrvFwd_D_Avail 3 "NotUsed" 2 "Available" 1 "NotAvailable" 0 "Null" ;
VAL_ 1233 RmtCtlSnsRrCrnr_D_Stat 3 "Zone3" 2 "Zone2" 1 "Zone1" 0 "Off" ;
VAL_ 1233 RmtCtlSnsRlCrnr_D_Stat 3 "Zone3" 2 "Zone2" 1 "Zone1" 0 "Off" ;
VAL_ 1233 RmtCtlSnsRear_D_Stat 3 "Zone3" 2 "Zone2" 1 "Zone1" 0 "Off" ;
VAL_ 1233 RmtCtlSnsFront_D_Stat 3 "Zone3" 2 "Zone2" 1 "Zone1" 0 "Off" ;
VAL_ 1233 RmtCtlSnsFrCrnr_D_Stat 3 "Zone3" 2 "Zone2" 1 "Zone1" 0 "Off" ;
VAL_ 1233 RmtCtlSnsFlCrnr_D_Stat 3 "Zone3" 2 "Zone2" 1 "Zone1" 0 "Off" ;
VAL_ 1233 RmtCtlSideSnsR4_D_Stat 3 "Zone3" 2 "Zone2" 1 "Zone1" 0 "Off" ;
VAL_ 1233 RmtCtlSideSnsR3_D_Stat 3 "Zone3" 2 "Zone2" 1 "Zone1" 0 "Off" ;
VAL_ 1233 RmtCtlSideSnsR2_D_Stat 3 "Zone3" 2 "Zone2" 1 "Zone1" 0 "Off" ;
VAL_ 1233 RmtCtlSideSnsR1_D_Stat 3 "Zone3" 2 "Zone2" 1 "Zone1" 0 "Off" ;
VAL_ 1233 RmtCtlSideSnsL4_D_Stat 3 "Zone3" 2 "Zone2" 1 "Zone1" 0 "Off" ;
VAL_ 1233 RmtCtlSideSnsL3_D_Stat 3 "Zone3" 2 "Zone2" 1 "Zone1" 0 "Off" ;
VAL_ 1233 RmtCtlSideSnsL2_D_Stat 3 "Zone3" 2 "Zone2" 1 "Zone1" 0 "Off" ;
VAL_ 1233 RmtCtlSideSnsL1_D_Stat 3 "Zone3" 2 "Zone2" 1 "Zone1" 0 "Off" ;
VAL_ 1233 RmtCtlRightOrnt_D_Avail 7 "NotUsed_3" 6 "NotUsed_2" 5 "NotUsed_1" 4 "Both" 3 "Backward" 2 "Forward" 1 "None" 0 "NotDetermined" ;
VAL_ 1233 RmtCtlRight_D_Avail 3 "NotUsed" 2 "Available" 1 "NotAvailable" 0 "Null" ;
VAL_ 1233 RmtCtlRear_D_Avail 3 "NotUsed" 2 "Available" 1 "NotAvailable" 0 "Null" ;
VAL_ 1233 RmtCtlPrkMde_D_Stat 3 "NotUsed" 2 "FreeDrive" 1 "ParkIn" 0 "None" ;
VAL_ 1233 RmtCtlPrkInSlot_D_Stat 7 "NotUsed_3" 6 "NotUsed_2" 5 "NotUsed_1" 4 "Right" 3 "Left" 2 "Rear" 1 "Front" 0 "None" ;
VAL_ 1233 RmtCtlObstcl_B_Stat 1 "Yes" 0 "No" ;
VAL_ 1233 RmtCtlNxtMoveDir_D_Stat 3 "NotUsed" 2 "Backward" 1 "Forward" 0 "Null" ;
VAL_ 1233 RmtCtlMoveDir_D_Stat 3 "NotUsed" 2 "Backward" 1 "Forward" 0 "None" ;
VAL_ 1233 RmtCtlLeftOrnt_D_Avail 7 "NotUsed_3" 6 "NotUsed_2" 5 "NotUsed_1" 4 "Both" 3 "Backward" 2 "Forward" 1 "None" 0 "NotDetermined" ;
VAL_ 1233 RmtCtlLeft_D_Avail 3 "NotUsed" 2 "Available" 1 "NotAvailable" 0 "Null" ;
VAL_ 1233 RmtCtlFront_D_Avail 3 "NotUsed" 2 "Available" 1 "NotAvailable" 0 "Null" ;
